VERSION "dbc-export 1 2026.26.6.5"

NS_ :

BS_:

BU_: BMS CP DAS DIF GTW HVP ICR PCS SCCM VCBATT VCFRONT VCFRONT1 VCLEFT VCRIGHT VCSEC

BO_ 1025 BMS_brickMeasurements: 8 BMS
 SG_ BMS_brickVoltageMultiplexer M : 0|8@1+ (1,0) [0|255] "" Vector__XXX
 SG_ BMS_brickVoltageCounter : 14|2@1+ (1,0) [0|3] "" Vector__XXX
 SG_ BMS_brickVoltageStatus1 m0 : 8|2@1+ (1,0) [0|3] "" Vector__XXX
 SG_ BMS_brickVoltageStatus2 m0 : 10|2@1+ (1,0) [0|3] "" Vector__XXX
 SG_ BMS_brickVoltageStatus3 m0 : 12|2@1+ (1,0) [0|3] "" Vector__XXX
 SG_ BMS_brickVoltage1 m0 : 16|16@1+ (0.0001,0) [0|5] "V" Vector__XXX
 SG_ BMS_brickVoltage2 m0 : 32|16@1+ (0.0001,0) [0|5] "V" Vector__XXX
 SG_ BMS_brickVoltage3 m0 : 48|16@1+ (0.0001,0) [0|5] "V" Vector__XXX
 SG_ BMS_brickVoltageStatus4 m1 : 8|2@1+ (1,0) [0|3] "" Vector__XXX
 SG_ BMS_brickVoltageStatus5 m1 : 10|2@1+ (1,0) [0|3] "" Vector__XXX
 SG_ BMS_brickVoltageStatus6 m1 : 12|2@1+ (1,0) [0|3] "" Vector__XXX
 SG_ BMS_brickVoltage4 m1 : 16|16@1+ (0.0001,0) [0|5] "V" Vector__XXX
 SG_ BMS_brickVoltage5 m1 : 32|16@1+ (0.0001,0) [0|5] "V" Vector__XXX
 SG_ BMS_brickVoltage6 m1 : 48|16@1+ (0.0001,0) [0|5] "V" Vector__XXX
 SG_ BMS_brickVoltageStatus7 m2 : 8|2@1+ (1,0) [0|3] "" Vector__XXX
 SG_ BMS_brickVoltageStatus8 m2 : 10|2@1+ (1,0) [0|3] "" Vector__XXX
 SG_ BMS_brickVoltageStatus9 m2 : 12|2@1+ (1,0) [0|3] "" Vector__XXX
 SG_ BMS_brickVoltage7 m2 : 16|16@1+ (0.0001,0) [0|5] "V" Vector__XXX
 SG_ BMS_brickVoltage8 m2 : 32|16@1+ (0.0001,0) [0|5] "V" Vector__XXX
 SG_ BMS_brickVoltage9 m2 : 48|16@1+ (0.0001,0) [0|5] "V" Vector__XXX
 SG_ BMS_brickVoltageStatus10 m3 : 8|2@1+ (1,0) [0|3] "" Vector__XXX
 SG_ BMS_brickVoltageStatus11 m3 : 10|2@1+ (1,0) [0|3] "" Vector__XXX
 SG_ BMS_brickVoltageStatus12 m3 : 12|2@1+ (1,0) [0|3] "" Vector__XXX
 SG_ BMS_brickVoltage10 m3 : 16|16@1+ (0.0001,0) [0|5] "V" Vector__XXX
 SG_ BMS_brickVoltage11 m3 : 32|16@1+ (0.0001,0) [0|5] "V" Vector__XXX
 SG_ BMS_brickVoltage12 m3 : 48|16@1+ (0.0001,0) [0|5] "V" Vector__XXX
 SG_ BMS_brickVoltageStatus13 m4 : 8|2@1+ (1,0) [0|3] "" Vector__XXX
 SG_ BMS_brickVoltageStatus14 m4 : 10|2@1+ (1,0) [0|3] "" Vector__XXX
 SG_ BMS_brickVoltageStatus15 m4 : 12|2@1+ (1,0) [0|3] "" Vector__XXX
 SG_ BMS_brickVoltage13 m4 : 16|16@1+ (0.0001,0) [0|5] "V" Vector__XXX
 SG_ BMS_brickVoltage14 m4 : 32|16@1+ (0.0001,0) [0|5] "V" Vector__XXX
 SG_ BMS_brickVoltage15 m4 : 48|16@1+ (0.0001,0) [0|5] "V" Vector__XXX
 SG_ BMS_brickVoltageStatus16 m5 : 8|2@1+ (1,0) [0|3] "" Vector__XXX
 SG_ BMS_brickVoltageStatus17 m5 : 10|2@1+ (1,0) [0|3] "" Vector__XXX
 SG_ BMS_brickVoltageStatus18 m5 : 12|2@1+ (1,0) [0|3] "" Vector__XXX
 SG_ BMS_brickVoltage16 m5 : 16|16@1+ (0.0001,0) [0|5] "V" Vector__XXX
 SG_ BMS_brickVoltage17 m5 : 32|16@1+ (0.0001,0) [0|5] "V" Vector__XXX
 SG_ BMS_brickVoltage18 m5 : 48|16@1+ (0.0001,0) [0|5] "V" Vector__XXX
 SG_ BMS_brickVoltageStatus19 m6 : 8|2@1+ (1,0) [0|3] "" Vector__XXX
 SG_ BMS_brickVoltageStatus20 m6 : 10|2@1+ (1,0) [0|3] "" Vector__XXX
 SG_ BMS_brickVoltageStatus21 m6 : 12|2@1+ (1,0) [0|3] "" Vector__XXX
 SG_ BMS_brickVoltage19 m6 : 16|16@1+ (0.0001,0) [0|5] "V" Vector__XXX
 SG_ BMS_brickVoltage20 m6 : 32|16@1+ (0.0001,0) [0|5] "V" Vector__XXX
 SG_ BMS_brickVoltage21 m6 : 48|16@1+ (0.0001,0) [0|5] "V" Vector__XXX
 SG_ BMS_brickVoltageStatus22 m7 : 8|2@1+ (1,0) [0|3] "" Vector__XXX
 SG_ BMS_brickVoltageStatus23 m7 : 10|2@1+ (1,0) [0|3] "" Vector__XXX
 SG_ BMS_brickVoltageStatus24 m7 : 12|2@1+ (1,0) [0|3] "" Vector__XXX
 SG_ BMS_brickVoltage22 m7 : 16|16@1+ (0.0001,0) [0|5] "V" Vector__XXX
 SG_ BMS_brickVoltage23 m7 : 32|16@1+ (0.0001,0) [0|5] "V" Vector__XXX
 SG_ BMS_brickVoltage24 m7 : 48|16@1+ (0.0001,0) [0|5] "V" Vector__XXX
 SG_ BMS_brickVoltageStatus25 m8 : 8|2@1+ (1,0) [0|3] "" Vector__XXX
 SG_ BMS_brickVoltageStatus26 m8 : 10|2@1+ (1,0) [0|3] "" Vector__XXX
 SG_ BMS_brickVoltageStatus27 m8 : 12|2@1+ (1,0) [0|3] "" Vector__XXX
 SG_ BMS_brickVoltage25 m8 : 16|16@1+ (0.0001,0) [0|5] "V" Vector__XXX
 SG_ BMS_brickVoltage26 m8 : 32|16@1+ (0.0001,0) [0|5] "V" Vector__XXX
 SG_ BMS_brickVoltage27 m8 : 48|16@1+ (0.0001,0) [0|5] "V" Vector__XXX
 SG_ BMS_brickVoltageStatus28 m9 : 8|2@1+ (1,0) [0|3] "" Vector__XXX
 SG_ BMS_brickVoltageStatus29 m9 : 10|2@1+ (1,0) [0|3] "" Vector__XXX
 SG_ BMS_brickVoltageStatus30 m9 : 12|2@1+ (1,0) [0|3] "" Vector__XXX
 SG_ BMS_brickVoltage28 m9 : 16|16@1+ (0.0001,0) [0|5] "V" Vector__XXX
 SG_ BMS_brickVoltage29 m9 : 32|16@1+ (0.0001,0) [0|5] "V" Vector__XXX
 SG_ BMS_brickVoltage30 m9 : 48|16@1+ (0.0001,0) [0|5] "V" Vector__XXX
 SG_ BMS_brickVoltageStatus31 m10 : 8|2@1+ (1,0) [0|3] "" Vector__XXX
 SG_ BMS_brickVoltageStatus32 m10 : 10|2@1+ (1,0) [0|3] "" Vector__XXX
 SG_ BMS_brickVoltageStatus33 m10 : 12|2@1+ (1,0) [0|3] "" Vector__XXX
 SG_ BMS_brickVoltage31 m10 : 16|16@1+ (0.0001,0) [0|5] "V" Vector__XXX
 SG_ BMS_brickVoltage32 m10 : 32|16@1+ (0.0001,0) [0|5] "V" Vector__XXX
 SG_ BMS_brickVoltage33 m10 : 48|16@1+ (0.0001,0) [0|5] "V" Vector__XXX
 SG_ BMS_brickVoltageStatus34 m11 : 8|2@1+ (1,0) [0|3] "" Vector__XXX
 SG_ BMS_brickVoltageStatus35 m11 : 10|2@1+ (1,0) [0|3] "" Vector__XXX
 SG_ BMS_brickVoltageStatus36 m11 : 12|2@1+ (1,0) [0|3] "" Vector__XXX
 SG_ BMS_brickVoltage34 m11 : 16|16@1+ (0.0001,0) [0|5] "V" Vector__XXX
 SG_ BMS_brickVoltage35 m11 : 32|16@1+ (0.0001,0) [0|5] "V" Vector__XXX
 SG_ BMS_brickVoltage36 m11 : 48|16@1+ (0.0001,0) [0|5] "V" Vector__XXX
 SG_ BMS_brickVoltageStatus37 m12 : 8|2@1+ (1,0) [0|3] "" Vector__XXX
 SG_ BMS_brickVoltageStatus38 m12 : 10|2@1+ (1,0) [0|3] "" Vector__XXX
 SG_ BMS_brickVoltageStatus39 m12 : 12|2@1+ (1,0) [0|3] "" Vector__XXX
 SG_ BMS_brickVoltage37 m12 : 16|16@1+ (0.0001,0) [0|5] "V" Vector__XXX
 SG_ BMS_brickVoltage38 m12 : 32|16@1+ (0.0001,0) [0|5] "V" Vector__XXX
 SG_ BMS_brickVoltage39 m12 : 48|16@1+ (0.0001,0) [0|5] "V" Vector__XXX
 SG_ BMS_brickVoltageStatus40 m13 : 8|2@1+ (1,0) [0|3] "" Vector__XXX
 SG_ BMS_brickVoltageStatus41 m13 : 10|2@1+ (1,0) [0|3] "" Vector__XXX
 SG_ BMS_brickVoltageStatus42 m13 : 12|2@1+ (1,0) [0|3] "" Vector__XXX
 SG_ BMS_brickVoltage40 m13 : 16|16@1+ (0.0001,0) [0|5] "V" Vector__XXX
 SG_ BMS_brickVoltage41 m13 : 32|16@1+ (0.0001,0) [0|5] "V" Vector__XXX
 SG_ BMS_brickVoltage42 m13 : 48|16@1+ (0.0001,0) [0|5] "V" Vector__XXX
 SG_ BMS_brickVoltageStatus43 m14 : 8|2@1+ (1,0) [0|3] "" Vector__XXX
 SG_ BMS_brickVoltageStatus44 m14 : 10|2@1+ (1,0) [0|3] "" Vector__XXX
 SG_ BMS_brickVoltageStatus45 m14 : 12|2@1+ (1,0) [0|3] "" Vector__XXX
 SG_ BMS_brickVoltage43 m14 : 16|16@1+ (0.0001,0) [0|5] "V" Vector__XXX
 SG_ BMS_brickVoltage44 m14 : 32|16@1+ (0.0001,0) [0|5] "V" Vector__XXX
 SG_ BMS_brickVoltage45 m14 : 48|16@1+ (0.0001,0) [0|5] "V" Vector__XXX
 SG_ BMS_brickVoltageStatus46 m15 : 8|2@1+ (1,0) [0|3] "" Vector__XXX
 SG_ BMS_brickVoltageStatus47 m15 : 10|2@1+ (1,0) [0|3] "" Vector__XXX
 SG_ BMS_brickVoltageStatus48 m15 : 12|2@1+ (1,0) [0|3] "" Vector__XXX
 SG_ BMS_brickVoltage46 m15 : 16|16@1+ (0.0001,0) [0|5] "V" Vector__XXX
 SG_ BMS_brickVoltage47 m15 : 32|16@1+ (0.0001,0) [0|5] "V" Vector__XXX
 SG_ BMS_brickVoltage48 m15 : 48|16@1+ (0.0001,0) [0|5] "V" Vector__XXX
 SG_ BMS_brickVoltageStatus49 m16 : 8|2@1+ (1,0) [0|3] "" Vector__XXX
 SG_ BMS_brickVoltageStatus50 m16 : 10|2@1+ (1,0) [0|3] "" Vector__XXX
 SG_ BMS_brickVoltageStatus51 m16 : 12|2@1+ (1,0) [0|3] "" Vector__XXX
 SG_ BMS_brickVoltage49 m16 : 16|16@1+ (0.0001,0) [0|5] "V" Vector__XXX
 SG_ BMS_brickVoltage50 m16 : 32|16@1+ (0.0001,0) [0|5] "V" Vector__XXX
 SG_ BMS_brickVoltage51 m16 : 48|16@1+ (0.0001,0) [0|5] "V" Vector__XXX
 SG_ BMS_brickVoltageStatus52 m17 : 8|2@1+ (1,0) [0|3] "" Vector__XXX
 SG_ BMS_brickVoltageStatus53 m17 : 10|2@1+ (1,0) [0|3] "" Vector__XXX
 SG_ BMS_brickVoltageStatus54 m17 : 12|2@1+ (1,0) [0|3] "" Vector__XXX
 SG_ BMS_brickVoltage52 m17 : 16|16@1+ (0.0001,0) [0|5] "V" Vector__XXX
 SG_ BMS_brickVoltage53 m17 : 32|16@1+ (0.0001,0) [0|5] "V" Vector__XXX
 SG_ BMS_brickVoltage54 m17 : 48|16@1+ (0.0001,0) [0|5] "V" Vector__XXX
 SG_ BMS_brickVoltageStatus55 m18 : 8|2@1+ (1,0) [0|3] "" Vector__XXX
 SG_ BMS_brickVoltageStatus56 m18 : 10|2@1+ (1,0) [0|3] "" Vector__XXX
 SG_ BMS_brickVoltageStatus57 m18 : 12|2@1+ (1,0) [0|3] "" Vector__XXX
 SG_ BMS_brickVoltage55 m18 : 16|16@1+ (0.0001,0) [0|5] "V" Vector__XXX
 SG_ BMS_brickVoltage56 m18 : 32|16@1+ (0.0001,0) [0|5] "V" Vector__XXX
 SG_ BMS_brickVoltage57 m18 : 48|16@1+ (0.0001,0) [0|5] "V" Vector__XXX
 SG_ BMS_brickVoltageStatus58 m19 : 8|2@1+ (1,0) [0|3] "" Vector__XXX
 SG_ BMS_brickVoltageStatus59 m19 : 10|2@1+ (1,0) [0|3] "" Vector__XXX
 SG_ BMS_brickVoltageStatus60 m19 : 12|2@1+ (1,0) [0|3] "" Vector__XXX
 SG_ BMS_brickVoltage58 m19 : 16|16@1+ (0.0001,0) [0|5] "V" Vector__XXX
 SG_ BMS_brickVoltage59 m19 : 32|16@1+ (0.0001,0) [0|5] "V" Vector__XXX
 SG_ BMS_brickVoltage60 m19 : 48|16@1+ (0.0001,0) [0|5] "V" Vector__XXX
 SG_ BMS_brickVoltageStatus61 m20 : 8|2@1+ (1,0) [0|3] "" Vector__XXX
 SG_ BMS_brickVoltageStatus62 m20 : 10|2@1+ (1,0) [0|3] "" Vector__XXX
 SG_ BMS_brickVoltageStatus63 m20 : 12|2@1+ (1,0) [0|3] "" Vector__XXX
 SG_ BMS_brickVoltage61 m20 : 16|16@1+ (0.0001,0) [0|5] "V" Vector__XXX
 SG_ BMS_brickVoltage62 m20 : 32|16@1+ (0.0001,0) [0|5] "V" Vector__XXX
 SG_ BMS_brickVoltage63 m20 : 48|16@1+ (0.0001,0) [0|5] "V" Vector__XXX
 SG_ BMS_brickVoltageStatus64 m21 : 8|2@1+ (1,0) [0|3] "" Vector__XXX
 SG_ BMS_brickVoltageStatus65 m21 : 10|2@1+ (1,0) [0|3] "" Vector__XXX
 SG_ BMS_brickVoltageStatus66 m21 : 12|2@1+ (1,0) [0|3] "" Vector__XXX
 SG_ BMS_brickVoltage64 m21 : 16|16@1+ (0.0001,0) [0|5] "V" Vector__XXX
 SG_ BMS_brickVoltage65 m21 : 32|16@1+ (0.0001,0) [0|5] "V" Vector__XXX
 SG_ BMS_brickVoltage66 m21 : 48|16@1+ (0.0001,0) [0|5] "V" Vector__XXX
 SG_ BMS_brickVoltageStatus67 m22 : 8|2@1+ (1,0) [0|3] "" Vector__XXX
 SG_ BMS_brickVoltageStatus68 m22 : 10|2@1+ (1,0) [0|3] "" Vector__XXX
 SG_ BMS_brickVoltageStatus69 m22 : 12|2@1+ (1,0) [0|3] "" Vector__XXX
 SG_ BMS_brickVoltage67 m22 : 16|16@1+ (0.0001,0) [0|5] "V" Vector__XXX
 SG_ BMS_brickVoltage68 m22 : 32|16@1+ (0.0001,0) [0|5] "V" Vector__XXX
 SG_ BMS_brickVoltage69 m22 : 48|16@1+ (0.0001,0) [0|5] "V" Vector__XXX
 SG_ BMS_brickVoltageStatus70 m23 : 8|2@1+ (1,0) [0|3] "" Vector__XXX
 SG_ BMS_brickVoltageStatus71 m23 : 10|2@1+ (1,0) [0|3] "" Vector__XXX
 SG_ BMS_brickVoltageStatus72 m23 : 12|2@1+ (1,0) [0|3] "" Vector__XXX
 SG_ BMS_brickVoltage70 m23 : 16|16@1+ (0.0001,0) [0|5] "V" Vector__XXX
 SG_ BMS_brickVoltage71 m23 : 32|16@1+ (0.0001,0) [0|5] "V" Vector__XXX
 SG_ BMS_brickVoltage72 m23 : 48|16@1+ (0.0001,0) [0|5] "V" Vector__XXX
 SG_ BMS_brickVoltageStatus73 m24 : 8|2@1+ (1,0) [0|3] "" Vector__XXX
 SG_ BMS_brickVoltageStatus74 m24 : 10|2@1+ (1,0) [0|3] "" Vector__XXX
 SG_ BMS_brickVoltageStatus75 m24 : 12|2@1+ (1,0) [0|3] "" Vector__XXX
 SG_ BMS_brickVoltage73 m24 : 16|16@1+ (0.0001,0) [0|5] "V" Vector__XXX
 SG_ BMS_brickVoltage74 m24 : 32|16@1+ (0.0001,0) [0|5] "V" Vector__XXX
 SG_ BMS_brickVoltage75 m24 : 48|16@1+ (0.0001,0) [0|5] "V" Vector__XXX
 SG_ BMS_brickVoltageStatus76 m25 : 8|2@1+ (1,0) [0|3] "" Vector__XXX
 SG_ BMS_brickVoltageStatus77 m25 : 10|2@1+ (1,0) [0|3] "" Vector__XXX
 SG_ BMS_brickVoltageStatus78 m25 : 12|2@1+ (1,0) [0|3] "" Vector__XXX
 SG_ BMS_brickVoltage76 m25 : 16|16@1+ (0.0001,0) [0|5] "V" Vector__XXX
 SG_ BMS_brickVoltage77 m25 : 32|16@1+ (0.0001,0) [0|5] "V" Vector__XXX
 SG_ BMS_brickVoltage78 m25 : 48|16@1+ (0.0001,0) [0|5] "V" Vector__XXX
 SG_ BMS_brickVoltageStatus79 m26 : 8|2@1+ (1,0) [0|3] "" Vector__XXX
 SG_ BMS_brickVoltageStatus80 m26 : 10|2@1+ (1,0) [0|3] "" Vector__XXX
 SG_ BMS_brickVoltageStatus81 m26 : 12|2@1+ (1,0) [0|3] "" Vector__XXX
 SG_ BMS_brickVoltage79 m26 : 16|16@1+ (0.0001,0) [0|5] "V" Vector__XXX
 SG_ BMS_brickVoltage80 m26 : 32|16@1+ (0.0001,0) [0|5] "V" Vector__XXX
 SG_ BMS_brickVoltage81 m26 : 48|16@1+ (0.0001,0) [0|5] "V" Vector__XXX
 SG_ BMS_brickVoltageStatus82 m27 : 8|2@1+ (1,0) [0|3] "" Vector__XXX
 SG_ BMS_brickVoltageStatus83 m27 : 10|2@1+ (1,0) [0|3] "" Vector__XXX
 SG_ BMS_brickVoltageStatus84 m27 : 12|2@1+ (1,0) [0|3] "" Vector__XXX
 SG_ BMS_brickVoltage82 m27 : 16|16@1+ (0.0001,0) [0|5] "V" Vector__XXX
 SG_ BMS_brickVoltage83 m27 : 32|16@1+ (0.0001,0) [0|5] "V" Vector__XXX
 SG_ BMS_brickVoltage84 m27 : 48|16@1+ (0.0001,0) [0|5] "V" Vector__XXX
 SG_ BMS_brickVoltageStatus85 m28 : 8|2@1+ (1,0) [0|3] "" Vector__XXX
 SG_ BMS_brickVoltageStatus86 m28 : 10|2@1+ (1,0) [0|3] "" Vector__XXX
 SG_ BMS_brickVoltageStatus87 m28 : 12|2@1+ (1,0) [0|3] "" Vector__XXX
 SG_ BMS_brickVoltage85 m28 : 16|16@1+ (0.0001,0) [0|5] "V" Vector__XXX
 SG_ BMS_brickVoltage86 m28 : 32|16@1+ (0.0001,0) [0|5] "V" Vector__XXX
 SG_ BMS_brickVoltage87 m28 : 48|16@1+ (0.0001,0) [0|5] "V" Vector__XXX
 SG_ BMS_brickVoltageStatus88 m29 : 8|2@1+ (1,0) [0|3] "" Vector__XXX
 SG_ BMS_brickVoltageStatus89 m29 : 10|2@1+ (1,0) [0|3] "" Vector__XXX
 SG_ BMS_brickVoltageStatus90 m29 : 12|2@1+ (1,0) [0|3] "" Vector__XXX
 SG_ BMS_brickVoltage88 m29 : 16|16@1+ (0.0001,0) [0|5] "V" Vector__XXX
 SG_ BMS_brickVoltage89 m29 : 32|16@1+ (0.0001,0) [0|5] "V" Vector__XXX
 SG_ BMS_brickVoltage90 m29 : 48|16@1+ (0.0001,0) [0|5] "V" Vector__XXX
 SG_ BMS_brickVoltageStatus91 m30 : 8|2@1+ (1,0) [0|3] "" Vector__XXX
 SG_ BMS_brickVoltageStatus92 m30 : 10|2@1+ (1,0) [0|3] "" Vector__XXX
 SG_ BMS_brickVoltageStatus93 m30 : 12|2@1+ (1,0) [0|3] "" Vector__XXX
 SG_ BMS_brickVoltage91 m30 : 16|16@1+ (0.0001,0) [0|5] "V" Vector__XXX
 SG_ BMS_brickVoltage92 m30 : 32|16@1+ (0.0001,0) [0|5] "V" Vector__XXX
 SG_ BMS_brickVoltage93 m30 : 48|16@1+ (0.0001,0) [0|5] "V" Vector__XXX
 SG_ BMS_brickVoltageStatus94 m31 : 8|2@1+ (1,0) [0|3] "" Vector__XXX
 SG_ BMS_brickVoltageStatus95 m31 : 10|2@1+ (1,0) [0|3] "" Vector__XXX
 SG_ BMS_brickVoltageStatus96 m31 : 12|2@1+ (1,0) [0|3] "" Vector__XXX
 SG_ BMS_brickVoltage94 m31 : 16|16@1+ (0.0001,0) [0|5] "V" Vector__XXX
 SG_ BMS_brickVoltage95 m31 : 32|16@1+ (0.0001,0) [0|5] "V" Vector__XXX
 SG_ BMS_brickVoltage96 m31 : 48|16@1+ (0.0001,0) [0|5] "V" Vector__XXX
 SG_ BMS_brickVoltageStatus97 m32 : 8|2@1+ (1,0) [0|3] "" Vector__XXX
 SG_ BMS_brickVoltageStatus98 m32 : 10|2@1+ (1,0) [0|3] "" Vector__XXX
 SG_ BMS_brickVoltageStatus99 m32 : 12|2@1+ (1,0) [0|3] "" Vector__XXX
 SG_ BMS_brickVoltage97 m32 : 16|16@1+ (0.0001,0) [0|5] "V" Vector__XXX
 SG_ BMS_brickVoltage98 m32 : 32|16@1+ (0.0001,0) [0|5] "V" Vector__XXX
 SG_ BMS_brickVoltage99 m32 : 48|16@1+ (0.0001,0) [0|5] "V" Vector__XXX
 SG_ BMS_brickVoltageStatus100 m33 : 8|2@1+ (1,0) [0|3] "" Vector__XXX
 SG_ BMS_brickVoltageStatus101 m33 : 10|2@1+ (1,0) [0|3] "" Vector__XXX
 SG_ BMS_brickVoltageStatus102 m33 : 12|2@1+ (1,0) [0|3] "" Vector__XXX
 SG_ BMS_brickVoltage100 m33 : 16|16@1+ (0.0001,0) [0|5] "V" Vector__XXX
 SG_ BMS_brickVoltage101 m33 : 32|16@1+ (0.0001,0) [0|5] "V" Vector__XXX
 SG_ BMS_brickVoltage102 m33 : 48|16@1+ (0.0001,0) [0|5] "V" Vector__XXX
 SG_ BMS_brickVoltageStatus103 m34 : 8|2@1+ (1,0) [0|3] "" Vector__XXX
 SG_ BMS_brickVoltageStatus104 m34 : 10|2@1+ (1,0) [0|3] "" Vector__XXX
 SG_ BMS_brickVoltageStatus105 m34 : 12|2@1+ (1,0) [0|3] "" Vector__XXX
 SG_ BMS_brickVoltage103 m34 : 16|16@1+ (0.0001,0) [0|5] "V" Vector__XXX
 SG_ BMS_brickVoltage104 m34 : 32|16@1+ (0.0001,0) [0|5] "V" Vector__XXX
 SG_ BMS_brickVoltage105 m34 : 48|16@1+ (0.0001,0) [0|5] "V" Vector__XXX
 SG_ BMS_brickVoltageStatus106 m35 : 8|2@1+ (1,0) [0|3] "" Vector__XXX
 SG_ BMS_brickVoltageStatus107 m35 : 10|2@1+ (1,0) [0|3] "" Vector__XXX
 SG_ BMS_brickVoltageStatus108 m35 : 12|2@1+ (1,0) [0|3] "" Vector__XXX
 SG_ BMS_brickVoltage106 m35 : 16|16@1+ (0.0001,0) [0|5] "V" Vector__XXX
 SG_ BMS_brickVoltage107 m35 : 32|16@1+ (0.0001,0) [0|5] "V" Vector__XXX
 SG_ BMS_brickVoltage108 m35 : 48|16@1+ (0.0001,0) [0|5] "V" Vector__XXX

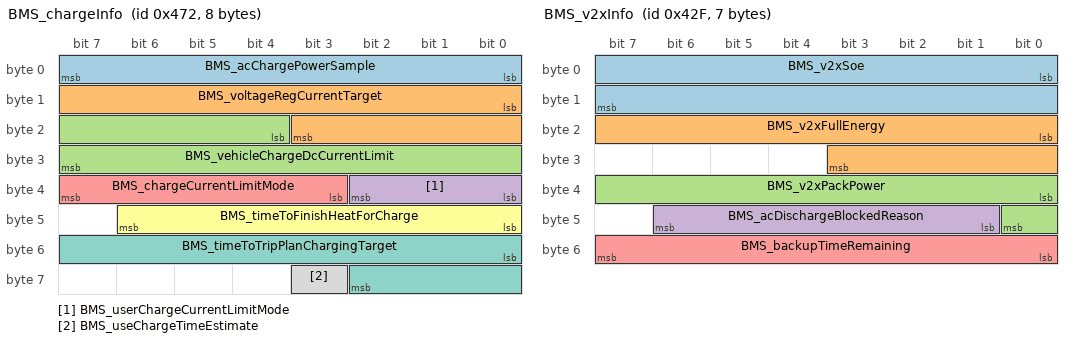
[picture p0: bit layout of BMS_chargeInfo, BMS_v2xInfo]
BO_ 1138 BMS_chargeInfo: 8 BMS
 SG_ BMS_acChargePowerSample : 0|8@1+ (0.1,0) [0|25] "kW" Vector__XXX
 SG_ BMS_voltageRegCurrentTarget : 8|12@1+ (0.5,0) [0|2047.5] "A" Vector__XXX
 SG_ BMS_vehicleChargeDcCurrentLimit : 20|12@1+ (0.5,0) [0|2047.5] "A" Vector__XXX
 SG_ BMS_userChargeCurrentLimitMode : 32|3@1+ (1,0) [0|7] "" Vector__XXX
 SG_ BMS_chargeCurrentLimitMode : 35|5@1+ (1,0) [0|31] "" Vector__XXX
 SG_ BMS_timeToFinishHeatForCharge : 40|7@1+ (5,0) [0|600] "min" Vector__XXX
 SG_ BMS_timeToTripPlanChargingTarget : 48|11@1+ (1,0) [0|2046] "min" Vector__XXX
 SG_ BMS_useChargeTimeEstimate : 59|1@1+ (1,0) [0|1] "" Vector__XXX

BO_ 1071 BMS_v2xInfo: 7 BMS
 SG_ BMS_v2xSoe : 0|16@1+ (0.002,0) [0|100] "%" Vector__XXX
 SG_ BMS_v2xFullEnergy : 16|12@1+ (0.05,0) [0|200] "kWh" Vector__XXX
 SG_ BMS_v2xPackPower : 32|9@1+ (0.1,-25) [-25|25] "kW" Vector__XXX
 SG_ BMS_acDischargeBlockedReason : 41|6@1+ (1,0) [0|63] "" Vector__XXX
 SG_ BMS_backupTimeRemaining : 48|8@1+ (1,0) [0|254] "Hours" Vector__XXX

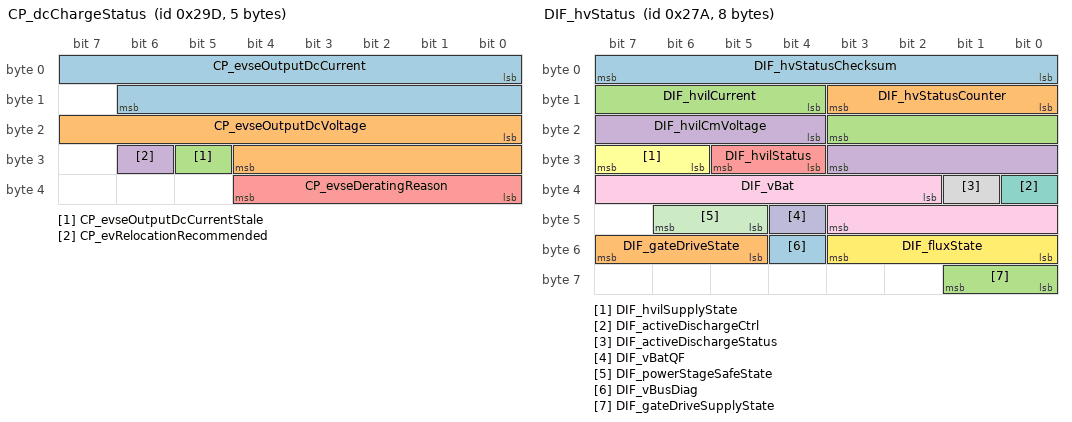
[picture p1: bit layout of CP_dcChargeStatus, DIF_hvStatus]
BO_ 669 CP_dcChargeStatus: 5 CP
 SG_ CP_evseOutputDcCurrent : 0|15@1- (0.125,0) [-2048|2047.875] "A" Vector__XXX
 SG_ CP_evseOutputDcVoltage : 16|13@1+ (0.07324219,0) [0|599.92675822] "V" Vector__XXX
 SG_ CP_evseOutputDcCurrentStale : 29|1@1+ (1,0) [0|1] "" Vector__XXX
 SG_ CP_evRelocationRecommended : 30|1@1+ (1,0) [0|1] "" Vector__XXX
 SG_ CP_evseDeratingReason : 32|5@1+ (1,0) [0|31] "" Vector__XXX

BO_ 541 CP_evseStatus: 8 CP
 SG_ CP_evseAccept : 0|1@1+ (1,0) [0|1] "" Vector__XXX
 SG_ CP_evseRequest : 1|1@1+ (1,0) [0|1] "" Vector__XXX
 SG_ CP_proximity : 2|2@1+ (1,0) [1|3] "" Vector__XXX
 SG_ CP_pilot : 4|3@1+ (1,0) [0|6] "" Vector__XXX
 SG_ CP_digitalCommsEstablished : 7|1@1+ (1,0) [0|1] "" Vector__XXX
 SG_ CP_pilotCurrent : 8|8@1+ (0.5,0) [0|127.5] "A" Vector__XXX
 SG_ CP_cableType : 16|3@1+ (1,0) [0|7] "" Vector__XXX
 SG_ CP_iecPilotState : 19|4@1+ (1,0) [0|15] "" Vector__XXX
 SG_ CP_plcSupported : 23|1@1+ (1,0) [0|1] "" Vector__XXX
 SG_ CP_cableCurrentLimit : 24|7@1+ (1,0) [0|127] "A" Vector__XXX
 SG_ CP_teslaSwcanState : 34|4@1+ (1,0) [0|15] "" Vector__XXX
 SG_ CP_evseChargeType_UI : 38|2@1+ (1,0) [0|3] "" Vector__XXX
 SG_ CP_gbState : 40|4@1+ (1,0) [0|15] "" Vector__XXX
 SG_ CP_gbdcStopChargeReason : 44|4@1+ (1,0) [0|15] "" Vector__XXX
 SG_ CP_gbdcFailureReason : 48|2@1+ (1,0) [0|3] "" Vector__XXX
 SG_ CP_gbdcChargeAttempts : 50|2@1+ (1,0) [0|3] "" Vector__XXX
 SG_ CP_acChargeState : 52|3@1+ (1,0) [0|7] "" Vector__XXX
 SG_ CP_acChargeType : 56|2@1+ (1,0) [0|3] "" Vector__XXX
 SG_ CP_teslaDcState : 58|4@1+ (1,0) [0|15] "" Vector__XXX

BO_ 1001 DAS_bodyControls: 8 DAS
 SG_ DAS_headlightRequest : 0|2@1+ (1,0) [0|3] "" Vector__XXX
 SG_ DAS_hazardLightRequest : 2|2@1+ (1,0) [0|2] "" Vector__XXX
 SG_ DAS_wiperSpeed : 4|4@1+ (1,0) [0|15] "" Vector__XXX
 SG_ DAS_turnIndicatorRequest : 8|3@1+ (1,0) [0|7] "" Vector__XXX
 SG_ DAS_highLowBeamDecision : 11|2@1+ (1,0) [0|2] "" Vector__XXX
 SG_ DAS_heaterRequest : 13|2@1+ (1,0) [1|3] "" Vector__XXX
 SG_ DAS_highLowBeamOffReason : 15|3@1+ (1,0) [0|7] "" Vector__XXX
 SG_ DAS_forwardCamHeaterDutyCycle : 18|4@1+ (0.06666667,0) [0|1] "-" Vector__XXX
 SG_ DAS_dynamicBrakeLightRequest : 22|1@1+ (1,0) [0|1] "" Vector__XXX
 SG_ DAS_radarHeaterRequest : 23|1@1+ (1,0) [0|1] "" Vector__XXX
 SG_ DAS_ahlbOverride : 24|1@1+ (1,0) [0|1] "" Vector__XXX
 SG_ DAS_mirrorFoldRequest : 25|2@1+ (1,0) [0|2] "" Vector__XXX
 SG_ DAS_wiperWashRequest : 27|1@1+ (1,0) [0|1] "" Vector__XXX
 SG_ DAS_ulcConfirmationRequestActive : 28|1@1+ (1,0) [0|1] "" Vector__XXX
 SG_ DAS_overrideWiperSetting : 29|1@1+ (1,0) [0|1] "" Vector__XXX
 SG_ DAS_autoWiperState : 30|3@1+ (1,0) [0|7] "" Vector__XXX
 SG_ DAS_turnIndicatorRequestReason : 33|5@1+ (1,0) [0|31] "" Vector__XXX
 SG_ DAS_forwardRadarPowerRequest : 38|1@1+ (1,0) [0|1] "" Vector__XXX
 SG_ DAS_driverDomeLightRequest : 39|1@1+ (1,0) [0|1] "" Vector__XXX
 SG_ DAS_drivePowerStateRequest : 43|1@1+ (1,0) [0|1] "" Vector__XXX
 SG_ DAS_enableIcrDataCollection : 44|1@1+ (1,0) [0|1] "" Vector__XXX
 SG_ DAS_rPillarCamHeaterDutyCycle : 45|4@1+ (0.06666667,0) [0|1] "-" Vector__XXX
 SG_ DAS_adaptiveHighBeamIsFaulted : 49|1@1+ (1,0) [0|1] "" Vector__XXX
 SG_ DAS_restrictDoorReleaseLeft : 50|1@1+ (1,0) [0|1] "" Vector__XXX
 SG_ DAS_restrictDoorReleaseRight : 51|1@1+ (1,0) [0|1] "" Vector__XXX
 SG_ DAS_bodyControlsCounter : 52|4@1+ (1,0) [0|15] "" Vector__XXX
 SG_ DAS_bodyControlsChecksum : 56|8@1+ (1,0) [0|255] "" Vector__XXX

BO_ 634 DIF_hvStatus: 8 DIF
 SG_ DIF_hvStatusChecksum : 0|8@1+ (1,0) [0|255] "" Vector__XXX
 SG_ DIF_hvStatusCounter : 8|4@1+ (1,0) [0|15] "" Vector__XXX
 SG_ DIF_hvilCurrent : 12|8@1+ (0.1,0) [0|25.5] "mA" Vector__XXX
 SG_ DIF_hvilCmVoltage : 20|8@1+ (0.08,0) [0|20.4] "V" Vector__XXX
 SG_ DIF_hvilStatus : 28|2@1+ (1,0) [0|2] "" Vector__XXX
 SG_ DIF_hvilSupplyState : 30|2@1+ (1,0) [0|3] "" Vector__XXX
 SG_ DIF_activeDischargeCtrl : 32|1@1+ (1,0) [0|1] "" Vector__XXX
 SG_ DIF_activeDischargeStatus : 33|1@1+ (1,0) [0|1] "" Vector__XXX
 SG_ DIF_vBat : 34|10@1+ (1,0) [0|1023] "V" Vector__XXX
 SG_ DIF_vBatQF : 44|1@1+ (1,0) [0|1] "" Vector__XXX
 SG_ DIF_powerStageSafeState : 45|2@1+ (1,0) [0|3] "" Vector__XXX
 SG_ DIF_fluxState : 48|4@1+ (1,0) [0|15] "" Vector__XXX
 SG_ DIF_vBusDiag : 52|1@1+ (1,0) [0|1] "" Vector__XXX
 SG_ DIF_gateDriveState : 53|3@1+ (1,0) [0|7] "" Vector__XXX
 SG_ DIF_gateDriveSupplyState : 56|2@1+ (1,0) [0|3] "" Vector__XXX

BO_ 784 HVP_info: 8 HVP
 SG_ HVP_infoIndex M : 0|8@1+ (1,0) [0|255] "" Vector__XXX
 SG_ HVP_buildType m10 : 8|3@1+ (1,0) [0|7] "" Vector__XXX
 SG_ HVP_buildConfigId m10 : 16|16@1+ (1,0) [0|65535] "" Vector__XXX
 SG_ HVP_hardwareId m10 : 32|16@1+ (1,0) [0|65535] "" Vector__XXX
 SG_ HVP_componentId m10 : 48|16@1+ (1,0) [0|65535] "" Vector__XXX
 SG_ HVP_pcbaId m11 : 16|8@1+ (1,0) [0|255] "" Vector__XXX
 SG_ HVP_assemblyId m11 : 24|8@1+ (1,0) [0|255] "" Vector__XXX
 SG_ HVP_usageId m11 : 32|16@1+ (1,0) [0|65535] "" Vector__XXX
 SG_ HVP_subUsageId m11 : 48|16@1+ (1,0) [0|65535] "" Vector__XXX
 SG_ HVP_platformType m13 : 8|8@1+ (1,0) [0|255] "" Vector__XXX
 SG_ HVP_appCrc m13 : 32|32@1+ (1,0) [0|4294967295] "" Vector__XXX
 SG_ HVP_appGitHash m17 : 8|56@1+ (1,0) [0|7.20575940379e+16] "" Vector__XXX
 SG_ HVP_bootGitHash m18 : 8|56@1+ (1,0) [0|7.20575940379e+16] "" Vector__XXX
 SG_ HVP_bootUdsProtoVersion m20 : 8|8@1+ (1,0) [0|255] "" Vector__XXX
 SG_ HVP_bootCrc m20 : 32|32@1+ (1,0) [0|4294967295] "" Vector__XXX

BO_ 941 ICR_info: 8 ICR
 SG_ ICR_infoIndex M : 0|8@1+ (1,0) [0|255] "" Vector__XXX
 SG_ ICR_infoBuildType m10 : 8|3@1+ (1,0) [0|7] "" Vector__XXX
 SG_ ICR_infoPcbaId m11 : 32|8@1+ (1,0) [0|255] "" Vector__XXX
 SG_ ICR_infoAssemblyId m11 : 40|8@1+ (1,0) [0|255] "" Vector__XXX
 SG_ ICR_infoUsageId m11 : 48|16@1+ (1,0) [0|65535] "" Vector__XXX
 SG_ ICR_infoAppCrc m13 : 8|32@1+ (1,0) [0|4294967295] "" Vector__XXX
 SG_ ICR_infoBoardPartNumber17 m25 : 8|56@1+ (1,0) [0|7.20575940379e+16] "" Vector__XXX
 SG_ ICR_infoBoardPartNumber814 m26 : 8|56@1+ (1,0) [0|7.20575940379e+16] "" Vector__XXX
 SG_ ICR_infoBoardPartNumber1520 m27 : 8|48@1+ (1,0) [0|281474976710655] "" Vector__XXX

BO_ 964 PCS_info: 8 PCS
 SG_ PCS_infoIndex M : 0|8@1+ (1,0) [0|255] "" Vector__XXX
 SG_ PCS_buildType m10 : 8|8@1+ (1,0) [0|255] "" Vector__XXX
 SG_ PCS_buildConfigId m10 : 16|16@1+ (1,0) [0|65535] "" Vector__XXX
 SG_ PCS_hardwareId m10 : 32|16@1+ (1,0) [0|65535] "" Vector__XXX
 SG_ PCS_componentId m10 : 48|16@1+ (1,0) [0|65535] "" Vector__XXX
 SG_ PCS_pcbaId m11 : 16|8@1+ (1,0) [0|255] "" Vector__XXX
 SG_ PCS_assemblyId m11 : 24|8@1+ (1,0) [0|255] "" Vector__XXX
 SG_ PCS_usageId m11 : 32|16@1+ (1,0) [0|65535] "" Vector__XXX
 SG_ PCS_subUsageId m11 : 48|16@1+ (1,0) [0|65535] "" Vector__XXX
 SG_ PCS_platformType m13 : 8|8@1+ (1,0) [0|255] "" Vector__XXX
 SG_ PCS_appCrc m13 : 32|32@1+ (1,0) [0|4294967295] "" Vector__XXX
 SG_ PCS_cpu2AppCrc m16 : 32|32@1+ (1,0) [0|4294967295] "" Vector__XXX
 SG_ PCS_appGitHash m17 : 8|56@1+ (1,0) [0|7.20575940379e+16] "" Vector__XXX
 SG_ PCS_bootGitHash m18 : 8|56@1+ (1,0) [0|7.20575940379e+16] "" Vector__XXX
 SG_ PCS_bootUdsProtoVersion m20 : 8|8@1+ (1,0) [0|255] "" Vector__XXX
 SG_ PCS_bootCrc m20 : 32|32@1+ (1,0) [0|4294967295] "" Vector__XXX

BO_ 816 SCCM_info: 8 SCCM
 SG_ SCCM_infoIndex M : 0|8@1+ (1,0) [0|255] "" Vector__XXX
 SG_ SCCM_infoBuildType m10 : 8|8@1+ (1,0) [0|255] "" Vector__XXX
 SG_ SCCM_infoBuildConfigId m10 : 16|16@1+ (1,0) [0|65535] "" Vector__XXX
 SG_ SCCM_infoHardwareId m10 : 32|16@1+ (1,0) [0|65535] "" Vector__XXX
 SG_ SCCM_infoComponentId m10 : 48|16@1+ (1,0) [0|65535] "" Vector__XXX
 SG_ SCCM_infoPcbaId m11 : 16|8@1+ (1,0) [0|255] "" Vector__XXX
 SG_ SCCM_infoAssemblyId m11 : 24|8@1+ (1,0) [0|255] "" Vector__XXX
 SG_ SCCM_infoUsageId m11 : 32|16@1+ (1,0) [0|65535] "" Vector__XXX
 SG_ SCCM_infoSubUsageId m11 : 48|16@1+ (1,0) [0|65535] "" Vector__XXX
 SG_ SCCM_infoPlatformType m13 : 8|8@1+ (1,0) [0|255] "" Vector__XXX
 SG_ SCCM_infoAppCrc m13 : 39|32@0+ (1,0) [0|4294967295] "" Vector__XXX
 SG_ SCCM_infoBootSvnRev m14 : 8|24@1+ (1,0) [0|16777215] "" Vector__XXX
 SG_ SCCM_infoBootSvnUrlHash m14 : 32|32@1+ (1,0) [0|4294967295] "" Vector__XXX
 SG_ SCCM_infoSubcomponent1Version m16 : 16|32@1+ (1,0) [0|4294967295] "" Vector__XXX
 SG_ SCCM_infoAppSvnHash m17 : 8|56@1+ (1,0) [0|7.20575940379e+16] "" Vector__XXX
 SG_ SCCM_infoBootSvnHash m18 : 8|56@1+ (1,0) [0|7.20575940379e+16] "" Vector__XXX
 SG_ SCCM_infoUdsProtoVersion m20 : 8|8@1+ (1,0) [0|255] "" Vector__XXX
 SG_ SCCM_infoBootCrc m20 : 32|32@1+ (1,0) [0|4294967295] "" Vector__XXX

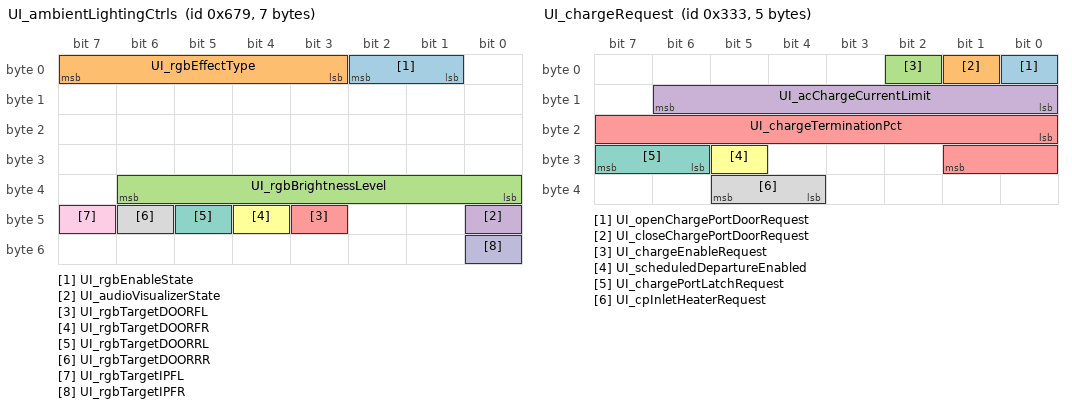
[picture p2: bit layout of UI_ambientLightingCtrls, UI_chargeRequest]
BO_ 1657 UI_ambientLightingCtrls: 7 GTW
 SG_ UI_rgbEnableState : 1|2@1+ (1,0) [0|3] "" Vector__XXX
 SG_ UI_rgbEffectType : 3|5@1+ (1,0) [0|31] "" Vector__XXX
 SG_ UI_rgbBrightnessLevel : 32|7@1+ (1,0) [0|100] "%" Vector__XXX
 SG_ UI_audioVisualizerState : 40|1@1+ (1,0) [0|1] "" Vector__XXX
 SG_ UI_rgbTargetDOORFL : 43|1@1+ (1,0) [0|1] "" Vector__XXX
 SG_ UI_rgbTargetDOORFR : 44|1@1+ (1,0) [0|1] "" Vector__XXX
 SG_ UI_rgbTargetDOORRL : 45|1@1+ (1,0) [0|1] "" Vector__XXX
 SG_ UI_rgbTargetDOORRR : 46|1@1+ (1,0) [0|1] "" Vector__XXX
 SG_ UI_rgbTargetIPFL : 47|1@1+ (1,0) [0|1] "" Vector__XXX
 SG_ UI_rgbTargetIPFR : 48|1@1+ (1,0) [0|1] "" Vector__XXX

BO_ 819 UI_chargeRequest: 5 GTW
 SG_ UI_openChargePortDoorRequest : 0|1@1+ (1,0) [0|1] "" Vector__XXX
 SG_ UI_closeChargePortDoorRequest : 1|1@1+ (1,0) [0|1] "" Vector__XXX
 SG_ UI_chargeEnableRequest : 2|1@1+ (1,0) [0|1] "" Vector__XXX
 SG_ UI_acChargeCurrentLimit : 8|7@1+ (1,0) [0|126] "A" Vector__XXX
 SG_ UI_chargeTerminationPct : 16|10@1+ (0.1,0) [5|100] "%" Vector__XXX
 SG_ UI_scheduledDepartureEnabled : 29|1@1+ (1,0) [0|1] "" Vector__XXX
 SG_ UI_chargePortLatchRequest : 30|2@1+ (1,0) [0|3] "" Vector__XXX
 SG_ UI_cpInletHeaterRequest : 36|2@1+ (1,0) [0|3] "" Vector__XXX

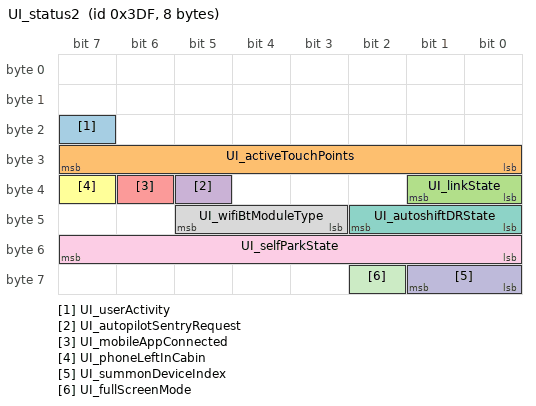
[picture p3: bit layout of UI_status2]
BO_ 991 UI_status2: 8 GTW
 SG_ UI_userActivity : 23|1@1+ (1,0) [0|1] "" Vector__XXX
 SG_ UI_activeTouchPoints : 24|8@1+ (1,0) [0|255] "1" Vector__XXX
 SG_ UI_linkState : 32|2@1+ (1,0) [0|3] "" Vector__XXX
 SG_ UI_autopilotSentryRequest : 37|1@1+ (1,0) [0|1] "" Vector__XXX
 SG_ UI_mobileAppConnected : 38|1@1+ (1,0) [0|1] "" Vector__XXX
 SG_ UI_phoneLeftInCabin : 39|1@1+ (1,0) [0|1] "" Vector__XXX
 SG_ UI_autoshiftDRState : 40|3@1+ (1,0) [0|7] "" Vector__XXX
 SG_ UI_wifiBtModuleType : 43|3@1+ (1,0) [0|7] "" Vector__XXX
 SG_ UI_selfParkState : 48|8@1+ (1,0) [0|254] "" Vector__XXX
 SG_ UI_summonDeviceIndex : 56|2@1+ (1,0) [0|3] "" Vector__XXX
 SG_ UI_fullScreenMode : 58|1@1+ (1,0) [0|1] "" Vector__XXX

BO_ 663 UI_suspensionControl: 8 GTW
 SG_ UI_adaptiveRideRequest : 3|2@1+ (1,0) [0|3] "" Vector__XXX
 SG_ UI_geofenceLevelingRequest : 7|3@1+ (1,0) [0|7] "" Vector__XXX

BO_ 947 UI_vehicleControl2: 8 GTW
 SG_ UI_gloveboxRequest : 0|1@1+ (1,0) [0|1] "" Vector__XXX
 SG_ UI_trunkRequest : 1|1@1+ (1,0) [0|1] "" Vector__XXX
 SG_ UI_PINToDriveEnabled : 6|1@1+ (1,0) [0|1] "" Vector__XXX
 SG_ UI_PINToDrivePassed : 7|1@1+ (1,0) [0|1] "" Vector__XXX
 SG_ UI_disableMirrorAutoDim : 8|1@1+ (1,0) [0|1] "" Vector__XXX
 SG_ UI_lightSwitch : 9|3@1+ (1,0) [0|7] "" Vector__XXX
 SG_ UI_readyToAddKey : 12|1@1+ (1,0) [0|1] "" Vector__XXX
 SG_ UI_alarmTriggerRequest : 13|1@1+ (1,0) [0|1] "" Vector__XXX
 SG_ UI_displayOnForUser : 18|1@1+ (1,0) [0|1] "" Vector__XXX
 SG_ UI_BLEPushNotificationRequest : 20|1@1+ (1,0) [0|1] "" Vector__XXX
 SG_ UI_keepAutopilotAwake : 22|1@1+ (1,0) [0|1] "" Vector__XXX
 SG_ UI_batteryPreconditioningRequest : 23|1@1+ (1,0) [0|1] "" Vector__XXX
 SG_ UI_autopilotPowerStateRequest : 25|2@1+ (1,0) [0|3] "" Vector__XXX
 SG_ UI_autoRollWindowsOnLockEnable : 29|1@1+ (1,0) [0|1] "" Vector__XXX
 SG_ UI_steeringWheelHeatReq : 33|1@1+ (1,0) [0|1] "" Vector__XXX
 SG_ UI_disableHorn : 34|1@1+ (1,0) [0|1] "" Vector__XXX
 SG_ UI_frontLeftSeatFanReq : 37|2@1+ (1,0) [0|3] "" Vector__XXX
 SG_ UI_frontRightSeatAutoClimateReq : 39|1@1+ (1,0) [0|1] "" Vector__XXX
 SG_ UI_frontRightSeatFanReq : 40|2@1+ (1,0) [0|3] "" Vector__XXX
 SG_ UI_3RLeftSeatHeatReq : 44|2@1+ (1,0) [0|3] "" Vector__XXX
 SG_ UI_3RRightSeatHeatReq : 46|2@1+ (1,0) [0|3] "" Vector__XXX
 SG_ UI_frontLeftSeatAutoClimateReq : 56|1@1+ (1,0) [0|1] "" Vector__XXX
 SG_ UI_wiperHeaterReq : 57|1@1+ (1,0) [0|1] "" Vector__XXX
 SG_ UI_silentAlarm : 61|1@1+ (1,0) [0|1] "" Vector__XXX

BO_ 1090 VCBATT_pcsInterface: 8 VCBATT
 SG_ VCBATT_pcsInterfaceMuxIndex M : 48|1@1+ (1,0) [0|1] "" Vector__XXX
 SG_ VCBATT_pcsInterfaceCounter : 50|4@1+ (1,0) [0|15] "" Vector__XXX
 SG_ VCBATT_pcsInterfaceChecksum : 56|8@1+ (1,0) [0|255] "" Vector__XXX
 SG_ VCBATT_pcsLVVoltageTarget m0 : 0|13@1+ (0.01,0) [0|65.535] "V" Vector__XXX
 SG_ VCBATT_pcsLVMinVoltageLimit m0 : 13|13@1+ (0.01,0) [0|65.535] "V" Vector__XXX
 SG_ VCBATT_pcsLVMaxVoltageLimit m0 : 27|13@1+ (0.01,0) [0|65.535] "V" Vector__XXX
 SG_ VCBATT_goodForPCSPowerCycle m0 : 46|1@1+ (1,0) [0|1] "" Vector__XXX
 SG_ VCBATT_LVBatteryCannotSupportVeh m0 : 47|1@1+ (1,0) [0|1] "" Vector__XXX
 SG_ VCBATT_pcsResistanceFiltered m1 : 0|16@1+ (0.01,0) [0|655.34] "mOhm" Vector__XXX
 SG_ VCBATT_pcsLVMaxDchrgCurrentLimit m1 : 16|12@1+ (0.1,0) [0|400] "A" Vector__XXX
 SG_ VCBATT_defaultPcsLVVoltageTarget m1 : 28|13@1+ (0.01,0) [0|65.535] "V" Vector__XXX
 SG_ VCBATT_lvHwProtSelfTestActive m1 : 41|1@1+ (1,0) [0|1] "" Vector__XXX
 SG_ VCBATT_lvBatteryDischargeRequest m1 : 42|1@1+ (1,0) [0|1] "" Vector__XXX

BO_ 1027 VCFRONT1_eFuseDebugStatus: 7 VCFRONT1
 SG_ VCFRONT1_eFuseDebugStatusIndex M : 0|3@1+ (1,0) [0|7] "" Vector__XXX
 SG_ VCFRONT1_EPAS2EFuseState m0 : 3|3@1+ (1,0) [0|7] "" Vector__XXX
 SG_ VCFRONT1_EPAS2EFuseCurrent m0 : 8|12@1+ (0.05,0) [0|204.75] "A" Vector__XXX
 SG_ VCFRONT1_EPAS2EFuseOutput m0 : 20|1@1+ (1,0) [0|1] "" Vector__XXX
 SG_ VCFRONT1_EPAS2EFuseOutputDesired m0 : 21|1@1+ (1,0) [0|1] "" Vector__XXX
 SG_ VCFRONT1_EPAS2EFuseBypass m0 : 22|1@1+ (1,0) [0|1] "" Vector__XXX
 SG_ VCFRONT1_EPAS2EFuseBypassDesired m0 : 23|1@1+ (1,0) [0|1] "" Vector__XXX
 SG_ VCFRONT1_EPAS2EFuseVoltage m0 : 24|8@1+ (0.07,0) [0|17.85] "V" Vector__XXX
 SG_ VCFRONT1_EPAS2EFuseTemperature m0 : 32|8@1+ (1,-40) [-40|150] "degC" Vector__XXX
 SG_ VCFRONT1_EPAS2EFuseManagerState m0 : 40|4@1+ (1,0) [0|15] "" Vector__XXX
 SG_ VCFRONT1_EPAS2EFuseHardShortThre m0 : 44|4@1+ (1,0) [0|15] "" Vector__XXX
 SG_ VCFRONT1_EPAS2EFuseOCThreshold m0 : 48|5@1+ (1,0) [0|31] "" Vector__XXX
 SG_ VCFRONT1_EPAS2EFuseType m0 : 53|2@1+ (1,0) [0|3] "" Vector__XXX
 SG_ VCFRONT1_rightControllerEFuseSta m1 : 3|3@1+ (1,0) [0|7] "" Vector__XXX
 SG_ VCFRONT1_rightControllerEFuseCur m1 : 8|12@1+ (0.05,0) [0|204.75] "A" Vector__XXX
 SG_ VCFRONT1_rightControllerEFuseOut m1 : 20|1@1+ (1,0) [0|1] "" Vector__XXX
 SG_ VCFRONT1_rightControllerEFu_0002 m1 : 21|1@1+ (1,0) [0|1] "" Vector__XXX
 SG_ VCFRONT1_rightControllerEFuseByp m1 : 22|1@1+ (1,0) [0|1] "" Vector__XXX
 SG_ VCFRONT1_rightControllerEFu_0001 m1 : 23|1@1+ (1,0) [0|1] "" Vector__XXX
 SG_ VCFRONT1_rightControllerEFuseVol m1 : 24|8@1+ (0.07,0) [0|17.85] "V" Vector__XXX
 SG_ VCFRONT1_rightControllerEFuseTem m1 : 32|8@1+ (1,-40) [-40|150] "degC" Vector__XXX
 SG_ VCFRONT1_rightControllerEFuseMan m1 : 40|4@1+ (1,0) [0|15] "" Vector__XXX
 SG_ VCFRONT1_rightControllerEFuseHar m1 : 44|4@1+ (1,0) [0|15] "" Vector__XXX
 SG_ VCFRONT1_rightControllerEFuseOCT m1 : 48|5@1+ (1,0) [0|31] "" Vector__XXX
 SG_ VCFRONT1_rightControllerEFuseTyp m1 : 53|2@1+ (1,0) [0|3] "" Vector__XXX
 SG_ VCFRONT1_autopilot2EFuseState m3 : 3|3@1+ (1,0) [0|7] "" Vector__XXX
 SG_ VCFRONT1_autopilot2EFuseCurrent m3 : 8|12@1+ (0.05,0) [0|204.75] "A" Vector__XXX
 SG_ VCFRONT1_autopilot2EFuseOutput m3 : 20|1@1+ (1,0) [0|1] "" Vector__XXX
 SG_ VCFRONT1_autopilot2EFuseOutputDe m3 : 21|1@1+ (1,0) [0|1] "" Vector__XXX
 SG_ VCFRONT1_autopilot2EFuseBypass m3 : 22|1@1+ (1,0) [0|1] "" Vector__XXX
 SG_ VCFRONT1_autopilot2EFuseBypassDe m3 : 23|1@1+ (1,0) [0|1] "" Vector__XXX
 SG_ VCFRONT1_autopilot2EFuseVoltage m3 : 24|8@1+ (0.07,0) [0|17.85] "V" Vector__XXX
 SG_ VCFRONT1_autopilot2EFuseTemperat m3 : 32|8@1+ (1,-40) [-40|150] "degC" Vector__XXX
 SG_ VCFRONT1_autopilot2EFuseManagerS m3 : 40|4@1+ (1,0) [0|15] "" Vector__XXX
 SG_ VCFRONT1_autopilot2EFuseHardShor m3 : 44|4@1+ (1,0) [0|15] "" Vector__XXX
 SG_ VCFRONT1_autopilot2EFuseOCThresh m3 : 48|5@1+ (1,0) [0|31] "" Vector__XXX
 SG_ VCFRONT1_autopilot2EFuseType m3 : 53|2@1+ (1,0) [0|3] "" Vector__XXX

BO_ 609 VCFRONT_12VBatteryStatus: 8 VCFRONT
 SG_ VCFRONT_12VBatteryStatusIndex M : 0|3@1+ (1,0) [0|7] "" Vector__XXX
 SG_ VCFRONT_good12VforUpdate : 46|1@1+ (1,0) [0|1] "" Vector__XXX
 SG_ VCFRONT_LVLoadRequest : 47|1@1+ (1,0) [0|1] "" Vector__XXX
 SG_ VCFRONT_12VBatteryStatusCounter : 52|4@1+ (1,0) [0|15] "" Vector__XXX
 SG_ VCFRONT_12VBatteryStatusChecksum : 56|8@1+ (1,0) [0|255] "" Vector__XXX
 SG_ VCFRONT_batterySupportRequest m1 : 3|1@1+ (1,0) [0|1] "" Vector__XXX
 SG_ VCFRONT_batterySMState m1 : 4|4@1+ (1,0) [0|15] "" Vector__XXX
 SG_ VCFRONT_eFuseRecoveryStateDBG m1 : 8|3@1+ (1,0) [0|7] "" Vector__XXX
 SG_ VCFRONT_batteryLINScheduleDBG m1 : 11|3@1+ (1,0) [0|6] "" Vector__XXX
 SG_ VCFRONT_resistanceEstimationTest m1 : 14|2@1+ (1,0) [0|3] "" Vector__XXX
 SG_ VCFRONT_IBSCurrent m1 : 16|16@1- (0.005,0) [-163.84|163.835] "A" Vector__XXX
 SG_ VCFRONT_IBSVoltage m1 : 32|14@1+ (0.005443676,0) [0|65.535] "V" Vector__XXX
 SG_ VCFRONT_reverseBatteryFault m1 : 48|1@1+ (1,0) [0|1] "" Vector__XXX
 SG_ VCFRONT_LVBatterySupported m1 : 49|1@1+ (1,0) [0|1] "" Vector__XXX
 SG_ VCFRONT_LVBatteryCannotSupportVe m1 : 50|1@1+ (1,0) [0|1] "" Vector__XXX
 SG_ VCFRONT_goodTemp12VforUpdate m1 : 51|1@1+ (1,0) [0|1] "" Vector__XXX
 SG_ VCFRONT_12VBatteryTargetVoltage m2 : 3|13@1+ (0.01,0) [0|65.535] "V" Vector__XXX
 SG_ VCFRONT_IBSTemperature m2 : 16|11@1+ (0.1,-24) [-24|124] "degC" Vector__XXX
 SG_ VCFRONT_currentSensorMismatchLea m2 : 27|7@1+ (2,0) [0|254] "PCT" Vector__XXX
 SG_ VCFRONT_LVBatteryEnergyRemaining m2 : 37|7@1+ (1,0) [0|127] "%" Vector__XXX
 SG_ VCFRONT_LVBatteryStatusForDrive m2 : 44|2@1+ (1,0) [0|3] "" Vector__XXX
 SG_ VCFRONT_LVBatteryType m2 : 48|3@1+ (1,0) [0|7] "" Vector__XXX
 SG_ VCFRONT_resistanceEstimationNeed m2 : 51|1@1+ (1,0) [0|1] "" Vector__XXX
 SG_ VCFRONT_IBSVoltageFiltered m3 : 3|14@1+ (0.005443676,0) [0|65.535] "V" Vector__XXX
 SG_ VCFRONT_LVBMS_LVBusVoltageSource m3 : 17|2@1+ (1,0) [0|3] "" Vector__XXX
 SG_ VCFRONT_LVBMS_LVPackCurrentSourc m3 : 19|2@1+ (1,0) [0|3] "" Vector__XXX
 SG_ VCFRONT_LVBatterySupportRqrdTrig m3 : 24|14@1+ (1,0) [0|16383] "" Vector__XXX
 SG_ VCFRONT_goodForPCSPowerCycleLeak m3 : 40|5@1+ (0.0005,0) [0|0.0155] "Ah" Vector__XXX
 SG_ VCFRONT_LVBusControlsFutile m3 : 45|1@1+ (1,0) [0|1] "" Vector__XXX
 SG_ VCFRONT_resistanceEstimatio_0001 m3 : 48|1@1+ (1,0) [0|1] "" Vector__XXX
 SG_ VCFRONT_resistanceEstimatio_0002 m3 : 49|1@1+ (1,0) [0|1] "" Vector__XXX
 SG_ VCFRONT_goodLVChargeForUpdate m3 : 50|1@1+ (1,0) [0|1] "" Vector__XXX
 SG_ VCFRONT_opportunisticDCRTestNeed m3 : 51|1@1+ (1,0) [0|1] "" Vector__XXX
 SG_ VCFRONT_voltageProfile m4 : 3|2@1+ (1,0) [0|3] "" Vector__XXX
 SG_ VCFRONT_IBSAmpHours m4 : 5|14@1- (0.005,0) [-40.96|40.955] "Ah" Vector__XXX
 SG_ VCFRONT_IBSVoltageRawDBG m4 : 19|14@1+ (0.005443676,0) [0|65.535] "V" Vector__XXX
 SG_ VCFRONT_LVBatteryLINCommsDetecte m4 : 33|1@1+ (1,0) [0|1] "" Vector__XXX
 SG_ VCFRONT_voltageSensorMismatchLea m4 : 34|7@1+ (2,0) [0|254] "PCT" Vector__XXX
 SG_ VCFRONT_LVBusControlMode m4 : 41|4@1+ (1,0) [0|15] "" Vector__XXX
 SG_ VCFRONT_resistanceEstimationExte m4 : 45|1@1+ (1,0) [0|1] "" Vector__XXX
 SG_ VCFRONT_LVBatteryFctryLimOverrid m4 : 50|1@1+ (1,0) [0|1] "" Vector__XXX
 SG_ VCFRONT_LVBatterySPICommsDetecte m4 : 51|1@1+ (1,0) [0|1] "" Vector__XXX
 SG_ VCFRONT_targetCurrent m5 : 3|11@1+ (0.125,-127) [0|120] "A" Vector__XXX
 SG_ VCFRONT_PCSMia m5 : 14|1@1+ (1,0) [0|1] "" Vector__XXX
 SG_ VCFRONT_chargeNeeded m5 : 15|1@1+ (1,0) [0|1] "" Vector__XXX
 SG_ VCFRONT_voltageControlLoopIntegr m5 : 16|14@1+ (0.006,0) [0|65.535] "V" Vector__XXX
 SG_ VCFRONT_currentControlLoopIntegr m5 : 30|14@1+ (0.006,0) [0|65.535] "V" Vector__XXX

BO_TX_BU_ 1025 : BMS;
BO_TX_BU_ 1138 : BMS;
BO_TX_BU_ 1071 : BMS;
BO_TX_BU_ 669 : CP;
BO_TX_BU_ 541 : CP;
BO_TX_BU_ 1001 : DAS;
BO_TX_BU_ 634 : DIF;
BO_TX_BU_ 784 : HVP;
BO_TX_BU_ 941 : ICR;
BO_TX_BU_ 964 : PCS;
BO_TX_BU_ 816 : SCCM;
BO_TX_BU_ 1657 : GTW;
BO_TX_BU_ 819 : GTW;
BO_TX_BU_ 991 : GTW;
BO_TX_BU_ 663 : GTW;
BO_TX_BU_ 947 : GTW;
BO_TX_BU_ 1090 : VCBATT;
BO_TX_BU_ 1027 : VCFRONT1;
BO_TX_BU_ 609 : VCFRONT;

CM_ "Tesla Model Y CAN bus database; bus VEH (vehicle CAN); firmware 2026.26.6.5. Decoded CAN signal definitions (layout, scaling, units, value tables).";
CM_ BU_ BMS "High-voltage battery management system";
CM_ BU_ CP "Charge port controller";
CM_ BU_ DAS "Driver assistance computer";
CM_ BU_ DIF "Front drive inverter";
CM_ BU_ GTW "Gateway";
CM_ BU_ HVP "High-voltage processor (pack contactor and isolation controller)";
CM_ BU_ ICR "ICR ECU";
CM_ BU_ PCS "Power conversion system (on-board charger and DC-DC converter)";
CM_ BU_ SCCM "Steering column control module";
CM_ BU_ VCBATT "VCBATT ECU";
CM_ BU_ VCFRONT "Front body controller";
CM_ BU_ VCFRONT1 "VCFRONT1 ECU";
CM_ BU_ VCLEFT "Left body controller";
CM_ BU_ VCRIGHT "Right body controller";
CM_ BU_ VCSEC "Vehicle security controller";
CM_ BO_ 1025 "High-voltage battery management system message: brick measurements";
CM_ SG_ 1025 BMS_brickVoltageMultiplexer "High-voltage battery management system: brick voltage multiplexer";
CM_ SG_ 1025 BMS_brickVoltageCounter "High-voltage battery management system: brick voltage counter";
CM_ SG_ 1025 BMS_brickVoltageStatus1 "High-voltage battery management system: brick voltage status1";
CM_ SG_ 1025 BMS_brickVoltageStatus2 "High-voltage battery management system: brick voltage status2";
CM_ SG_ 1025 BMS_brickVoltageStatus3 "High-voltage battery management system: brick voltage status3";
CM_ SG_ 1025 BMS_brickVoltage1 "High-voltage battery management system: brick voltage1";
CM_ SG_ 1025 BMS_brickVoltage2 "High-voltage battery management system: brick voltage2";
CM_ SG_ 1025 BMS_brickVoltage3 "High-voltage battery management system: brick voltage3";
CM_ SG_ 1025 BMS_brickVoltageStatus4 "High-voltage battery management system: brick voltage status4";
CM_ SG_ 1025 BMS_brickVoltageStatus5 "High-voltage battery management system: brick voltage status5";
CM_ SG_ 1025 BMS_brickVoltageStatus6 "High-voltage battery management system: brick voltage status6";
CM_ SG_ 1025 BMS_brickVoltage4 "High-voltage battery management system: brick voltage4";
CM_ SG_ 1025 BMS_brickVoltage5 "High-voltage battery management system: brick voltage5";
CM_ SG_ 1025 BMS_brickVoltage6 "High-voltage battery management system: brick voltage6";
CM_ SG_ 1025 BMS_brickVoltageStatus7 "High-voltage battery management system: brick voltage status7";
CM_ SG_ 1025 BMS_brickVoltageStatus8 "High-voltage battery management system: brick voltage status8";
CM_ SG_ 1025 BMS_brickVoltageStatus9 "High-voltage battery management system: brick voltage status9";
CM_ SG_ 1025 BMS_brickVoltage7 "High-voltage battery management system: brick voltage7";
CM_ SG_ 1025 BMS_brickVoltage8 "High-voltage battery management system: brick voltage8";
CM_ SG_ 1025 BMS_brickVoltage9 "High-voltage battery management system: brick voltage9";
CM_ SG_ 1025 BMS_brickVoltageStatus10 "High-voltage battery management system: brick voltage status10";
CM_ SG_ 1025 BMS_brickVoltageStatus11 "High-voltage battery management system: brick voltage status11";
CM_ SG_ 1025 BMS_brickVoltageStatus12 "High-voltage battery management system: brick voltage status12";
CM_ SG_ 1025 BMS_brickVoltage10 "High-voltage battery management system: brick voltage10";
CM_ SG_ 1025 BMS_brickVoltage11 "High-voltage battery management system: brick voltage11";
CM_ SG_ 1025 BMS_brickVoltage12 "High-voltage battery management system: brick voltage12";
CM_ SG_ 1025 BMS_brickVoltageStatus13 "High-voltage battery management system: brick voltage status13";
CM_ SG_ 1025 BMS_brickVoltageStatus14 "High-voltage battery management system: brick voltage status14";
CM_ SG_ 1025 BMS_brickVoltageStatus15 "High-voltage battery management system: brick voltage status15";
CM_ SG_ 1025 BMS_brickVoltage13 "High-voltage battery management system: brick voltage13";
CM_ SG_ 1025 BMS_brickVoltage14 "High-voltage battery management system: brick voltage14";
CM_ SG_ 1025 BMS_brickVoltage15 "High-voltage battery management system: brick voltage15";
CM_ SG_ 1025 BMS_brickVoltageStatus16 "High-voltage battery management system: brick voltage status16";
CM_ SG_ 1025 BMS_brickVoltageStatus17 "High-voltage battery management system: brick voltage status17";
CM_ SG_ 1025 BMS_brickVoltageStatus18 "High-voltage battery management system: brick voltage status18";
CM_ SG_ 1025 BMS_brickVoltage16 "High-voltage battery management system: brick voltage16";
CM_ SG_ 1025 BMS_brickVoltage17 "High-voltage battery management system: brick voltage17";
CM_ SG_ 1025 BMS_brickVoltage18 "High-voltage battery management system: brick voltage18";
CM_ SG_ 1025 BMS_brickVoltageStatus19 "High-voltage battery management system: brick voltage status19";
CM_ SG_ 1025 BMS_brickVoltageStatus20 "High-voltage battery management system: brick voltage status20";
CM_ SG_ 1025 BMS_brickVoltageStatus21 "High-voltage battery management system: brick voltage status21";
CM_ SG_ 1025 BMS_brickVoltage19 "High-voltage battery management system: brick voltage19";
CM_ SG_ 1025 BMS_brickVoltage20 "High-voltage battery management system: brick voltage20";
CM_ SG_ 1025 BMS_brickVoltage21 "High-voltage battery management system: brick voltage21";
CM_ SG_ 1025 BMS_brickVoltageStatus22 "High-voltage battery management system: brick voltage status22";
CM_ SG_ 1025 BMS_brickVoltageStatus23 "High-voltage battery management system: brick voltage status23";
CM_ SG_ 1025 BMS_brickVoltageStatus24 "High-voltage battery management system: brick voltage status24";
CM_ SG_ 1025 BMS_brickVoltage22 "High-voltage battery management system: brick voltage22";
CM_ SG_ 1025 BMS_brickVoltage23 "High-voltage battery management system: brick voltage23";
CM_ SG_ 1025 BMS_brickVoltage24 "High-voltage battery management system: brick voltage24";
CM_ SG_ 1025 BMS_brickVoltageStatus25 "High-voltage battery management system: brick voltage status25";
CM_ SG_ 1025 BMS_brickVoltageStatus26 "High-voltage battery management system: brick voltage status26";
CM_ SG_ 1025 BMS_brickVoltageStatus27 "High-voltage battery management system: brick voltage status27";
CM_ SG_ 1025 BMS_brickVoltage25 "High-voltage battery management system: brick voltage25";
CM_ SG_ 1025 BMS_brickVoltage26 "High-voltage battery management system: brick voltage26";
CM_ SG_ 1025 BMS_brickVoltage27 "High-voltage battery management system: brick voltage27";
CM_ SG_ 1025 BMS_brickVoltageStatus28 "High-voltage battery management system: brick voltage status28";
CM_ SG_ 1025 BMS_brickVoltageStatus29 "High-voltage battery management system: brick voltage status29";
CM_ SG_ 1025 BMS_brickVoltageStatus30 "High-voltage battery management system: brick voltage status30";
CM_ SG_ 1025 BMS_brickVoltage28 "High-voltage battery management system: brick voltage28";
CM_ SG_ 1025 BMS_brickVoltage29 "High-voltage battery management system: brick voltage29";
CM_ SG_ 1025 BMS_brickVoltage30 "High-voltage battery management system: brick voltage30";
CM_ SG_ 1025 BMS_brickVoltageStatus31 "High-voltage battery management system: brick voltage status31";
CM_ SG_ 1025 BMS_brickVoltageStatus32 "High-voltage battery management system: brick voltage status32";
CM_ SG_ 1025 BMS_brickVoltageStatus33 "High-voltage battery management system: brick voltage status33";
CM_ SG_ 1025 BMS_brickVoltage31 "High-voltage battery management system: brick voltage31";
CM_ SG_ 1025 BMS_brickVoltage32 "High-voltage battery management system: brick voltage32";
CM_ SG_ 1025 BMS_brickVoltage33 "High-voltage battery management system: brick voltage33";
CM_ SG_ 1025 BMS_brickVoltageStatus34 "High-voltage battery management system: brick voltage status34";
CM_ SG_ 1025 BMS_brickVoltageStatus35 "High-voltage battery management system: brick voltage status35";
CM_ SG_ 1025 BMS_brickVoltageStatus36 "High-voltage battery management system: brick voltage status36";
CM_ SG_ 1025 BMS_brickVoltage34 "High-voltage battery management system: brick voltage34";
CM_ SG_ 1025 BMS_brickVoltage35 "High-voltage battery management system: brick voltage35";
CM_ SG_ 1025 BMS_brickVoltage36 "High-voltage battery management system: brick voltage36";
CM_ SG_ 1025 BMS_brickVoltageStatus37 "High-voltage battery management system: brick voltage status37";
CM_ SG_ 1025 BMS_brickVoltageStatus38 "High-voltage battery management system: brick voltage status38";
CM_ SG_ 1025 BMS_brickVoltageStatus39 "High-voltage battery management system: brick voltage status39";
CM_ SG_ 1025 BMS_brickVoltage37 "High-voltage battery management system: brick voltage37";
CM_ SG_ 1025 BMS_brickVoltage38 "High-voltage battery management system: brick voltage38";
CM_ SG_ 1025 BMS_brickVoltage39 "High-voltage battery management system: brick voltage39";
CM_ SG_ 1025 BMS_brickVoltageStatus40 "High-voltage battery management system: brick voltage status40";
CM_ SG_ 1025 BMS_brickVoltageStatus41 "High-voltage battery management system: brick voltage status41";
CM_ SG_ 1025 BMS_brickVoltageStatus42 "High-voltage battery management system: brick voltage status42";
CM_ SG_ 1025 BMS_brickVoltage40 "High-voltage battery management system: brick voltage40";
CM_ SG_ 1025 BMS_brickVoltage41 "High-voltage battery management system: brick voltage41";
CM_ SG_ 1025 BMS_brickVoltage42 "High-voltage battery management system: brick voltage42";
CM_ SG_ 1025 BMS_brickVoltageStatus43 "High-voltage battery management system: brick voltage status43";
CM_ SG_ 1025 BMS_brickVoltageStatus44 "High-voltage battery management system: brick voltage status44";
CM_ SG_ 1025 BMS_brickVoltageStatus45 "High-voltage battery management system: brick voltage status45";
CM_ SG_ 1025 BMS_brickVoltage43 "High-voltage battery management system: brick voltage43";
CM_ SG_ 1025 BMS_brickVoltage44 "High-voltage battery management system: brick voltage44";
CM_ SG_ 1025 BMS_brickVoltage45 "High-voltage battery management system: brick voltage45";
CM_ SG_ 1025 BMS_brickVoltageStatus46 "High-voltage battery management system: brick voltage status46";
CM_ SG_ 1025 BMS_brickVoltageStatus47 "High-voltage battery management system: brick voltage status47";
CM_ SG_ 1025 BMS_brickVoltageStatus48 "High-voltage battery management system: brick voltage status48";
CM_ SG_ 1025 BMS_brickVoltage46 "High-voltage battery management system: brick voltage46";
CM_ SG_ 1025 BMS_brickVoltage47 "High-voltage battery management system: brick voltage47";
CM_ SG_ 1025 BMS_brickVoltage48 "High-voltage battery management system: brick voltage48";
CM_ SG_ 1025 BMS_brickVoltageStatus49 "High-voltage battery management system: brick voltage status49";
CM_ SG_ 1025 BMS_brickVoltageStatus50 "High-voltage battery management system: brick voltage status50";
CM_ SG_ 1025 BMS_brickVoltageStatus51 "High-voltage battery management system: brick voltage status51";
CM_ SG_ 1025 BMS_brickVoltage49 "High-voltage battery management system: brick voltage49";
CM_ SG_ 1025 BMS_brickVoltage50 "High-voltage battery management system: brick voltage50";
CM_ SG_ 1025 BMS_brickVoltage51 "High-voltage battery management system: brick voltage51";
CM_ SG_ 1025 BMS_brickVoltageStatus52 "High-voltage battery management system: brick voltage status52";
CM_ SG_ 1025 BMS_brickVoltageStatus53 "High-voltage battery management system: brick voltage status53";
CM_ SG_ 1025 BMS_brickVoltageStatus54 "High-voltage battery management system: brick voltage status54";
CM_ SG_ 1025 BMS_brickVoltage52 "High-voltage battery management system: brick voltage52";
CM_ SG_ 1025 BMS_brickVoltage53 "High-voltage battery management system: brick voltage53";
CM_ SG_ 1025 BMS_brickVoltage54 "High-voltage battery management system: brick voltage54";
CM_ SG_ 1025 BMS_brickVoltageStatus55 "High-voltage battery management system: brick voltage status55";
CM_ SG_ 1025 BMS_brickVoltageStatus56 "High-voltage battery management system: brick voltage status56";
CM_ SG_ 1025 BMS_brickVoltageStatus57 "High-voltage battery management system: brick voltage status57";
CM_ SG_ 1025 BMS_brickVoltage55 "High-voltage battery management system: brick voltage55";
CM_ SG_ 1025 BMS_brickVoltage56 "High-voltage battery management system: brick voltage56";
CM_ SG_ 1025 BMS_brickVoltage57 "High-voltage battery management system: brick voltage57";
CM_ SG_ 1025 BMS_brickVoltageStatus58 "High-voltage battery management system: brick voltage status58";
CM_ SG_ 1025 BMS_brickVoltageStatus59 "High-voltage battery management system: brick voltage status59";
CM_ SG_ 1025 BMS_brickVoltageStatus60 "High-voltage battery management system: brick voltage status60";
CM_ SG_ 1025 BMS_brickVoltage58 "High-voltage battery management system: brick voltage58";
CM_ SG_ 1025 BMS_brickVoltage59 "High-voltage battery management system: brick voltage59";
CM_ SG_ 1025 BMS_brickVoltage60 "High-voltage battery management system: brick voltage60";
CM_ SG_ 1025 BMS_brickVoltageStatus61 "High-voltage battery management system: brick voltage status61";
CM_ SG_ 1025 BMS_brickVoltageStatus62 "High-voltage battery management system: brick voltage status62";
CM_ SG_ 1025 BMS_brickVoltageStatus63 "High-voltage battery management system: brick voltage status63";
CM_ SG_ 1025 BMS_brickVoltage61 "High-voltage battery management system: brick voltage61";
CM_ SG_ 1025 BMS_brickVoltage62 "High-voltage battery management system: brick voltage62";
CM_ SG_ 1025 BMS_brickVoltage63 "High-voltage battery management system: brick voltage63";
CM_ SG_ 1025 BMS_brickVoltageStatus64 "High-voltage battery management system: brick voltage status64";
CM_ SG_ 1025 BMS_brickVoltageStatus65 "High-voltage battery management system: brick voltage status65";
CM_ SG_ 1025 BMS_brickVoltageStatus66 "High-voltage battery management system: brick voltage status66";
CM_ SG_ 1025 BMS_brickVoltage64 "High-voltage battery management system: brick voltage64";
CM_ SG_ 1025 BMS_brickVoltage65 "High-voltage battery management system: brick voltage65";
CM_ SG_ 1025 BMS_brickVoltage66 "High-voltage battery management system: brick voltage66";
CM_ SG_ 1025 BMS_brickVoltageStatus67 "High-voltage battery management system: brick voltage status67";
CM_ SG_ 1025 BMS_brickVoltageStatus68 "High-voltage battery management system: brick voltage status68";
CM_ SG_ 1025 BMS_brickVoltageStatus69 "High-voltage battery management system: brick voltage status69";
CM_ SG_ 1025 BMS_brickVoltage67 "High-voltage battery management system: brick voltage67";
CM_ SG_ 1025 BMS_brickVoltage68 "High-voltage battery management system: brick voltage68";
CM_ SG_ 1025 BMS_brickVoltage69 "High-voltage battery management system: brick voltage69";
CM_ SG_ 1025 BMS_brickVoltageStatus70 "High-voltage battery management system: brick voltage status70";
CM_ SG_ 1025 BMS_brickVoltageStatus71 "High-voltage battery management system: brick voltage status71";
CM_ SG_ 1025 BMS_brickVoltageStatus72 "High-voltage battery management system: brick voltage status72";
CM_ SG_ 1025 BMS_brickVoltage70 "High-voltage battery management system: brick voltage70";
CM_ SG_ 1025 BMS_brickVoltage71 "High-voltage battery management system: brick voltage71";
CM_ SG_ 1025 BMS_brickVoltage72 "High-voltage battery management system: brick voltage72";
CM_ SG_ 1025 BMS_brickVoltageStatus73 "High-voltage battery management system: brick voltage status73";
CM_ SG_ 1025 BMS_brickVoltageStatus74 "High-voltage battery management system: brick voltage status74";
CM_ SG_ 1025 BMS_brickVoltageStatus75 "High-voltage battery management system: brick voltage status75";
CM_ SG_ 1025 BMS_brickVoltage73 "High-voltage battery management system: brick voltage73";
CM_ SG_ 1025 BMS_brickVoltage74 "High-voltage battery management system: brick voltage74";
CM_ SG_ 1025 BMS_brickVoltage75 "High-voltage battery management system: brick voltage75";
CM_ SG_ 1025 BMS_brickVoltageStatus76 "High-voltage battery management system: brick voltage status76";
CM_ SG_ 1025 BMS_brickVoltageStatus77 "High-voltage battery management system: brick voltage status77";
CM_ SG_ 1025 BMS_brickVoltageStatus78 "High-voltage battery management system: brick voltage status78";
CM_ SG_ 1025 BMS_brickVoltage76 "High-voltage battery management system: brick voltage76";
CM_ SG_ 1025 BMS_brickVoltage77 "High-voltage battery management system: brick voltage77";
CM_ SG_ 1025 BMS_brickVoltage78 "High-voltage battery management system: brick voltage78";
CM_ SG_ 1025 BMS_brickVoltageStatus79 "High-voltage battery management system: brick voltage status79";
CM_ SG_ 1025 BMS_brickVoltageStatus80 "High-voltage battery management system: brick voltage status80";
CM_ SG_ 1025 BMS_brickVoltageStatus81 "High-voltage battery management system: brick voltage status81";
CM_ SG_ 1025 BMS_brickVoltage79 "High-voltage battery management system: brick voltage79";
CM_ SG_ 1025 BMS_brickVoltage80 "High-voltage battery management system: brick voltage80";
CM_ SG_ 1025 BMS_brickVoltage81 "High-voltage battery management system: brick voltage81";
CM_ SG_ 1025 BMS_brickVoltageStatus82 "High-voltage battery management system: brick voltage status82";
CM_ SG_ 1025 BMS_brickVoltageStatus83 "High-voltage battery management system: brick voltage status83";
CM_ SG_ 1025 BMS_brickVoltageStatus84 "High-voltage battery management system: brick voltage status84";
CM_ SG_ 1025 BMS_brickVoltage82 "High-voltage battery management system: brick voltage82";
CM_ SG_ 1025 BMS_brickVoltage83 "High-voltage battery management system: brick voltage83";
CM_ SG_ 1025 BMS_brickVoltage84 "High-voltage battery management system: brick voltage84";
CM_ SG_ 1025 BMS_brickVoltageStatus85 "High-voltage battery management system: brick voltage status85";
CM_ SG_ 1025 BMS_brickVoltageStatus86 "High-voltage battery management system: brick voltage status86";
CM_ SG_ 1025 BMS_brickVoltageStatus87 "High-voltage battery management system: brick voltage status87";
CM_ SG_ 1025 BMS_brickVoltage85 "High-voltage battery management system: brick voltage85";
CM_ SG_ 1025 BMS_brickVoltage86 "High-voltage battery management system: brick voltage86";
CM_ SG_ 1025 BMS_brickVoltage87 "High-voltage battery management system: brick voltage87";
CM_ SG_ 1025 BMS_brickVoltageStatus88 "High-voltage battery management system: brick voltage status88";
CM_ SG_ 1025 BMS_brickVoltageStatus89 "High-voltage battery management system: brick voltage status89";
CM_ SG_ 1025 BMS_brickVoltageStatus90 "High-voltage battery management system: brick voltage status90";
CM_ SG_ 1025 BMS_brickVoltage88 "High-voltage battery management system: brick voltage88";
CM_ SG_ 1025 BMS_brickVoltage89 "High-voltage battery management system: brick voltage89";
CM_ SG_ 1025 BMS_brickVoltage90 "High-voltage battery management system: brick voltage90";
CM_ SG_ 1025 BMS_brickVoltageStatus91 "High-voltage battery management system: brick voltage status91";
CM_ SG_ 1025 BMS_brickVoltageStatus92 "High-voltage battery management system: brick voltage status92";
CM_ SG_ 1025 BMS_brickVoltageStatus93 "High-voltage battery management system: brick voltage status93";
CM_ SG_ 1025 BMS_brickVoltage91 "High-voltage battery management system: brick voltage91";
CM_ SG_ 1025 BMS_brickVoltage92 "High-voltage battery management system: brick voltage92";
CM_ SG_ 1025 BMS_brickVoltage93 "High-voltage battery management system: brick voltage93";
CM_ SG_ 1025 BMS_brickVoltageStatus94 "High-voltage battery management system: brick voltage status94";
CM_ SG_ 1025 BMS_brickVoltageStatus95 "High-voltage battery management system: brick voltage status95";
CM_ SG_ 1025 BMS_brickVoltageStatus96 "High-voltage battery management system: brick voltage status96";
CM_ SG_ 1025 BMS_brickVoltage94 "High-voltage battery management system: brick voltage94";
CM_ SG_ 1025 BMS_brickVoltage95 "High-voltage battery management system: brick voltage95";
CM_ SG_ 1025 BMS_brickVoltage96 "High-voltage battery management system: brick voltage96";
CM_ SG_ 1025 BMS_brickVoltageStatus97 "High-voltage battery management system: brick voltage status97";
CM_ SG_ 1025 BMS_brickVoltageStatus98 "High-voltage battery management system: brick voltage status98";
CM_ SG_ 1025 BMS_brickVoltageStatus99 "High-voltage battery management system: brick voltage status99";
CM_ SG_ 1025 BMS_brickVoltage97 "High-voltage battery management system: brick voltage97";
CM_ SG_ 1025 BMS_brickVoltage98 "High-voltage battery management system: brick voltage98";
CM_ SG_ 1025 BMS_brickVoltage99 "High-voltage battery management system: brick voltage99";
CM_ SG_ 1025 BMS_brickVoltageStatus100 "High-voltage battery management system: brick voltage status100";
CM_ SG_ 1025 BMS_brickVoltageStatus101 "High-voltage battery management system: brick voltage status101";
CM_ SG_ 1025 BMS_brickVoltageStatus102 "High-voltage battery management system: brick voltage status102";
CM_ SG_ 1025 BMS_brickVoltage100 "High-voltage battery management system: brick voltage100";
CM_ SG_ 1025 BMS_brickVoltage101 "High-voltage battery management system: brick voltage101";
CM_ SG_ 1025 BMS_brickVoltage102 "High-voltage battery management system: brick voltage102";
CM_ SG_ 1025 BMS_brickVoltageStatus103 "High-voltage battery management system: brick voltage status103";
CM_ SG_ 1025 BMS_brickVoltageStatus104 "High-voltage battery management system: brick voltage status104";
CM_ SG_ 1025 BMS_brickVoltageStatus105 "High-voltage battery management system: brick voltage status105";
CM_ SG_ 1025 BMS_brickVoltage103 "High-voltage battery management system: brick voltage103";
CM_ SG_ 1025 BMS_brickVoltage104 "High-voltage battery management system: brick voltage104";
CM_ SG_ 1025 BMS_brickVoltage105 "High-voltage battery management system: brick voltage105";
CM_ SG_ 1025 BMS_brickVoltageStatus106 "High-voltage battery management system: brick voltage status106";
CM_ SG_ 1025 BMS_brickVoltageStatus107 "High-voltage battery management system: brick voltage status107";
CM_ SG_ 1025 BMS_brickVoltageStatus108 "High-voltage battery management system: brick voltage status108";
CM_ SG_ 1025 BMS_brickVoltage106 "High-voltage battery management system: brick voltage106";
CM_ SG_ 1025 BMS_brickVoltage107 "High-voltage battery management system: brick voltage107";
CM_ SG_ 1025 BMS_brickVoltage108 "High-voltage battery management system: brick voltage108";
CM_ BO_ 1138 "High-voltage battery management system message: charge info";
CM_ SG_ 1138 BMS_acChargePowerSample "High-voltage battery management system: ac charge power sample; raw 255 = signal not available (SNA)";
CM_ SG_ 1138 BMS_voltageRegCurrentTarget "DC current target based on voltage regulator";
CM_ SG_ 1138 BMS_vehicleChargeDcCurrentLimit "Charge current target after all aggregating all vehicle-side limits, exclude EVSE limits";
CM_ SG_ 1138 BMS_userChargeCurrentLimitMode "BMS' user-facing reason for charge being either limited or not limited";
CM_ SG_ 1138 BMS_chargeCurrentLimitMode "BMS charging current limiting factor";
CM_ SG_ 1138 BMS_timeToFinishHeatForCharge "High-voltage battery management system: time to finish heat for charge; raw 127 = signal not available (SNA)";
CM_ SG_ 1138 BMS_timeToTripPlanChargingTarget "High-voltage battery management system: time to trip plan charging target; raw 2047 = signal not available (SNA)";
CM_ SG_ 1138 BMS_useChargeTimeEstimate "High-voltage battery management system: use charge time estimate";
CM_ BO_ 1071 "High-voltage battery management system message: v2x info";
CM_ SG_ 1071 BMS_v2xSoe "High-voltage battery management system: v2x soe; raw 65535 = signal not available (SNA)";
CM_ SG_ 1071 BMS_v2xFullEnergy "High-voltage battery management system: v2x full energy; raw 4095 = signal not available (SNA)";
CM_ SG_ 1071 BMS_v2xPackPower "High-voltage battery management system: v2x pack power; raw 511 = signal not available (SNA)";
CM_ SG_ 1071 BMS_acDischargeBlockedReason "The enumerated reason why the ECU is blocking AC discharge";
CM_ SG_ 1071 BMS_backupTimeRemaining "High-voltage battery management system: backup time remaining; raw 255 = signal not available (SNA)";
CM_ BO_ 669 "Charge port controller message: dc charge status";
CM_ SG_ 669 CP_evseOutputDcCurrent "The DC EVSE's measured output current";
CM_ SG_ 669 CP_evseOutputDcVoltage "The DC EVSE's measured output voltage";
CM_ SG_ 669 CP_evseOutputDcCurrentStale "Indicates whether the data in CP_evseOutputDcCurrent has not been updated with new info from the DC EVSE recently";
CM_ SG_ 669 CP_evRelocationRecommended "Indicates whether the supercharger EVSE recommends relocating the vehicle";
CM_ SG_ 669 CP_evseDeratingReason "Reports the derating reason from Supercharger EVSE";
CM_ BO_ 541 "Charge port controller message: evse status";
CM_ SG_ 541 CP_evseAccept "State of pilot EVSE accept state";
CM_ SG_ 541 CP_evseRequest "Request to close AC EVSE relays, used when digital communications have been established";
CM_ SG_ 541 CP_proximity "Sensed state of proximity for all inlets; raw 0 = signal not available (SNA)";
CM_ SG_ 541 CP_pilot "State of EVSE pilot signal sensed by the charge port; raw 7 = signal not available (SNA)";
CM_ SG_ 541 CP_digitalCommsEstablished "Indicates whether digital communications have been established with an EVSE";
CM_ SG_ 541 CP_pilotCurrent "Line current limit detected from pilot signal";
CM_ SG_ 541 CP_cableType "Type of charge cable detected; raw 5 = signal not available (SNA)";
CM_ SG_ 541 CP_iecPilotState "State of the control pilot as defined in IEC-61851-1; raw 9 = signal not available (SNA)";
CM_ SG_ 541 CP_plcSupported "Indicates whether PLC hardware is populated for CCS charging support";
CM_ SG_ 541 CP_cableCurrentLimit "Charge port controller: cable current limit";
CM_ SG_ 541 CP_teslaSwcanState "Charge port controller: tesla swcan state";
CM_ SG_ 541 CP_evseChargeType_UI "Reports the type of Electric Vehicle Supply Equipment (EVSE) connected.";
CM_ SG_ 541 CP_gbState "State of GB DC charging";
CM_ SG_ 541 CP_gbdcStopChargeReason "Reason for stopping GB DC charging";
CM_ SG_ 541 CP_gbdcFailureReason "Reason for failure of GB DC charging";
CM_ SG_ 541 CP_gbdcChargeAttempts "Number of GB DC charging retries used";
CM_ SG_ 541 CP_acChargeState "Charge port controller: ac charge state";
CM_ SG_ 541 CP_acChargeType "Charge port controller: ac charge type";
CM_ SG_ 541 CP_teslaDcState "Reports the state of the Tesla direct current (DC) state machine.";
CM_ BO_ 1001 "Driver assistance computer message: body controls";
CM_ SG_ 1001 DAS_headlightRequest "The DAS request to the body controls ecu to turn on headlights.";
CM_ SG_ 1001 DAS_hazardLightRequest "The command from DAS to body controls to turn on the hazard lights; raw 3 = signal not available (SNA)";
CM_ SG_ 1001 DAS_wiperSpeed "The auto wiper algorithm speed request to the body controller.";
CM_ SG_ 1001 DAS_turnIndicatorRequest "Reports Driver Assistance System (DAS) request to body controls to turn on/off the left or right turn indicator.";
CM_ SG_ 1001 DAS_highLowBeamDecision "The output of the automatic high beam algorithm, to turn the highbeams on or off; raw 3 = signal not available (SNA)";
CM_ SG_ 1001 DAS_heaterRequest "The DAS request to the body controller to turn on the front glass heater in front of the triple camera; raw 0 = signal not available (SNA)";
CM_ SG_ 1001 DAS_highLowBeamOffReason "The reason why automatic high beams are surpressed; raw 5 = signal not available (SNA)";
CM_ SG_ 1001 DAS_forwardCamHeaterDutyCycle "Supplies the requested duty cycle of the front windshield camera heater";
CM_ SG_ 1001 DAS_dynamicBrakeLightRequest "Indicates if the dynamic brake light alogirthm is requesting pulsing brake lights.";
CM_ SG_ 1001 DAS_radarHeaterRequest "Reports the request from Driver Assistance System (DAS) to body controls to turn on heater to clear out fascia in front of the radar.";
CM_ SG_ 1001 DAS_ahlbOverride "Indicates if body controller should override UI switch and stalk state to allow auto high beam functionality";
CM_ SG_ 1001 DAS_mirrorFoldRequest "DAS request to fold or present mirrors; raw 3 = signal not available (SNA)";
CM_ SG_ 1001 DAS_wiperWashRequest "Autowiper requests that the windshield be washed";
CM_ SG_ 1001 DAS_ulcConfirmationRequestActive "Driver assistance computer: ulc confirmation request active";
CM_ SG_ 1001 DAS_overrideWiperSetting "Autopilot wants to override the user's wiper setting to enable auto-wiper";
CM_ SG_ 1001 DAS_autoWiperState "DAS auto wiper internal state; raw 5 = signal not available (SNA)";
CM_ SG_ 1001 DAS_turnIndicatorRequestReason "Reports the reason that Driver Assistance System (DAS) is requesting a change to the turn indicator state from body controls.";
CM_ SG_ 1001 DAS_forwardRadarPowerRequest "Driver assistance computer: forward radar power request";
CM_ SG_ 1001 DAS_driverDomeLightRequest "DAS requests that driver side dome light be illuminated";
CM_ SG_ 1001 DAS_drivePowerStateRequest "Reports DAS request for vehicle power state Drive.";
CM_ SG_ 1001 DAS_enableIcrDataCollection "Driver assistance computer: enable icr data collection";
CM_ SG_ 1001 DAS_rPillarCamHeaterDutyCycle "Supplies the requested duty cycle of the right pillar camera heater";
CM_ SG_ 1001 DAS_adaptiveHighBeamIsFaulted "Indicates malfunctioning or unavailable input to the Adaptive High Beam system.";
CM_ SG_ 1001 DAS_restrictDoorReleaseLeft "Reports requests to inhibit left doors from being released.";
CM_ SG_ 1001 DAS_restrictDoorReleaseRight "Reports requests to inhibit right doors from being released.";
CM_ SG_ 1001 DAS_bodyControlsCounter "Driver assistance computer: body controls counter";
CM_ SG_ 1001 DAS_bodyControlsChecksum "Driver assistance computer: body controls checksum";
CM_ BO_ 634 "Front drive inverter message: hv status";
CM_ SG_ 634 DIF_hvStatusChecksum "Front drive inverter: hv status checksum";
CM_ SG_ 634 DIF_hvStatusCounter "Front drive inverter: hv status counter";
CM_ SG_ 634 DIF_hvilCurrent "HVIL Current";
CM_ SG_ 634 DIF_hvilCmVoltage "HVIL Common Mode Voltage";
CM_ SG_ 634 DIF_hvilStatus "Aggregated hardware and measured HVIL unit status; raw 3 = signal not available (SNA)";
CM_ SG_ 634 DIF_hvilSupplyState "Front drive inverter: hvil supply state";
CM_ SG_ 634 DIF_activeDischargeCtrl "Front drive inverter: active discharge ctrl";
CM_ SG_ 634 DIF_activeDischargeStatus "Active discharge status from HVIL_FAULT signal.";
CM_ SG_ 634 DIF_vBat "Reports the battery voltage measured by the Drive Inverter's local Analog to Digital Converter (ADC).";
CM_ SG_ 634 DIF_vBatQF "Front drive inverter: v bat QF";
CM_ SG_ 634 DIF_powerStageSafeState "Front drive inverter: power stage safe state";
CM_ SG_ 634 DIF_fluxState "Front drive inverter: flux state";
CM_ SG_ 634 DIF_vBusDiag "Front drive inverter: v bus diag";
CM_ SG_ 634 DIF_gateDriveState "Front drive inverter: gate drive state";
CM_ SG_ 634 DIF_gateDriveSupplyState "Front drive inverter: gate drive supply state";
CM_ BO_ 784 "High-voltage processor (pack contactor and isolation controller) message: info";
CM_ SG_ 784 HVP_infoIndex "High-voltage processor (pack contactor and isolation controller): info index";
CM_ SG_ 784 HVP_buildType "High-voltage processor (pack contactor and isolation controller): build type";
CM_ SG_ 784 HVP_buildConfigId "High-voltage processor (pack contactor and isolation controller): build config id";
CM_ SG_ 784 HVP_hardwareId "High-voltage processor (pack contactor and isolation controller): hardware id";
CM_ SG_ 784 HVP_componentId "High-voltage processor (pack contactor and isolation controller): component id";
CM_ SG_ 784 HVP_pcbaId "High-voltage processor (pack contactor and isolation controller): pcba id";
CM_ SG_ 784 HVP_assemblyId "HVP's assigned assembly ID";
CM_ SG_ 784 HVP_usageId "HVP's assigned usage ID";
CM_ SG_ 784 HVP_subUsageId "HVP's assigned subusage ID";
CM_ SG_ 784 HVP_platformType "High-voltage processor (pack contactor and isolation controller): platform type";
CM_ SG_ 784 HVP_appCrc "High-voltage processor (pack contactor and isolation controller): app crc";
CM_ SG_ 784 HVP_appGitHash "High-voltage processor (pack contactor and isolation controller): app git hash";
CM_ SG_ 784 HVP_bootGitHash "High-voltage processor (pack contactor and isolation controller): boot git hash";
CM_ SG_ 784 HVP_bootUdsProtoVersion "High-voltage processor (pack contactor and isolation controller): boot uds proto version";
CM_ SG_ 784 HVP_bootCrc "High-voltage processor (pack contactor and isolation controller): boot crc";
CM_ BO_ 941 "ICR ECU message: info";
CM_ SG_ 941 ICR_infoIndex "ICR ECU: info index";
CM_ SG_ 941 ICR_infoBuildType "ICR ECU: info build type";
CM_ SG_ 941 ICR_infoPcbaId "ICR ECU: info pcba id";
CM_ SG_ 941 ICR_infoAssemblyId "ICR ECU: info assembly id";
CM_ SG_ 941 ICR_infoUsageId "ICR ECU: info usage id";
CM_ SG_ 941 ICR_infoAppCrc "ICR ECU: info app crc";
CM_ SG_ 941 ICR_infoBoardPartNumber17 "ICR ECU: info board part number17";
CM_ SG_ 941 ICR_infoBoardPartNumber814 "ICR ECU: info board part number814";
CM_ SG_ 941 ICR_infoBoardPartNumber1520 "ICR ECU: info board part number1520";
CM_ BO_ 964 "Power conversion system (on-board charger and DC-DC converter) message: info";
CM_ SG_ 964 PCS_infoIndex "Power conversion system (on-board charger and DC-DC converter): info index";
CM_ SG_ 964 PCS_buildType "Power conversion system (on-board charger and DC-DC converter): build type";
CM_ SG_ 964 PCS_buildConfigId "Power conversion system (on-board charger and DC-DC converter): build config id";
CM_ SG_ 964 PCS_hardwareId "Power conversion system (on-board charger and DC-DC converter): hardware id";
CM_ SG_ 964 PCS_componentId "Power conversion system (on-board charger and DC-DC converter): component id";
CM_ SG_ 964 PCS_pcbaId "PCBA ID portion of component hardware ID as reported by application";
CM_ SG_ 964 PCS_assemblyId "Power conversion system (on-board charger and DC-DC converter): assembly id";
CM_ SG_ 964 PCS_usageId "Usage ID portion of component hardware ID as reported by application";
CM_ SG_ 964 PCS_subUsageId "Sub-usage ID portion of component hardware ID as reported by application";
CM_ SG_ 964 PCS_platformType "Power conversion system (on-board charger and DC-DC converter): platform type";
CM_ SG_ 964 PCS_appCrc "Power conversion system (on-board charger and DC-DC converter): app crc";
CM_ SG_ 964 PCS_cpu2AppCrc "Power conversion system (on-board charger and DC-DC converter): cpu2 app crc";
CM_ SG_ 964 PCS_appGitHash "Power conversion system (on-board charger and DC-DC converter): app git hash";
CM_ SG_ 964 PCS_bootGitHash "Power conversion system (on-board charger and DC-DC converter): boot git hash";
CM_ SG_ 964 PCS_bootUdsProtoVersion "Power conversion system (on-board charger and DC-DC converter): boot uds proto version";
CM_ SG_ 964 PCS_bootCrc "Power conversion system (on-board charger and DC-DC converter): boot crc";
CM_ BO_ 816 "Steering column control module message: info";
CM_ SG_ 816 SCCM_infoIndex "Steering column control module: info index";
CM_ SG_ 816 SCCM_infoBuildType "Steering column control module: info build type";
CM_ SG_ 816 SCCM_infoBuildConfigId "Steering column control module: info build config id";
CM_ SG_ 816 SCCM_infoHardwareId "Steering column control module: info hardware id";
CM_ SG_ 816 SCCM_infoComponentId "Steering column control module: info component id";
CM_ SG_ 816 SCCM_infoPcbaId "Steering column control module: info pcba id";
CM_ SG_ 816 SCCM_infoAssemblyId "Steering column control module: info assembly id";
CM_ SG_ 816 SCCM_infoUsageId "Steering column control module: info usage id";
CM_ SG_ 816 SCCM_infoSubUsageId "Steering column control module: info sub usage id";
CM_ SG_ 816 SCCM_infoPlatformType "Steering column control module: info platform type";
CM_ SG_ 816 SCCM_infoAppCrc "Steering column control module: info app crc";
CM_ SG_ 816 SCCM_infoBootSvnRev "Steering column control module: info boot svn rev";
CM_ SG_ 816 SCCM_infoBootSvnUrlHash "Steering column control module: info boot svn url hash";
CM_ SG_ 816 SCCM_infoSubcomponent1Version "Steering column control module: info subcomponent1 version";
CM_ SG_ 816 SCCM_infoAppSvnHash "Steering column control module: info app svn hash";
CM_ SG_ 816 SCCM_infoBootSvnHash "Steering column control module: info boot svn hash";
CM_ SG_ 816 SCCM_infoUdsProtoVersion "Steering column control module: info uds proto version";
CM_ SG_ 816 SCCM_infoBootCrc "Steering column control module: info boot crc";
CM_ BO_ 1657 "Touchscreen user interface computer message: ambient lighting ctrls; forwarded onto this bus by the gateway";
CM_ SG_ 1657 UI_rgbEnableState "Request to enable RGB lights";
CM_ SG_ 1657 UI_rgbEffectType "Reports the RGB light effect type.";
CM_ SG_ 1657 UI_rgbBrightnessLevel "Reports the requested RGB brightness level; raw 127 = signal not available (SNA)";
CM_ SG_ 1657 UI_audioVisualizerState "Request to enable RGB lights.";
CM_ SG_ 1657 UI_rgbTargetDOORFL "Target RGB control for front left door";
CM_ SG_ 1657 UI_rgbTargetDOORFR "Target RGB control for the front right door";
CM_ SG_ 1657 UI_rgbTargetDOORRL "Target RGB control for rear left door";
CM_ SG_ 1657 UI_rgbTargetDOORRR "Target RGB control for the rear right door";
CM_ SG_ 1657 UI_rgbTargetIPFL "Reports control for RGB lighting for the front left instrument panel.";
CM_ SG_ 1657 UI_rgbTargetIPFR "Reports control for RGB lighting for the front right instrument panel.";
CM_ BO_ 819 "Touchscreen user interface computer message: charge request; forwarded onto this bus by the gateway";
CM_ SG_ 819 UI_openChargePortDoorRequest "Request to open charge port.";
CM_ SG_ 819 UI_closeChargePortDoorRequest "Request to close charge port.";
CM_ SG_ 819 UI_chargeEnableRequest "Charging request initiated";
CM_ SG_ 819 UI_acChargeCurrentLimit "UI charging line current request; raw 127 = signal not available (SNA)";
CM_ SG_ 819 UI_chargeTerminationPct "Charge Termination Limit Percent";
CM_ SG_ 819 UI_scheduledDepartureEnabled "Reports scheduled departure feature enablement.";
CM_ SG_ 819 UI_chargePortLatchRequest "Request to engage or disengage the latch.";
CM_ SG_ 819 UI_cpInletHeaterRequest "Enable charge port inlet heater";
CM_ BO_ 991 "Touchscreen user interface computer message: status2; forwarded onto this bus by the gateway";
CM_ SG_ 991 UI_userActivity "Indicates user interaction with the center display";
CM_ SG_ 991 UI_activeTouchPoints "Quantity of active touch points on the Center Display";
CM_ SG_ 991 UI_linkState "Connectivity link state";
CM_ SG_ 991 UI_autopilotSentryRequest "whether AP sentry mode should be enabled";
CM_ SG_ 991 UI_mobileAppConnected "Reports if Web Real-Time Communication (WebRTC) connection is connected while summon screen is open on the mobile app.";
CM_ SG_ 991 UI_phoneLeftInCabin "Used for monitoring phone left behind feature";
CM_ SG_ 991 UI_autoshiftDRState "Reports the User Interface (UI) autoshift Drive/Reverse state.";
CM_ SG_ 991 UI_wifiBtModuleType "Reports the type of Wi-Fi and Bluetooth (BT) module.";
CM_ SG_ 991 UI_selfParkState "Reports the auto park state changes; raw 255 = signal not available (SNA)";
CM_ SG_ 991 UI_summonDeviceIndex "Reports which device is being used to control summon.";
CM_ SG_ 991 UI_fullScreenMode "Aggregates all situations with which the UI is using the entire screen so stalkless gear controls are not present";
CM_ BO_ 663 "Touchscreen user interface computer message: suspension control; forwarded onto this bus by the gateway";
CM_ SG_ 663 UI_adaptiveRideRequest "UI customer adaptive ride request for air suspension.";
CM_ SG_ 663 UI_geofenceLevelingRequest "Geofence level request from customer; raw 5 = signal not available (SNA)";
CM_ BO_ 947 "Touchscreen user interface computer message: vehicle control2; forwarded onto this bus by the gateway";
CM_ SG_ 947 UI_gloveboxRequest "UI request to open the glovebox";
CM_ SG_ 947 UI_trunkRequest "Rear trunk request";
CM_ SG_ 947 UI_PINToDriveEnabled "UI customer level request to pin to drive enabled.";
CM_ SG_ 947 UI_PINToDrivePassed "UI customer level request to enable drive with pin passed.";
CM_ SG_ 947 UI_disableMirrorAutoDim "Request to disable side and rear-view mirror auto dim";
CM_ SG_ 947 UI_lightSwitch "Headlight mode; raw 4 = signal not available (SNA)";
CM_ SG_ 947 UI_readyToAddKey "Ready to add key";
CM_ SG_ 947 UI_alarmTriggerRequest "Alarm activation request from UI";
CM_ SG_ 947 UI_displayOnForUser "User is present";
CM_ SG_ 947 UI_BLEPushNotificationRequest "Reports that the User Interface (UI) wants to talk to a phone and Vehicle Controller Security (VCSEC) should let all connected phones know.";
CM_ SG_ 947 UI_keepAutopilotAwake "Reports the request for Vehicle Controller (VC) to keep autopilot awake.";
CM_ SG_ 947 UI_batteryPreconditioningRequest "Requests battery preconditioning.";
CM_ SG_ 947 UI_autopilotPowerStateRequest "Requests different power states from autopilot ECU depending on feature usage.";
CM_ SG_ 947 UI_autoRollWindowsOnLockEnable "UI customer level request to enable auto-roll windows on lock";
CM_ SG_ 947 UI_steeringWheelHeatReq "Request to enable steering wheel heater";
CM_ SG_ 947 UI_disableHorn "Request to disable horn";
CM_ SG_ 947 UI_frontLeftSeatFanReq "Request for front left seat ventilation";
CM_ SG_ 947 UI_frontRightSeatAutoClimateReq "UI setting to enable auto seat heating and cooling for front right seat";
CM_ SG_ 947 UI_frontRightSeatFanReq "Request for front left seat ventilation";
CM_ SG_ 947 UI_3RLeftSeatHeatReq "UI request for third row left seat heater";
CM_ SG_ 947 UI_3RRightSeatHeatReq "UI request for third row right seat heater";
CM_ SG_ 947 UI_frontLeftSeatAutoClimateReq "UI setting to enable auto seat heating and cooling for front left seat";
CM_ SG_ 947 UI_wiperHeaterReq "UI request to enable the wiper heater";
CM_ SG_ 947 UI_silentAlarm "Signal indicating alarms should be silenced";
CM_ BO_ 1090 "VCBATT ECU message: pcs interface";
CM_ SG_ 1090 VCBATT_pcsInterfaceMuxIndex "VCBATT ECU: pcs interface mux index";
CM_ SG_ 1090 VCBATT_pcsInterfaceCounter "VCBATT ECU: pcs interface counter";
CM_ SG_ 1090 VCBATT_pcsInterfaceChecksum "VCBATT ECU: pcs interface checksum";
CM_ SG_ 1090 VCBATT_pcsLVVoltageTarget "VCBATT ECU: pcs LV voltage target";
CM_ SG_ 1090 VCBATT_pcsLVMinVoltageLimit "VCBATT ECU: pcs LV min voltage limit";
CM_ SG_ 1090 VCBATT_pcsLVMaxVoltageLimit "VCBATT ECU: pcs LV max voltage limit";
CM_ SG_ 1090 VCBATT_goodForPCSPowerCycle "VCBATT ECU: good for PCS power cycle";
CM_ SG_ 1090 VCBATT_LVBatteryCannotSupportVeh "VCBATT ECU: LV battery cannot support vehicle";
CM_ SG_ 1090 VCBATT_pcsResistanceFiltered "VCBATT ECU: pcs resistance filtered; raw 65535 = signal not available (SNA)";
CM_ SG_ 1090 VCBATT_pcsLVMaxDchrgCurrentLimit "VCBATT ECU: pcs LV max dchrg current limit";
CM_ SG_ 1090 VCBATT_defaultPcsLVVoltageTarget "VCBATT ECU: default pcs LV voltage target";
CM_ SG_ 1090 VCBATT_lvHwProtSelfTestActive "Reports whether Low Voltage (LV) Hardware (HW) protection self-tests are running or about to run due to a retry.";
CM_ SG_ 1090 VCBATT_lvBatteryDischargeRequest "VCBATT ECU: lv battery discharge request";
CM_ BO_ 1027 "VCFRONT1 ECU message: e fuse debug status";
CM_ SG_ 1027 VCFRONT1_eFuseDebugStatusIndex "VCFRONT1 ECU: e fuse debug status index";
CM_ SG_ 1027 VCFRONT1_EPAS2EFuseState "VCFRONT1 ECU: EPAS2 e fuse state";
CM_ SG_ 1027 VCFRONT1_EPAS2EFuseCurrent "VCFRONT1 ECU: EPAS2 e fuse current";
CM_ SG_ 1027 VCFRONT1_EPAS2EFuseOutput "VCFRONT1 ECU: EPAS2 e fuse output";
CM_ SG_ 1027 VCFRONT1_EPAS2EFuseOutputDesired "VCFRONT1 ECU: EPAS2 e fuse output desired";
CM_ SG_ 1027 VCFRONT1_EPAS2EFuseBypass "VCFRONT1 ECU: EPAS2 e fuse bypass";
CM_ SG_ 1027 VCFRONT1_EPAS2EFuseBypassDesired "VCFRONT1 ECU: EPAS2 e fuse bypass desired";
CM_ SG_ 1027 VCFRONT1_EPAS2EFuseVoltage "VCFRONT1 ECU: EPAS2 e fuse voltage";
CM_ SG_ 1027 VCFRONT1_EPAS2EFuseTemperature "VCFRONT1 ECU: EPAS2 e fuse temperature";
CM_ SG_ 1027 VCFRONT1_EPAS2EFuseManagerState "VCFRONT1 ECU: EPAS2 e fuse manager state";
CM_ SG_ 1027 VCFRONT1_EPAS2EFuseHardShortThre "VCFRONT1 ECU: EPAS2 e fuse hard short threshold";
CM_ SG_ 1027 VCFRONT1_EPAS2EFuseOCThreshold "VCFRONT1 ECU: EPAS2 e fuse OC threshold";
CM_ SG_ 1027 VCFRONT1_EPAS2EFuseType "Reports the type of the EPAS2 eFuse.";
CM_ SG_ 1027 VCFRONT1_rightControllerEFuseSta "VCFRONT1 ECU: right controller e fuse state";
CM_ SG_ 1027 VCFRONT1_rightControllerEFuseCur "VCFRONT1 ECU: right controller e fuse current";
CM_ SG_ 1027 VCFRONT1_rightControllerEFuseOut "VCFRONT1 ECU: right controller e fuse output";
CM_ SG_ 1027 VCFRONT1_rightControllerEFu_0002 "VCFRONT1 ECU: right controller e fuse output desired";
CM_ SG_ 1027 VCFRONT1_rightControllerEFuseByp "VCFRONT1 ECU: right controller e fuse bypass";
CM_ SG_ 1027 VCFRONT1_rightControllerEFu_0001 "VCFRONT1 ECU: right controller e fuse bypass desired";
CM_ SG_ 1027 VCFRONT1_rightControllerEFuseVol "VCFRONT1 ECU: right controller e fuse voltage";
CM_ SG_ 1027 VCFRONT1_rightControllerEFuseTem "VCFRONT1 ECU: right controller e fuse temperature";
CM_ SG_ 1027 VCFRONT1_rightControllerEFuseMan "VCFRONT1 ECU: right controller e fuse manager state";
CM_ SG_ 1027 VCFRONT1_rightControllerEFuseHar "VCFRONT1 ECU: right controller e fuse hard short threshold";
CM_ SG_ 1027 VCFRONT1_rightControllerEFuseOCT "VCFRONT1 ECU: right controller e fuse OC threshold";
CM_ SG_ 1027 VCFRONT1_rightControllerEFuseTyp "Reports the type of the right controller eFuse.";
CM_ SG_ 1027 VCFRONT1_autopilot2EFuseState "VCFRONT1 ECU: autopilot2 e fuse state";
CM_ SG_ 1027 VCFRONT1_autopilot2EFuseCurrent "VCFRONT1 ECU: autopilot2 e fuse current";
CM_ SG_ 1027 VCFRONT1_autopilot2EFuseOutput "VCFRONT1 ECU: autopilot2 e fuse output";
CM_ SG_ 1027 VCFRONT1_autopilot2EFuseOutputDe "VCFRONT1 ECU: autopilot2 e fuse output desired";
CM_ SG_ 1027 VCFRONT1_autopilot2EFuseBypass "VCFRONT1 ECU: autopilot2 e fuse bypass";
CM_ SG_ 1027 VCFRONT1_autopilot2EFuseBypassDe "VCFRONT1 ECU: autopilot2 e fuse bypass desired";
CM_ SG_ 1027 VCFRONT1_autopilot2EFuseVoltage "VCFRONT1 ECU: autopilot2 e fuse voltage";
CM_ SG_ 1027 VCFRONT1_autopilot2EFuseTemperat "VCFRONT1 ECU: autopilot2 e fuse temperature";
CM_ SG_ 1027 VCFRONT1_autopilot2EFuseManagerS "VCFRONT1 ECU: autopilot2 e fuse manager state";
CM_ SG_ 1027 VCFRONT1_autopilot2EFuseHardShor "VCFRONT1 ECU: autopilot2 e fuse hard short threshold";
CM_ SG_ 1027 VCFRONT1_autopilot2EFuseOCThresh "VCFRONT1 ECU: autopilot2 e fuse OC threshold";
CM_ SG_ 1027 VCFRONT1_autopilot2EFuseType "Reports the type of the autopilot2 eFuse.";
CM_ BO_ 609 "Front body controller message: 12 v battery status";
CM_ SG_ 609 VCFRONT_12VBatteryStatusIndex "Front body controller: 12 v battery status index";
CM_ SG_ 609 VCFRONT_good12VforUpdate "Indicates the Low Voltage (LV) battery health as it pertains to permitting an Over-The-Air (OTA) update.";
CM_ SG_ 609 VCFRONT_LVLoadRequest "Controls the loading of the Low Voltage (LV) battery for diagnostic purposes.";
CM_ SG_ 609 VCFRONT_12VBatteryStatusCounter "Front body controller: 12 v battery status counter";
CM_ SG_ 609 VCFRONT_12VBatteryStatusChecksum "Front body controller: 12 v battery status checksum";
CM_ SG_ 609 VCFRONT_batterySupportRequest "Reports the request to the Power Conversion System (PCS) to supply power to the Low Voltage (LV) battery.";
CM_ SG_ 609 VCFRONT_batterySMState "Reports the Low Voltage (LV) battery maintenance state machine state.";
CM_ SG_ 609 VCFRONT_eFuseRecoveryStateDBG "Reports the state of the Low Voltage (LV) battery eFuse recovery state machine.";
CM_ SG_ 609 VCFRONT_batteryLINScheduleDBG "Front body controller: battery LIN schedule DBG; raw 7 = signal not available (SNA)";
CM_ SG_ 609 VCFRONT_resistanceEstimationTest "Front body controller: resistance estimation test counter";
CM_ SG_ 609 VCFRONT_IBSCurrent "Electrical current into the 12V battery";
CM_ SG_ 609 VCFRONT_IBSVoltage "Voltage of the 12V battery; raw 4095 = signal not available (SNA)";
CM_ SG_ 609 VCFRONT_reverseBatteryFault "Indicates a fault on the reverse battery eFuse.";
CM_ SG_ 609 VCFRONT_LVBatterySupported "Indicates whether the Low Voltage (LV) battery is being supported.";
CM_ SG_ 609 VCFRONT_LVBatteryCannotSupportVe "Front body controller: LV battery cannot support vehicle";
CM_ SG_ 609 VCFRONT_goodTemp12VforUpdate "Front body controller: good temp12 vfor update";
CM_ SG_ 609 VCFRONT_12VBatteryTargetVoltage "Reports the target Low Voltage (LV) battery voltage.";
CM_ SG_ 609 VCFRONT_IBSTemperature "Front body controller: IBS temperature; raw 2047 = signal not available (SNA)";
CM_ SG_ 609 VCFRONT_currentSensorMismatchLea "Front body controller: current sensor mismatch leaky bkt pct DBG";
CM_ SG_ 609 VCFRONT_LVBatteryEnergyRemaining "Reports the percentage of energy remaining in the Low Voltage (LV) battery.";
CM_ SG_ 609 VCFRONT_LVBatteryStatusForDrive "Indicates the Low Voltage (LV) battery health status as it pertains to drive readiness. May trigger a Graceful Power Off (GPO) and block drive.";
CM_ SG_ 609 VCFRONT_LVBatteryType "Reports the type of Low Voltage (LV) battery that the firmware is configured for.";
CM_ SG_ 609 VCFRONT_resistanceEstimationNeed "Indication that the conditions which require a resistance estimation test to be performed have been met";
CM_ SG_ 609 VCFRONT_IBSVoltageFiltered "Measures the filtered voltage of the Low Voltage (LV) bus; raw 16383 = signal not available (SNA)";
CM_ SG_ 609 VCFRONT_LVBMS_LVBusVoltageSource "Reports the source of the Low Voltage (LV) bus voltage used for the Low Voltage Battery Management System (LVBMS).";
CM_ SG_ 609 VCFRONT_LVBMS_LVPackCurrentSourc "Reports the source of the Low Voltage (LV) pack current used for LV battery charge regulation.";
CM_ SG_ 609 VCFRONT_LVBatterySupportRqrdTrig "Reports what caused the Low Voltage (LV) battery support required trigger when the vehicle wakes to charge.";
CM_ SG_ 609 VCFRONT_goodForPCSPowerCycleLeak "Front body controller: good for PCS power cycle leaky bkt DBG";
CM_ SG_ 609 VCFRONT_LVBusControlsFutile "Indicates that a required condition is not met for the Low Voltage (LV) bus controllers to operate properly.";
CM_ SG_ 609 VCFRONT_resistanceEstimatio_0001 "Front body controller: resistance estimation test valid";
CM_ SG_ 609 VCFRONT_resistanceEstimatio_0002 "Front body controller: resistance estimation tests expended";
CM_ SG_ 609 VCFRONT_goodLVChargeForUpdate "Indicates that the Low Voltage (LV) battery charge is sufficient to permit an Over-The-Air (OTA) update.";
CM_ SG_ 609 VCFRONT_opportunisticDCRTestNeed "Front body controller: opportunistic DCR test needed";
CM_ SG_ 609 VCFRONT_voltageProfile "Indicates which voltage profile is used to support the 12V battery";
CM_ SG_ 609 VCFRONT_IBSAmpHours "Measures the energy state of the Low Voltage (LV) battery in amp hours.";
CM_ SG_ 609 VCFRONT_IBSVoltageRawDBG "Front body controller: IBS voltage raw DBG; raw 16383 = signal not available (SNA)";
CM_ SG_ 609 VCFRONT_LVBatteryLINCommsDetecte "Front body controller: LV battery LIN comms detected DBG";
CM_ SG_ 609 VCFRONT_voltageSensorMismatchLea "Front body controller: voltage sensor mismatch leaky bkt pct DBG";
CM_ SG_ 609 VCFRONT_LVBusControlMode "Front body controller: LV bus control mode";
CM_ SG_ 609 VCFRONT_resistanceEstimationExte "Front body controller: resistance estimation extended test enabled";
CM_ SG_ 609 VCFRONT_LVBatteryFctryLimOverrid "Front body controller: LV battery fctry lim override ok";
CM_ SG_ 609 VCFRONT_LVBatterySPICommsDetecte "Front body controller: LV battery SPI comms detected DBG";
CM_ SG_ 609 VCFRONT_targetCurrent "Reports the target current set by the Low Voltage Battery Management System (LVBMS).";
CM_ SG_ 609 VCFRONT_PCSMia "Indicates that the Power Conversion System (PCS) is not communicating on CAN.";
CM_ SG_ 609 VCFRONT_chargeNeeded "Indicates that the Low Voltage (LV) battery needs to be charged.";
CM_ SG_ 609 VCFRONT_voltageControlLoopIntegr "Front body controller: voltage control loop integration val";
CM_ SG_ 609 VCFRONT_currentControlLoopIntegr "Front body controller: current control loop integration val";
BA_DEF_ "BusType" STRING;
BA_DEF_ "DBName" STRING;
BA_DEF_ "Baudrate" INT 0 1000000;
BA_DEF_ "BaudrateCANFD" INT 0 16000000;
BA_DEF_ "Manufacturer" STRING;
BA_DEF_ "FirmwareVersion" STRING;
BA_DEF_ "VehicleModel" STRING;
BA_DEF_ BU_ "ECU" STRING;
BA_DEF_ BO_ "GenMsgCycleTime" INT 0 3600000;
BA_DEF_ BO_ "GenMsgSendType" ENUM "Cyclic","NotUsed","NotUsed","NotUsed","NotUsed","NotUsed","NotUsed","IfActive","NoMsgSendType","NotUsed";
BA_DEF_ BO_ "VFrameFormat" ENUM "StandardCAN","ExtendedCAN","reserved","J1939PG","reserved","reserved","reserved","reserved","reserved","reserved","reserved","reserved","reserved","reserved","StandardCAN_FD","ExtendedCAN_FD";
BA_DEF_ BO_ "CANFD_BRS" ENUM "0","1";
BA_DEF_ SG_ "GenSigSNA" STRING;
BA_DEF_ SG_ "SystemSignalLongSymbol" STRING;
BA_DEF_ SG_ "Confidence" ENUM "validated","plausible","layout-only","contradicted";
BA_DEF_DEF_ "BusType" "CAN";
BA_DEF_DEF_ "DBName" "";
BA_DEF_DEF_ "Baudrate" 500000;
BA_DEF_DEF_ "BaudrateCANFD" 2000000;
BA_DEF_DEF_ "Manufacturer" "";
BA_DEF_DEF_ "FirmwareVersion" "";
BA_DEF_DEF_ "VehicleModel" "";
BA_DEF_DEF_ "ECU" "";
BA_DEF_DEF_ "GenMsgCycleTime" 0;
BA_DEF_DEF_ "GenMsgSendType" "NoMsgSendType";
BA_DEF_DEF_ "VFrameFormat" "StandardCAN";
BA_DEF_DEF_ "CANFD_BRS" "1";
BA_DEF_DEF_ "GenSigSNA" "";
BA_DEF_DEF_ "SystemSignalLongSymbol" "";
BA_DEF_DEF_ "Confidence" "layout-only";
BA_ "DBName" "ModelY_VEH";
BA_ "Manufacturer" "Tesla";
BA_ "FirmwareVersion" "2026.26.6.5";
BA_ "VehicleModel" "Model Y";
BA_ "ECU" BU_ BMS "BMS";
BA_ "ECU" BU_ CP "CP";
BA_ "ECU" BU_ DAS "DAS";
BA_ "ECU" BU_ DIF "DIF";
BA_ "ECU" BU_ GTW "GTW";
BA_ "ECU" BU_ HVP "HVP";
BA_ "ECU" BU_ ICR "ICR";
BA_ "ECU" BU_ PCS "PCS";
BA_ "ECU" BU_ SCCM "SCCM";
BA_ "ECU" BU_ VCBATT "VCBATT";
BA_ "ECU" BU_ VCFRONT "VCFRONT";
BA_ "ECU" BU_ VCFRONT1 "VCFRONT1";
BA_ "ECU" BU_ VCLEFT "VCLEFT";
BA_ "ECU" BU_ VCRIGHT "VCRIGHT";
BA_ "ECU" BU_ VCSEC "VCSEC";
BA_ "GenMsgCycleTime" BO_ 1025 1000;
BA_ "GenMsgSendType" BO_ 1025 0;
BA_ "GenMsgCycleTime" BO_ 1138 1000;
BA_ "GenMsgSendType" BO_ 1138 0;
BA_ "GenMsgCycleTime" BO_ 1071 1000;
BA_ "GenMsgSendType" BO_ 1071 0;
BA_ "GenMsgCycleTime" BO_ 669 100;
BA_ "GenMsgSendType" BO_ 669 0;
BA_ "GenMsgCycleTime" BO_ 541 100;
BA_ "GenMsgSendType" BO_ 541 0;
BA_ "GenMsgCycleTime" BO_ 1001 500;
BA_ "GenMsgSendType" BO_ 1001 0;
BA_ "GenMsgCycleTime" BO_ 634 100;
BA_ "GenMsgSendType" BO_ 634 0;
BA_ "GenMsgCycleTime" BO_ 784 10000;
BA_ "GenMsgSendType" BO_ 784 0;
BA_ "GenMsgCycleTime" BO_ 941 10000;
BA_ "GenMsgSendType" BO_ 941 0;
BA_ "GenMsgCycleTime" BO_ 964 1000;
BA_ "GenMsgSendType" BO_ 964 0;
BA_ "GenMsgCycleTime" BO_ 816 1000;
BA_ "GenMsgSendType" BO_ 816 0;
BA_ "GenMsgCycleTime" BO_ 1657 500;
BA_ "GenMsgSendType" BO_ 1657 0;
BA_ "GenMsgCycleTime" BO_ 819 500;
BA_ "GenMsgSendType" BO_ 819 0;
BA_ "GenMsgCycleTime" BO_ 991 500;
BA_ "GenMsgSendType" BO_ 991 0;
BA_ "GenMsgCycleTime" BO_ 663 500;
BA_ "GenMsgSendType" BO_ 663 0;
BA_ "GenMsgCycleTime" BO_ 947 500;
BA_ "GenMsgSendType" BO_ 947 0;
BA_ "GenMsgCycleTime" BO_ 1090 50;
BA_ "GenMsgSendType" BO_ 1090 0;
BA_ "GenMsgCycleTime" BO_ 1027 200;
BA_ "GenMsgSendType" BO_ 1027 0;
BA_ "GenMsgCycleTime" BO_ 609 16;
BA_ "GenMsgSendType" BO_ 609 0;
BA_ "Confidence" SG_ 1025 BMS_brickVoltageMultiplexer 1;
BA_ "Confidence" SG_ 1025 BMS_brickVoltageCounter 0;
BA_ "Confidence" SG_ 1025 BMS_brickVoltageStatus1 0;
BA_ "Confidence" SG_ 1025 BMS_brickVoltageStatus2 0;
BA_ "Confidence" SG_ 1025 BMS_brickVoltageStatus3 0;
BA_ "Confidence" SG_ 1025 BMS_brickVoltage1 0;
BA_ "Confidence" SG_ 1025 BMS_brickVoltage2 0;
BA_ "Confidence" SG_ 1025 BMS_brickVoltage3 0;
BA_ "Confidence" SG_ 1025 BMS_brickVoltageStatus4 0;
BA_ "Confidence" SG_ 1025 BMS_brickVoltageStatus5 0;
BA_ "Confidence" SG_ 1025 BMS_brickVoltageStatus6 0;
BA_ "Confidence" SG_ 1025 BMS_brickVoltage4 0;
BA_ "Confidence" SG_ 1025 BMS_brickVoltage5 0;
BA_ "Confidence" SG_ 1025 BMS_brickVoltage6 0;
BA_ "Confidence" SG_ 1025 BMS_brickVoltageStatus7 0;
BA_ "Confidence" SG_ 1025 BMS_brickVoltageStatus8 0;
BA_ "Confidence" SG_ 1025 BMS_brickVoltageStatus9 0;
BA_ "Confidence" SG_ 1025 BMS_brickVoltage7 0;
BA_ "Confidence" SG_ 1025 BMS_brickVoltage8 0;
BA_ "Confidence" SG_ 1025 BMS_brickVoltage9 0;
BA_ "Confidence" SG_ 1025 BMS_brickVoltageStatus10 0;
BA_ "Confidence" SG_ 1025 BMS_brickVoltageStatus11 0;
BA_ "Confidence" SG_ 1025 BMS_brickVoltageStatus12 0;
BA_ "Confidence" SG_ 1025 BMS_brickVoltage10 0;
BA_ "Confidence" SG_ 1025 BMS_brickVoltage11 0;
BA_ "Confidence" SG_ 1025 BMS_brickVoltage12 0;
BA_ "Confidence" SG_ 1025 BMS_brickVoltageStatus13 0;
BA_ "Confidence" SG_ 1025 BMS_brickVoltageStatus14 0;
BA_ "Confidence" SG_ 1025 BMS_brickVoltageStatus15 0;
BA_ "Confidence" SG_ 1025 BMS_brickVoltage13 0;
BA_ "Confidence" SG_ 1025 BMS_brickVoltage14 0;
BA_ "Confidence" SG_ 1025 BMS_brickVoltage15 0;
BA_ "Confidence" SG_ 1025 BMS_brickVoltageStatus16 0;
BA_ "Confidence" SG_ 1025 BMS_brickVoltageStatus17 0;
BA_ "Confidence" SG_ 1025 BMS_brickVoltageStatus18 0;
BA_ "Confidence" SG_ 1025 BMS_brickVoltage16 0;
BA_ "Confidence" SG_ 1025 BMS_brickVoltage17 0;
BA_ "Confidence" SG_ 1025 BMS_brickVoltage18 0;
BA_ "Confidence" SG_ 1025 BMS_brickVoltageStatus19 0;
BA_ "Confidence" SG_ 1025 BMS_brickVoltageStatus20 0;
BA_ "Confidence" SG_ 1025 BMS_brickVoltageStatus21 0;
BA_ "Confidence" SG_ 1025 BMS_brickVoltage19 0;
BA_ "Confidence" SG_ 1025 BMS_brickVoltage20 0;
BA_ "Confidence" SG_ 1025 BMS_brickVoltage21 0;
BA_ "Confidence" SG_ 1025 BMS_brickVoltageStatus22 0;
BA_ "Confidence" SG_ 1025 BMS_brickVoltageStatus23 0;
BA_ "Confidence" SG_ 1025 BMS_brickVoltageStatus24 0;
BA_ "Confidence" SG_ 1025 BMS_brickVoltage22 0;
BA_ "Confidence" SG_ 1025 BMS_brickVoltage23 0;
BA_ "Confidence" SG_ 1025 BMS_brickVoltage24 0;
BA_ "Confidence" SG_ 1025 BMS_brickVoltageStatus25 0;
BA_ "Confidence" SG_ 1025 BMS_brickVoltageStatus26 0;
BA_ "Confidence" SG_ 1025 BMS_brickVoltageStatus27 0;
BA_ "Confidence" SG_ 1025 BMS_brickVoltage25 0;
BA_ "Confidence" SG_ 1025 BMS_brickVoltage26 0;
BA_ "Confidence" SG_ 1025 BMS_brickVoltage27 0;
BA_ "Confidence" SG_ 1025 BMS_brickVoltageStatus28 0;
BA_ "Confidence" SG_ 1025 BMS_brickVoltageStatus29 0;
BA_ "Confidence" SG_ 1025 BMS_brickVoltageStatus30 0;
BA_ "Confidence" SG_ 1025 BMS_brickVoltage28 0;
BA_ "Confidence" SG_ 1025 BMS_brickVoltage29 0;
BA_ "Confidence" SG_ 1025 BMS_brickVoltage30 0;
BA_ "Confidence" SG_ 1025 BMS_brickVoltageStatus31 0;
BA_ "Confidence" SG_ 1025 BMS_brickVoltageStatus32 0;
BA_ "Confidence" SG_ 1025 BMS_brickVoltageStatus33 0;
BA_ "Confidence" SG_ 1025 BMS_brickVoltage31 0;
BA_ "Confidence" SG_ 1025 BMS_brickVoltage32 0;
BA_ "Confidence" SG_ 1025 BMS_brickVoltage33 0;
BA_ "Confidence" SG_ 1025 BMS_brickVoltageStatus34 0;
BA_ "Confidence" SG_ 1025 BMS_brickVoltageStatus35 0;
BA_ "Confidence" SG_ 1025 BMS_brickVoltageStatus36 0;
BA_ "Confidence" SG_ 1025 BMS_brickVoltage34 0;
BA_ "Confidence" SG_ 1025 BMS_brickVoltage35 0;
BA_ "Confidence" SG_ 1025 BMS_brickVoltage36 0;
BA_ "Confidence" SG_ 1025 BMS_brickVoltageStatus37 0;
BA_ "Confidence" SG_ 1025 BMS_brickVoltageStatus38 0;
BA_ "Confidence" SG_ 1025 BMS_brickVoltageStatus39 0;
BA_ "Confidence" SG_ 1025 BMS_brickVoltage37 0;
BA_ "Confidence" SG_ 1025 BMS_brickVoltage38 0;
BA_ "Confidence" SG_ 1025 BMS_brickVoltage39 0;
BA_ "Confidence" SG_ 1025 BMS_brickVoltageStatus40 0;
BA_ "Confidence" SG_ 1025 BMS_brickVoltageStatus41 0;
BA_ "Confidence" SG_ 1025 BMS_brickVoltageStatus42 0;
BA_ "Confidence" SG_ 1025 BMS_brickVoltage40 0;
BA_ "Confidence" SG_ 1025 BMS_brickVoltage41 0;
BA_ "Confidence" SG_ 1025 BMS_brickVoltage42 0;
BA_ "Confidence" SG_ 1025 BMS_brickVoltageStatus43 0;
BA_ "Confidence" SG_ 1025 BMS_brickVoltageStatus44 0;
BA_ "Confidence" SG_ 1025 BMS_brickVoltageStatus45 0;
BA_ "Confidence" SG_ 1025 BMS_brickVoltage43 0;
BA_ "Confidence" SG_ 1025 BMS_brickVoltage44 0;
BA_ "Confidence" SG_ 1025 BMS_brickVoltage45 0;
BA_ "Confidence" SG_ 1025 BMS_brickVoltageStatus46 0;
BA_ "Confidence" SG_ 1025 BMS_brickVoltageStatus47 0;
BA_ "Confidence" SG_ 1025 BMS_brickVoltageStatus48 0;
BA_ "Confidence" SG_ 1025 BMS_brickVoltage46 0;
BA_ "Confidence" SG_ 1025 BMS_brickVoltage47 0;
BA_ "Confidence" SG_ 1025 BMS_brickVoltage48 0;
BA_ "Confidence" SG_ 1025 BMS_brickVoltageStatus49 0;
BA_ "Confidence" SG_ 1025 BMS_brickVoltageStatus50 0;
BA_ "Confidence" SG_ 1025 BMS_brickVoltageStatus51 0;
BA_ "Confidence" SG_ 1025 BMS_brickVoltage49 0;
BA_ "Confidence" SG_ 1025 BMS_brickVoltage50 0;
BA_ "Confidence" SG_ 1025 BMS_brickVoltage51 0;
BA_ "Confidence" SG_ 1025 BMS_brickVoltageStatus52 0;
BA_ "Confidence" SG_ 1025 BMS_brickVoltageStatus53 0;
BA_ "Confidence" SG_ 1025 BMS_brickVoltageStatus54 0;
BA_ "Confidence" SG_ 1025 BMS_brickVoltage52 0;
BA_ "Confidence" SG_ 1025 BMS_brickVoltage53 0;
BA_ "Confidence" SG_ 1025 BMS_brickVoltage54 0;
BA_ "Confidence" SG_ 1025 BMS_brickVoltageStatus55 0;
BA_ "Confidence" SG_ 1025 BMS_brickVoltageStatus56 0;
BA_ "Confidence" SG_ 1025 BMS_brickVoltageStatus57 0;
BA_ "Confidence" SG_ 1025 BMS_brickVoltage55 0;
BA_ "Confidence" SG_ 1025 BMS_brickVoltage56 0;
BA_ "Confidence" SG_ 1025 BMS_brickVoltage57 0;
BA_ "Confidence" SG_ 1025 BMS_brickVoltageStatus58 0;
BA_ "Confidence" SG_ 1025 BMS_brickVoltageStatus59 0;
BA_ "Confidence" SG_ 1025 BMS_brickVoltageStatus60 0;
BA_ "Confidence" SG_ 1025 BMS_brickVoltage58 0;
BA_ "Confidence" SG_ 1025 BMS_brickVoltage59 0;
BA_ "Confidence" SG_ 1025 BMS_brickVoltage60 0;
BA_ "Confidence" SG_ 1025 BMS_brickVoltageStatus61 0;
BA_ "Confidence" SG_ 1025 BMS_brickVoltageStatus62 0;
BA_ "Confidence" SG_ 1025 BMS_brickVoltageStatus63 0;
BA_ "Confidence" SG_ 1025 BMS_brickVoltage61 0;
BA_ "Confidence" SG_ 1025 BMS_brickVoltage62 0;
BA_ "Confidence" SG_ 1025 BMS_brickVoltage63 0;
BA_ "Confidence" SG_ 1025 BMS_brickVoltageStatus64 0;
BA_ "Confidence" SG_ 1025 BMS_brickVoltageStatus65 0;
BA_ "Confidence" SG_ 1025 BMS_brickVoltageStatus66 0;
BA_ "Confidence" SG_ 1025 BMS_brickVoltage64 0;
BA_ "Confidence" SG_ 1025 BMS_brickVoltage65 0;
BA_ "Confidence" SG_ 1025 BMS_brickVoltage66 0;
BA_ "Confidence" SG_ 1025 BMS_brickVoltageStatus67 0;
BA_ "Confidence" SG_ 1025 BMS_brickVoltageStatus68 0;
BA_ "Confidence" SG_ 1025 BMS_brickVoltageStatus69 0;
BA_ "Confidence" SG_ 1025 BMS_brickVoltage67 0;
BA_ "Confidence" SG_ 1025 BMS_brickVoltage68 0;
BA_ "Confidence" SG_ 1025 BMS_brickVoltage69 0;
BA_ "Confidence" SG_ 1025 BMS_brickVoltageStatus70 0;
BA_ "Confidence" SG_ 1025 BMS_brickVoltageStatus71 0;
BA_ "Confidence" SG_ 1025 BMS_brickVoltageStatus72 0;
BA_ "Confidence" SG_ 1025 BMS_brickVoltage70 0;
BA_ "Confidence" SG_ 1025 BMS_brickVoltage71 0;
BA_ "Confidence" SG_ 1025 BMS_brickVoltage72 0;
BA_ "Confidence" SG_ 1025 BMS_brickVoltageStatus73 0;
BA_ "Confidence" SG_ 1025 BMS_brickVoltageStatus74 0;
BA_ "Confidence" SG_ 1025 BMS_brickVoltageStatus75 0;
BA_ "Confidence" SG_ 1025 BMS_brickVoltage73 0;
BA_ "Confidence" SG_ 1025 BMS_brickVoltage74 0;
BA_ "Confidence" SG_ 1025 BMS_brickVoltage75 0;
BA_ "Confidence" SG_ 1025 BMS_brickVoltageStatus76 0;
BA_ "Confidence" SG_ 1025 BMS_brickVoltageStatus77 0;
BA_ "Confidence" SG_ 1025 BMS_brickVoltageStatus78 0;
BA_ "Confidence" SG_ 1025 BMS_brickVoltage76 0;
BA_ "Confidence" SG_ 1025 BMS_brickVoltage77 0;
BA_ "Confidence" SG_ 1025 BMS_brickVoltage78 0;
BA_ "Confidence" SG_ 1025 BMS_brickVoltageStatus79 0;
BA_ "Confidence" SG_ 1025 BMS_brickVoltageStatus80 0;
BA_ "Confidence" SG_ 1025 BMS_brickVoltageStatus81 0;
BA_ "Confidence" SG_ 1025 BMS_brickVoltage79 0;
BA_ "Confidence" SG_ 1025 BMS_brickVoltage80 0;
BA_ "Confidence" SG_ 1025 BMS_brickVoltage81 0;
BA_ "Confidence" SG_ 1025 BMS_brickVoltageStatus82 0;
BA_ "Confidence" SG_ 1025 BMS_brickVoltageStatus83 0;
BA_ "Confidence" SG_ 1025 BMS_brickVoltageStatus84 0;
BA_ "Confidence" SG_ 1025 BMS_brickVoltage82 0;
BA_ "Confidence" SG_ 1025 BMS_brickVoltage83 0;
BA_ "Confidence" SG_ 1025 BMS_brickVoltage84 0;
BA_ "Confidence" SG_ 1025 BMS_brickVoltageStatus85 0;
BA_ "Confidence" SG_ 1025 BMS_brickVoltageStatus86 0;
BA_ "Confidence" SG_ 1025 BMS_brickVoltageStatus87 0;
BA_ "Confidence" SG_ 1025 BMS_brickVoltage85 0;
BA_ "Confidence" SG_ 1025 BMS_brickVoltage86 0;
BA_ "Confidence" SG_ 1025 BMS_brickVoltage87 0;
BA_ "Confidence" SG_ 1025 BMS_brickVoltageStatus88 0;
BA_ "Confidence" SG_ 1025 BMS_brickVoltageStatus89 0;
BA_ "Confidence" SG_ 1025 BMS_brickVoltageStatus90 0;
BA_ "Confidence" SG_ 1025 BMS_brickVoltage88 0;
BA_ "Confidence" SG_ 1025 BMS_brickVoltage89 0;
BA_ "Confidence" SG_ 1025 BMS_brickVoltage90 0;
BA_ "Confidence" SG_ 1025 BMS_brickVoltageStatus91 0;
BA_ "Confidence" SG_ 1025 BMS_brickVoltageStatus92 0;
BA_ "Confidence" SG_ 1025 BMS_brickVoltageStatus93 0;
BA_ "Confidence" SG_ 1025 BMS_brickVoltage91 0;
BA_ "Confidence" SG_ 1025 BMS_brickVoltage92 0;
BA_ "Confidence" SG_ 1025 BMS_brickVoltage93 0;
BA_ "Confidence" SG_ 1025 BMS_brickVoltageStatus94 0;
BA_ "Confidence" SG_ 1025 BMS_brickVoltageStatus95 0;
BA_ "Confidence" SG_ 1025 BMS_brickVoltageStatus96 0;
BA_ "Confidence" SG_ 1025 BMS_brickVoltage94 0;
BA_ "Confidence" SG_ 1025 BMS_brickVoltage95 0;
BA_ "Confidence" SG_ 1025 BMS_brickVoltage96 0;
BA_ "Confidence" SG_ 1025 BMS_brickVoltageStatus97 0;
BA_ "Confidence" SG_ 1025 BMS_brickVoltageStatus98 0;
BA_ "Confidence" SG_ 1025 BMS_brickVoltageStatus99 0;
BA_ "Confidence" SG_ 1025 BMS_brickVoltage97 0;
BA_ "Confidence" SG_ 1025 BMS_brickVoltage98 0;
BA_ "Confidence" SG_ 1025 BMS_brickVoltage99 0;
BA_ "Confidence" SG_ 1025 BMS_brickVoltageStatus100 0;
BA_ "Confidence" SG_ 1025 BMS_brickVoltageStatus101 0;
BA_ "Confidence" SG_ 1025 BMS_brickVoltageStatus102 0;
BA_ "Confidence" SG_ 1025 BMS_brickVoltage100 0;
BA_ "Confidence" SG_ 1025 BMS_brickVoltage101 0;
BA_ "Confidence" SG_ 1025 BMS_brickVoltage102 0;
BA_ "Confidence" SG_ 1025 BMS_brickVoltageStatus103 0;
BA_ "Confidence" SG_ 1025 BMS_brickVoltageStatus104 0;
BA_ "Confidence" SG_ 1025 BMS_brickVoltageStatus105 0;
BA_ "Confidence" SG_ 1025 BMS_brickVoltage103 0;
BA_ "Confidence" SG_ 1025 BMS_brickVoltage104 0;
BA_ "Confidence" SG_ 1025 BMS_brickVoltage105 0;
BA_ "Confidence" SG_ 1025 BMS_brickVoltageStatus106 0;
BA_ "Confidence" SG_ 1025 BMS_brickVoltageStatus107 0;
BA_ "Confidence" SG_ 1025 BMS_brickVoltageStatus108 0;
BA_ "Confidence" SG_ 1025 BMS_brickVoltage106 0;
BA_ "Confidence" SG_ 1025 BMS_brickVoltage107 0;
BA_ "Confidence" SG_ 1025 BMS_brickVoltage108 0;
BA_ "Confidence" SG_ 1138 BMS_acChargePowerSample 0;
BA_ "GenSigSNA" SG_ 1138 BMS_acChargePowerSample "255";
BA_ "Confidence" SG_ 1138 BMS_voltageRegCurrentTarget 0;
BA_ "Confidence" SG_ 1138 BMS_vehicleChargeDcCurrentLimit 0;
BA_ "Confidence" SG_ 1138 BMS_userChargeCurrentLimitMode 0;
BA_ "Confidence" SG_ 1138 BMS_chargeCurrentLimitMode 0;
BA_ "Confidence" SG_ 1138 BMS_timeToFinishHeatForCharge 0;
BA_ "GenSigSNA" SG_ 1138 BMS_timeToFinishHeatForCharge "127";
BA_ "Confidence" SG_ 1138 BMS_timeToTripPlanChargingTarget 0;
BA_ "GenSigSNA" SG_ 1138 BMS_timeToTripPlanChargingTarget "2047";
BA_ "Confidence" SG_ 1138 BMS_useChargeTimeEstimate 0;
BA_ "Confidence" SG_ 1071 BMS_v2xSoe 0;
BA_ "GenSigSNA" SG_ 1071 BMS_v2xSoe "65535";
BA_ "Confidence" SG_ 1071 BMS_v2xFullEnergy 0;
BA_ "GenSigSNA" SG_ 1071 BMS_v2xFullEnergy "4095";
BA_ "Confidence" SG_ 1071 BMS_v2xPackPower 0;
BA_ "GenSigSNA" SG_ 1071 BMS_v2xPackPower "511";
BA_ "Confidence" SG_ 1071 BMS_acDischargeBlockedReason 0;
BA_ "Confidence" SG_ 1071 BMS_backupTimeRemaining 0;
BA_ "GenSigSNA" SG_ 1071 BMS_backupTimeRemaining "255";
BA_ "Confidence" SG_ 669 CP_evseOutputDcCurrent 0;
BA_ "Confidence" SG_ 669 CP_evseOutputDcVoltage 0;
BA_ "Confidence" SG_ 669 CP_evseOutputDcCurrentStale 0;
BA_ "Confidence" SG_ 669 CP_evRelocationRecommended 0;
BA_ "Confidence" SG_ 669 CP_evseDeratingReason 0;
BA_ "Confidence" SG_ 541 CP_evseAccept 0;
BA_ "Confidence" SG_ 541 CP_evseRequest 0;
BA_ "Confidence" SG_ 541 CP_proximity 0;
BA_ "GenSigSNA" SG_ 541 CP_proximity "0";
BA_ "Confidence" SG_ 541 CP_pilot 0;
BA_ "GenSigSNA" SG_ 541 CP_pilot "7";
BA_ "Confidence" SG_ 541 CP_digitalCommsEstablished 0;
BA_ "Confidence" SG_ 541 CP_pilotCurrent 0;
BA_ "Confidence" SG_ 541 CP_cableType 0;
BA_ "GenSigSNA" SG_ 541 CP_cableType "5";
BA_ "Confidence" SG_ 541 CP_iecPilotState 0;
BA_ "GenSigSNA" SG_ 541 CP_iecPilotState "9";
BA_ "Confidence" SG_ 541 CP_plcSupported 0;
BA_ "Confidence" SG_ 541 CP_cableCurrentLimit 0;
BA_ "Confidence" SG_ 541 CP_teslaSwcanState 0;
BA_ "Confidence" SG_ 541 CP_evseChargeType_UI 0;
BA_ "Confidence" SG_ 541 CP_gbState 0;
BA_ "Confidence" SG_ 541 CP_gbdcStopChargeReason 0;
BA_ "Confidence" SG_ 541 CP_gbdcFailureReason 0;
BA_ "Confidence" SG_ 541 CP_gbdcChargeAttempts 0;
BA_ "Confidence" SG_ 541 CP_acChargeState 0;
BA_ "Confidence" SG_ 541 CP_acChargeType 0;
BA_ "Confidence" SG_ 541 CP_teslaDcState 0;
BA_ "Confidence" SG_ 1001 DAS_headlightRequest 0;
BA_ "Confidence" SG_ 1001 DAS_hazardLightRequest 0;
BA_ "GenSigSNA" SG_ 1001 DAS_hazardLightRequest "3";
BA_ "Confidence" SG_ 1001 DAS_wiperSpeed 0;
BA_ "Confidence" SG_ 1001 DAS_turnIndicatorRequest 0;
BA_ "Confidence" SG_ 1001 DAS_highLowBeamDecision 0;
BA_ "GenSigSNA" SG_ 1001 DAS_highLowBeamDecision "3";
BA_ "Confidence" SG_ 1001 DAS_heaterRequest 0;
BA_ "GenSigSNA" SG_ 1001 DAS_heaterRequest "0";
BA_ "Confidence" SG_ 1001 DAS_highLowBeamOffReason 0;
BA_ "GenSigSNA" SG_ 1001 DAS_highLowBeamOffReason "5";
BA_ "Confidence" SG_ 1001 DAS_forwardCamHeaterDutyCycle 0;
BA_ "Confidence" SG_ 1001 DAS_dynamicBrakeLightRequest 0;
BA_ "Confidence" SG_ 1001 DAS_radarHeaterRequest 0;
BA_ "Confidence" SG_ 1001 DAS_ahlbOverride 0;
BA_ "Confidence" SG_ 1001 DAS_mirrorFoldRequest 0;
BA_ "GenSigSNA" SG_ 1001 DAS_mirrorFoldRequest "3";
BA_ "Confidence" SG_ 1001 DAS_wiperWashRequest 0;
BA_ "Confidence" SG_ 1001 DAS_ulcConfirmationRequestActive 0;
BA_ "Confidence" SG_ 1001 DAS_overrideWiperSetting 0;
BA_ "Confidence" SG_ 1001 DAS_autoWiperState 0;
BA_ "GenSigSNA" SG_ 1001 DAS_autoWiperState "5";
BA_ "Confidence" SG_ 1001 DAS_turnIndicatorRequestReason 0;
BA_ "Confidence" SG_ 1001 DAS_forwardRadarPowerRequest 0;
BA_ "Confidence" SG_ 1001 DAS_driverDomeLightRequest 0;
BA_ "Confidence" SG_ 1001 DAS_drivePowerStateRequest 0;
BA_ "Confidence" SG_ 1001 DAS_enableIcrDataCollection 0;
BA_ "Confidence" SG_ 1001 DAS_rPillarCamHeaterDutyCycle 0;
BA_ "Confidence" SG_ 1001 DAS_adaptiveHighBeamIsFaulted 0;
BA_ "Confidence" SG_ 1001 DAS_restrictDoorReleaseLeft 0;
BA_ "Confidence" SG_ 1001 DAS_restrictDoorReleaseRight 0;
BA_ "Confidence" SG_ 1001 DAS_bodyControlsCounter 0;
BA_ "Confidence" SG_ 1001 DAS_bodyControlsChecksum 0;
BA_ "Confidence" SG_ 634 DIF_hvStatusChecksum 0;
BA_ "Confidence" SG_ 634 DIF_hvStatusCounter 0;
BA_ "Confidence" SG_ 634 DIF_hvilCurrent 0;
BA_ "Confidence" SG_ 634 DIF_hvilCmVoltage 0;
BA_ "Confidence" SG_ 634 DIF_hvilStatus 0;
BA_ "GenSigSNA" SG_ 634 DIF_hvilStatus "3";
BA_ "Confidence" SG_ 634 DIF_hvilSupplyState 0;
BA_ "Confidence" SG_ 634 DIF_activeDischargeCtrl 0;
BA_ "Confidence" SG_ 634 DIF_activeDischargeStatus 0;
BA_ "Confidence" SG_ 634 DIF_vBat 0;
BA_ "Confidence" SG_ 634 DIF_vBatQF 0;
BA_ "Confidence" SG_ 634 DIF_powerStageSafeState 0;
BA_ "Confidence" SG_ 634 DIF_fluxState 0;
BA_ "Confidence" SG_ 634 DIF_vBusDiag 0;
BA_ "Confidence" SG_ 634 DIF_gateDriveState 0;
BA_ "Confidence" SG_ 634 DIF_gateDriveSupplyState 0;
BA_ "Confidence" SG_ 784 HVP_infoIndex 1;
BA_ "Confidence" SG_ 784 HVP_buildType 0;
BA_ "Confidence" SG_ 784 HVP_buildConfigId 0;
BA_ "Confidence" SG_ 784 HVP_hardwareId 0;
BA_ "Confidence" SG_ 784 HVP_componentId 0;
BA_ "Confidence" SG_ 784 HVP_pcbaId 0;
BA_ "Confidence" SG_ 784 HVP_assemblyId 0;
BA_ "Confidence" SG_ 784 HVP_usageId 0;
BA_ "Confidence" SG_ 784 HVP_subUsageId 0;
BA_ "Confidence" SG_ 784 HVP_platformType 0;
BA_ "Confidence" SG_ 784 HVP_appCrc 0;
BA_ "Confidence" SG_ 784 HVP_appGitHash 0;
BA_ "Confidence" SG_ 784 HVP_bootGitHash 0;
BA_ "Confidence" SG_ 784 HVP_bootUdsProtoVersion 0;
BA_ "Confidence" SG_ 784 HVP_bootCrc 0;
BA_ "Confidence" SG_ 941 ICR_infoIndex 1;
BA_ "Confidence" SG_ 941 ICR_infoBuildType 0;
BA_ "Confidence" SG_ 941 ICR_infoPcbaId 0;
BA_ "Confidence" SG_ 941 ICR_infoAssemblyId 0;
BA_ "Confidence" SG_ 941 ICR_infoUsageId 0;
BA_ "Confidence" SG_ 941 ICR_infoAppCrc 0;
BA_ "Confidence" SG_ 941 ICR_infoBoardPartNumber17 0;
BA_ "Confidence" SG_ 941 ICR_infoBoardPartNumber814 0;
BA_ "Confidence" SG_ 941 ICR_infoBoardPartNumber1520 0;
BA_ "Confidence" SG_ 964 PCS_infoIndex 1;
BA_ "Confidence" SG_ 964 PCS_buildType 0;
BA_ "Confidence" SG_ 964 PCS_buildConfigId 0;
BA_ "Confidence" SG_ 964 PCS_hardwareId 0;
BA_ "Confidence" SG_ 964 PCS_componentId 0;
BA_ "Confidence" SG_ 964 PCS_pcbaId 0;
BA_ "Confidence" SG_ 964 PCS_assemblyId 0;
BA_ "Confidence" SG_ 964 PCS_usageId 0;
BA_ "Confidence" SG_ 964 PCS_subUsageId 0;
BA_ "Confidence" SG_ 964 PCS_platformType 0;
BA_ "Confidence" SG_ 964 PCS_appCrc 0;
BA_ "Confidence" SG_ 964 PCS_cpu2AppCrc 0;
BA_ "Confidence" SG_ 964 PCS_appGitHash 0;
BA_ "Confidence" SG_ 964 PCS_bootGitHash 0;
BA_ "Confidence" SG_ 964 PCS_bootUdsProtoVersion 0;
BA_ "Confidence" SG_ 964 PCS_bootCrc 0;
BA_ "Confidence" SG_ 816 SCCM_infoIndex 1;
BA_ "Confidence" SG_ 816 SCCM_infoBuildType 0;
BA_ "Confidence" SG_ 816 SCCM_infoBuildConfigId 0;
BA_ "Confidence" SG_ 816 SCCM_infoHardwareId 0;
BA_ "Confidence" SG_ 816 SCCM_infoComponentId 0;
BA_ "Confidence" SG_ 816 SCCM_infoPcbaId 0;
BA_ "Confidence" SG_ 816 SCCM_infoAssemblyId 0;
BA_ "Confidence" SG_ 816 SCCM_infoUsageId 0;
BA_ "Confidence" SG_ 816 SCCM_infoSubUsageId 0;
BA_ "Confidence" SG_ 816 SCCM_infoPlatformType 0;
BA_ "Confidence" SG_ 816 SCCM_infoBootSvnRev 0;
BA_ "Confidence" SG_ 816 SCCM_infoBootSvnUrlHash 0;
BA_ "Confidence" SG_ 816 SCCM_infoSubcomponent1Version 0;
BA_ "Confidence" SG_ 816 SCCM_infoAppSvnHash 0;
BA_ "Confidence" SG_ 816 SCCM_infoBootSvnHash 0;
BA_ "Confidence" SG_ 816 SCCM_infoUdsProtoVersion 0;
BA_ "Confidence" SG_ 816 SCCM_infoBootCrc 0;
BA_ "Confidence" SG_ 1657 UI_rgbEnableState 0;
BA_ "Confidence" SG_ 1657 UI_rgbEffectType 0;
BA_ "Confidence" SG_ 1657 UI_rgbBrightnessLevel 0;
BA_ "GenSigSNA" SG_ 1657 UI_rgbBrightnessLevel "127";
BA_ "Confidence" SG_ 1657 UI_audioVisualizerState 0;
BA_ "Confidence" SG_ 1657 UI_rgbTargetDOORFL 0;
BA_ "Confidence" SG_ 1657 UI_rgbTargetDOORFR 0;
BA_ "Confidence" SG_ 1657 UI_rgbTargetDOORRL 0;
BA_ "Confidence" SG_ 1657 UI_rgbTargetDOORRR 0;
BA_ "Confidence" SG_ 1657 UI_rgbTargetIPFL 0;
BA_ "Confidence" SG_ 1657 UI_rgbTargetIPFR 0;
BA_ "Confidence" SG_ 819 UI_openChargePortDoorRequest 0;
BA_ "Confidence" SG_ 819 UI_closeChargePortDoorRequest 0;
BA_ "Confidence" SG_ 819 UI_chargeEnableRequest 0;
BA_ "Confidence" SG_ 819 UI_acChargeCurrentLimit 0;
BA_ "GenSigSNA" SG_ 819 UI_acChargeCurrentLimit "127";
BA_ "Confidence" SG_ 819 UI_chargeTerminationPct 0;
BA_ "Confidence" SG_ 819 UI_scheduledDepartureEnabled 0;
BA_ "Confidence" SG_ 819 UI_chargePortLatchRequest 0;
BA_ "Confidence" SG_ 819 UI_cpInletHeaterRequest 0;
BA_ "Confidence" SG_ 991 UI_userActivity 0;
BA_ "Confidence" SG_ 991 UI_activeTouchPoints 0;
BA_ "Confidence" SG_ 991 UI_linkState 0;
BA_ "Confidence" SG_ 991 UI_autopilotSentryRequest 0;
BA_ "Confidence" SG_ 991 UI_mobileAppConnected 0;
BA_ "Confidence" SG_ 991 UI_phoneLeftInCabin 0;
BA_ "Confidence" SG_ 991 UI_autoshiftDRState 0;
BA_ "Confidence" SG_ 991 UI_wifiBtModuleType 0;
BA_ "Confidence" SG_ 991 UI_selfParkState 0;
BA_ "GenSigSNA" SG_ 991 UI_selfParkState "255";
BA_ "Confidence" SG_ 991 UI_summonDeviceIndex 0;
BA_ "Confidence" SG_ 991 UI_fullScreenMode 0;
BA_ "Confidence" SG_ 663 UI_adaptiveRideRequest 0;
BA_ "Confidence" SG_ 663 UI_geofenceLevelingRequest 0;
BA_ "GenSigSNA" SG_ 663 UI_geofenceLevelingRequest "5";
BA_ "Confidence" SG_ 947 UI_gloveboxRequest 0;
BA_ "Confidence" SG_ 947 UI_trunkRequest 0;
BA_ "Confidence" SG_ 947 UI_PINToDriveEnabled 0;
BA_ "Confidence" SG_ 947 UI_PINToDrivePassed 0;
BA_ "Confidence" SG_ 947 UI_disableMirrorAutoDim 0;
BA_ "Confidence" SG_ 947 UI_lightSwitch 0;
BA_ "GenSigSNA" SG_ 947 UI_lightSwitch "4";
BA_ "Confidence" SG_ 947 UI_readyToAddKey 0;
BA_ "Confidence" SG_ 947 UI_alarmTriggerRequest 0;
BA_ "Confidence" SG_ 947 UI_displayOnForUser 0;
BA_ "Confidence" SG_ 947 UI_BLEPushNotificationRequest 0;
BA_ "Confidence" SG_ 947 UI_keepAutopilotAwake 0;
BA_ "Confidence" SG_ 947 UI_batteryPreconditioningRequest 0;
BA_ "Confidence" SG_ 947 UI_autopilotPowerStateRequest 0;
BA_ "Confidence" SG_ 947 UI_autoRollWindowsOnLockEnable 0;
BA_ "Confidence" SG_ 947 UI_steeringWheelHeatReq 0;
BA_ "Confidence" SG_ 947 UI_disableHorn 0;
BA_ "Confidence" SG_ 947 UI_frontLeftSeatFanReq 0;
BA_ "Confidence" SG_ 947 UI_frontRightSeatAutoClimateReq 0;
BA_ "Confidence" SG_ 947 UI_frontRightSeatFanReq 0;
BA_ "Confidence" SG_ 947 UI_3RLeftSeatHeatReq 0;
BA_ "Confidence" SG_ 947 UI_3RRightSeatHeatReq 0;
BA_ "Confidence" SG_ 947 UI_frontLeftSeatAutoClimateReq 0;
BA_ "Confidence" SG_ 947 UI_wiperHeaterReq 0;
BA_ "Confidence" SG_ 947 UI_silentAlarm 0;
BA_ "Confidence" SG_ 1090 VCBATT_pcsInterfaceMuxIndex 1;
BA_ "Confidence" SG_ 1090 VCBATT_pcsInterfaceCounter 0;
BA_ "Confidence" SG_ 1090 VCBATT_pcsInterfaceChecksum 0;
BA_ "Confidence" SG_ 1090 VCBATT_pcsLVVoltageTarget 0;
BA_ "Confidence" SG_ 1090 VCBATT_pcsLVMinVoltageLimit 0;
BA_ "Confidence" SG_ 1090 VCBATT_pcsLVMaxVoltageLimit 0;
BA_ "Confidence" SG_ 1090 VCBATT_goodForPCSPowerCycle 0;
BA_ "Confidence" SG_ 1090 VCBATT_LVBatteryCannotSupportVeh 0;
BA_ "SystemSignalLongSymbol" SG_ 1090 VCBATT_LVBatteryCannotSupportVeh "VCBATT_LVBatteryCannotSupportVehicle";
BA_ "Confidence" SG_ 1090 VCBATT_pcsResistanceFiltered 0;
BA_ "GenSigSNA" SG_ 1090 VCBATT_pcsResistanceFiltered "65535";
BA_ "Confidence" SG_ 1090 VCBATT_pcsLVMaxDchrgCurrentLimit 0;
BA_ "Confidence" SG_ 1090 VCBATT_defaultPcsLVVoltageTarget 0;
BA_ "Confidence" SG_ 1090 VCBATT_lvHwProtSelfTestActive 0;
BA_ "Confidence" SG_ 1090 VCBATT_lvBatteryDischargeRequest 0;
BA_ "Confidence" SG_ 1027 VCFRONT1_eFuseDebugStatusIndex 1;
BA_ "Confidence" SG_ 1027 VCFRONT1_EPAS2EFuseState 0;
BA_ "Confidence" SG_ 1027 VCFRONT1_EPAS2EFuseCurrent 0;
BA_ "Confidence" SG_ 1027 VCFRONT1_EPAS2EFuseOutput 0;
BA_ "Confidence" SG_ 1027 VCFRONT1_EPAS2EFuseOutputDesired 0;
BA_ "Confidence" SG_ 1027 VCFRONT1_EPAS2EFuseBypass 0;
BA_ "Confidence" SG_ 1027 VCFRONT1_EPAS2EFuseBypassDesired 0;
BA_ "Confidence" SG_ 1027 VCFRONT1_EPAS2EFuseVoltage 0;
BA_ "Confidence" SG_ 1027 VCFRONT1_EPAS2EFuseTemperature 0;
BA_ "Confidence" SG_ 1027 VCFRONT1_EPAS2EFuseManagerState 0;
BA_ "Confidence" SG_ 1027 VCFRONT1_EPAS2EFuseHardShortThre 0;
BA_ "SystemSignalLongSymbol" SG_ 1027 VCFRONT1_EPAS2EFuseHardShortThre "VCFRONT1_EPAS2EFuseHardShortThreshold";
BA_ "Confidence" SG_ 1027 VCFRONT1_EPAS2EFuseOCThreshold 0;
BA_ "Confidence" SG_ 1027 VCFRONT1_EPAS2EFuseType 0;
BA_ "Confidence" SG_ 1027 VCFRONT1_rightControllerEFuseSta 0;
BA_ "SystemSignalLongSymbol" SG_ 1027 VCFRONT1_rightControllerEFuseSta "VCFRONT1_rightControllerEFuseState";
BA_ "Confidence" SG_ 1027 VCFRONT1_rightControllerEFuseCur 0;
BA_ "SystemSignalLongSymbol" SG_ 1027 VCFRONT1_rightControllerEFuseCur "VCFRONT1_rightControllerEFuseCurrent";
BA_ "Confidence" SG_ 1027 VCFRONT1_rightControllerEFuseOut 0;
BA_ "SystemSignalLongSymbol" SG_ 1027 VCFRONT1_rightControllerEFuseOut "VCFRONT1_rightControllerEFuseOutput";
BA_ "Confidence" SG_ 1027 VCFRONT1_rightControllerEFu_0002 0;
BA_ "SystemSignalLongSymbol" SG_ 1027 VCFRONT1_rightControllerEFu_0002 "VCFRONT1_rightControllerEFuseOutputDesired";
BA_ "Confidence" SG_ 1027 VCFRONT1_rightControllerEFuseByp 0;
BA_ "SystemSignalLongSymbol" SG_ 1027 VCFRONT1_rightControllerEFuseByp "VCFRONT1_rightControllerEFuseBypass";
BA_ "Confidence" SG_ 1027 VCFRONT1_rightControllerEFu_0001 0;
BA_ "SystemSignalLongSymbol" SG_ 1027 VCFRONT1_rightControllerEFu_0001 "VCFRONT1_rightControllerEFuseBypassDesired";
BA_ "Confidence" SG_ 1027 VCFRONT1_rightControllerEFuseVol 0;
BA_ "SystemSignalLongSymbol" SG_ 1027 VCFRONT1_rightControllerEFuseVol "VCFRONT1_rightControllerEFuseVoltage";
BA_ "Confidence" SG_ 1027 VCFRONT1_rightControllerEFuseTem 0;
BA_ "SystemSignalLongSymbol" SG_ 1027 VCFRONT1_rightControllerEFuseTem "VCFRONT1_rightControllerEFuseTemperature";
BA_ "Confidence" SG_ 1027 VCFRONT1_rightControllerEFuseMan 0;
BA_ "SystemSignalLongSymbol" SG_ 1027 VCFRONT1_rightControllerEFuseMan "VCFRONT1_rightControllerEFuseManagerState";
BA_ "Confidence" SG_ 1027 VCFRONT1_rightControllerEFuseHar 0;
BA_ "SystemSignalLongSymbol" SG_ 1027 VCFRONT1_rightControllerEFuseHar "VCFRONT1_rightControllerEFuseHardShortThreshold";
BA_ "Confidence" SG_ 1027 VCFRONT1_rightControllerEFuseOCT 0;
BA_ "SystemSignalLongSymbol" SG_ 1027 VCFRONT1_rightControllerEFuseOCT "VCFRONT1_rightControllerEFuseOCThreshold";
BA_ "Confidence" SG_ 1027 VCFRONT1_rightControllerEFuseTyp 0;
BA_ "SystemSignalLongSymbol" SG_ 1027 VCFRONT1_rightControllerEFuseTyp "VCFRONT1_rightControllerEFuseType";
BA_ "Confidence" SG_ 1027 VCFRONT1_autopilot2EFuseState 0;
BA_ "Confidence" SG_ 1027 VCFRONT1_autopilot2EFuseCurrent 0;
BA_ "Confidence" SG_ 1027 VCFRONT1_autopilot2EFuseOutput 0;
BA_ "Confidence" SG_ 1027 VCFRONT1_autopilot2EFuseOutputDe 0;
BA_ "SystemSignalLongSymbol" SG_ 1027 VCFRONT1_autopilot2EFuseOutputDe "VCFRONT1_autopilot2EFuseOutputDesired";
BA_ "Confidence" SG_ 1027 VCFRONT1_autopilot2EFuseBypass 0;
BA_ "Confidence" SG_ 1027 VCFRONT1_autopilot2EFuseBypassDe 0;
BA_ "SystemSignalLongSymbol" SG_ 1027 VCFRONT1_autopilot2EFuseBypassDe "VCFRONT1_autopilot2EFuseBypassDesired";
BA_ "Confidence" SG_ 1027 VCFRONT1_autopilot2EFuseVoltage 0;
BA_ "Confidence" SG_ 1027 VCFRONT1_autopilot2EFuseTemperat 0;
BA_ "SystemSignalLongSymbol" SG_ 1027 VCFRONT1_autopilot2EFuseTemperat "VCFRONT1_autopilot2EFuseTemperature";
BA_ "Confidence" SG_ 1027 VCFRONT1_autopilot2EFuseManagerS 0;
BA_ "SystemSignalLongSymbol" SG_ 1027 VCFRONT1_autopilot2EFuseManagerS "VCFRONT1_autopilot2EFuseManagerState";
BA_ "Confidence" SG_ 1027 VCFRONT1_autopilot2EFuseHardShor 0;
BA_ "SystemSignalLongSymbol" SG_ 1027 VCFRONT1_autopilot2EFuseHardShor "VCFRONT1_autopilot2EFuseHardShortThreshold";
BA_ "Confidence" SG_ 1027 VCFRONT1_autopilot2EFuseOCThresh 0;
BA_ "SystemSignalLongSymbol" SG_ 1027 VCFRONT1_autopilot2EFuseOCThresh "VCFRONT1_autopilot2EFuseOCThreshold";
BA_ "Confidence" SG_ 1027 VCFRONT1_autopilot2EFuseType 0;
BA_ "Confidence" SG_ 609 VCFRONT_12VBatteryStatusIndex 1;
BA_ "Confidence" SG_ 609 VCFRONT_good12VforUpdate 0;
BA_ "Confidence" SG_ 609 VCFRONT_LVLoadRequest 0;
BA_ "Confidence" SG_ 609 VCFRONT_12VBatteryStatusCounter 0;
BA_ "Confidence" SG_ 609 VCFRONT_12VBatteryStatusChecksum 0;
BA_ "Confidence" SG_ 609 VCFRONT_batterySupportRequest 0;
BA_ "Confidence" SG_ 609 VCFRONT_batterySMState 0;
BA_ "Confidence" SG_ 609 VCFRONT_eFuseRecoveryStateDBG 0;
BA_ "Confidence" SG_ 609 VCFRONT_batteryLINScheduleDBG 0;
BA_ "GenSigSNA" SG_ 609 VCFRONT_batteryLINScheduleDBG "7";
BA_ "Confidence" SG_ 609 VCFRONT_resistanceEstimationTest 0;
BA_ "SystemSignalLongSymbol" SG_ 609 VCFRONT_resistanceEstimationTest "VCFRONT_resistanceEstimationTestCounter";
BA_ "Confidence" SG_ 609 VCFRONT_IBSCurrent 0;
BA_ "Confidence" SG_ 609 VCFRONT_IBSVoltage 0;
BA_ "GenSigSNA" SG_ 609 VCFRONT_IBSVoltage "4095";
BA_ "Confidence" SG_ 609 VCFRONT_reverseBatteryFault 0;
BA_ "Confidence" SG_ 609 VCFRONT_LVBatterySupported 0;
BA_ "Confidence" SG_ 609 VCFRONT_LVBatteryCannotSupportVe 0;
BA_ "SystemSignalLongSymbol" SG_ 609 VCFRONT_LVBatteryCannotSupportVe "VCFRONT_LVBatteryCannotSupportVehicle";
BA_ "Confidence" SG_ 609 VCFRONT_goodTemp12VforUpdate 0;
BA_ "Confidence" SG_ 609 VCFRONT_12VBatteryTargetVoltage 0;
BA_ "Confidence" SG_ 609 VCFRONT_IBSTemperature 0;
BA_ "GenSigSNA" SG_ 609 VCFRONT_IBSTemperature "2047";
BA_ "Confidence" SG_ 609 VCFRONT_currentSensorMismatchLea 0;
BA_ "SystemSignalLongSymbol" SG_ 609 VCFRONT_currentSensorMismatchLea "VCFRONT_currentSensorMismatchLeakyBktPctDBG";
BA_ "Confidence" SG_ 609 VCFRONT_LVBatteryEnergyRemaining 0;
BA_ "SystemSignalLongSymbol" SG_ 609 VCFRONT_LVBatteryEnergyRemaining "VCFRONT_LVBatteryEnergyRemainingPCT";
BA_ "Confidence" SG_ 609 VCFRONT_LVBatteryStatusForDrive 0;
BA_ "Confidence" SG_ 609 VCFRONT_LVBatteryType 0;
BA_ "Confidence" SG_ 609 VCFRONT_resistanceEstimationNeed 0;
BA_ "SystemSignalLongSymbol" SG_ 609 VCFRONT_resistanceEstimationNeed "VCFRONT_resistanceEstimationNeeded";
BA_ "Confidence" SG_ 609 VCFRONT_IBSVoltageFiltered 0;
BA_ "GenSigSNA" SG_ 609 VCFRONT_IBSVoltageFiltered "16383";
BA_ "Confidence" SG_ 609 VCFRONT_LVBMS_LVBusVoltageSource 0;
BA_ "SystemSignalLongSymbol" SG_ 609 VCFRONT_LVBMS_LVBusVoltageSource "VCFRONT_LVBMS_LVBusVoltageSourceDBG";
BA_ "Confidence" SG_ 609 VCFRONT_LVBMS_LVPackCurrentSourc 0;
BA_ "SystemSignalLongSymbol" SG_ 609 VCFRONT_LVBMS_LVPackCurrentSourc "VCFRONT_LVBMS_LVPackCurrentSourceDBG";
BA_ "Confidence" SG_ 609 VCFRONT_LVBatterySupportRqrdTrig 0;
BA_ "SystemSignalLongSymbol" SG_ 609 VCFRONT_LVBatterySupportRqrdTrig "VCFRONT_LVBatterySupportRqrdTrigger";
BA_ "Confidence" SG_ 609 VCFRONT_goodForPCSPowerCycleLeak 0;
BA_ "SystemSignalLongSymbol" SG_ 609 VCFRONT_goodForPCSPowerCycleLeak "VCFRONT_goodForPCSPowerCycleLeakyBktDBG";
BA_ "Confidence" SG_ 609 VCFRONT_LVBusControlsFutile 0;
BA_ "Confidence" SG_ 609 VCFRONT_resistanceEstimatio_0001 0;
BA_ "SystemSignalLongSymbol" SG_ 609 VCFRONT_resistanceEstimatio_0001 "VCFRONT_resistanceEstimationTestValid";
BA_ "Confidence" SG_ 609 VCFRONT_resistanceEstimatio_0002 0;
BA_ "SystemSignalLongSymbol" SG_ 609 VCFRONT_resistanceEstimatio_0002 "VCFRONT_resistanceEstimationTestsExpended";
BA_ "Confidence" SG_ 609 VCFRONT_goodLVChargeForUpdate 0;
BA_ "Confidence" SG_ 609 VCFRONT_opportunisticDCRTestNeed 0;
BA_ "SystemSignalLongSymbol" SG_ 609 VCFRONT_opportunisticDCRTestNeed "VCFRONT_opportunisticDCRTestNeeded";
BA_ "Confidence" SG_ 609 VCFRONT_voltageProfile 0;
BA_ "Confidence" SG_ 609 VCFRONT_IBSAmpHours 0;
BA_ "Confidence" SG_ 609 VCFRONT_IBSVoltageRawDBG 0;
BA_ "GenSigSNA" SG_ 609 VCFRONT_IBSVoltageRawDBG "16383";
BA_ "Confidence" SG_ 609 VCFRONT_LVBatteryLINCommsDetecte 0;
BA_ "SystemSignalLongSymbol" SG_ 609 VCFRONT_LVBatteryLINCommsDetecte "VCFRONT_LVBatteryLINCommsDetectedDBG";
BA_ "Confidence" SG_ 609 VCFRONT_voltageSensorMismatchLea 0;
BA_ "SystemSignalLongSymbol" SG_ 609 VCFRONT_voltageSensorMismatchLea "VCFRONT_voltageSensorMismatchLeakyBktPctDBG";
BA_ "Confidence" SG_ 609 VCFRONT_LVBusControlMode 0;
BA_ "Confidence" SG_ 609 VCFRONT_resistanceEstimationExte 0;
BA_ "SystemSignalLongSymbol" SG_ 609 VCFRONT_resistanceEstimationExte "VCFRONT_resistanceEstimationExtendedTestEnabled";
BA_ "Confidence" SG_ 609 VCFRONT_LVBatteryFctryLimOverrid 0;
BA_ "SystemSignalLongSymbol" SG_ 609 VCFRONT_LVBatteryFctryLimOverrid "VCFRONT_LVBatteryFctryLimOverrideOk";
BA_ "Confidence" SG_ 609 VCFRONT_LVBatterySPICommsDetecte 0;
BA_ "SystemSignalLongSymbol" SG_ 609 VCFRONT_LVBatterySPICommsDetecte "VCFRONT_LVBatterySPICommsDetectedDBG";
BA_ "Confidence" SG_ 609 VCFRONT_targetCurrent 0;
BA_ "Confidence" SG_ 609 VCFRONT_PCSMia 0;
BA_ "Confidence" SG_ 609 VCFRONT_chargeNeeded 0;
BA_ "Confidence" SG_ 609 VCFRONT_voltageControlLoopIntegr 0;
BA_ "SystemSignalLongSymbol" SG_ 609 VCFRONT_voltageControlLoopIntegr "VCFRONT_voltageControlLoopIntegrationVal";
BA_ "Confidence" SG_ 609 VCFRONT_currentControlLoopIntegr 0;
BA_ "SystemSignalLongSymbol" SG_ 609 VCFRONT_currentControlLoopIntegr "VCFRONT_currentControlLoopIntegrationVal";
VAL_ 1025 BMS_brickVoltageMultiplexer 35 "Mux35" 34 "Mux34" 33 "Mux33" 32 "Mux32" 31 "Mux31" 30 "Mux30" 29 "Mux29" 28 "Mux28" 27 "Mux27" 26 "Mux26" 25 "Mux25" 24 "Mux24" 23 "Mux23" 22 "Mux22" 21 "Mux21" 20 "Mux20" 19 "Mux19" 18 "Mux18" 17 "Mux17" 16 "Mux16" 15 "Mux15" 14 "Mux14" 13 "Mux13" 12 "Mux12" 11 "Mux11" 10 "Mux10" 9 "Mux9" 8 "Mux8" 7 "Mux7" 6 "Mux6" 5 "Mux5" 4 "Mux4" 3 "Mux3" 2 "Mux2" 1 "Mux1" 0 "Mux0" ;
VAL_ 1025 BMS_brickVoltageStatus1 3 "SENSOR_BYPASSED" 2 "SENSOR_NOMINAL" 1 "SENSOR_BAD" 0 "SENSOR_MISSING" ;
VAL_ 1025 BMS_brickVoltageStatus2 3 "SENSOR_BYPASSED" 2 "SENSOR_NOMINAL" 1 "SENSOR_BAD" 0 "SENSOR_MISSING" ;
VAL_ 1025 BMS_brickVoltageStatus3 3 "SENSOR_BYPASSED" 2 "SENSOR_NOMINAL" 1 "SENSOR_BAD" 0 "SENSOR_MISSING" ;
VAL_ 1025 BMS_brickVoltageStatus4 3 "SENSOR_BYPASSED" 2 "SENSOR_NOMINAL" 1 "SENSOR_BAD" 0 "SENSOR_MISSING" ;
VAL_ 1025 BMS_brickVoltageStatus5 3 "SENSOR_BYPASSED" 2 "SENSOR_NOMINAL" 1 "SENSOR_BAD" 0 "SENSOR_MISSING" ;
VAL_ 1025 BMS_brickVoltageStatus6 3 "SENSOR_BYPASSED" 2 "SENSOR_NOMINAL" 1 "SENSOR_BAD" 0 "SENSOR_MISSING" ;
VAL_ 1025 BMS_brickVoltageStatus7 3 "SENSOR_BYPASSED" 2 "SENSOR_NOMINAL" 1 "SENSOR_BAD" 0 "SENSOR_MISSING" ;
VAL_ 1025 BMS_brickVoltageStatus8 3 "SENSOR_BYPASSED" 2 "SENSOR_NOMINAL" 1 "SENSOR_BAD" 0 "SENSOR_MISSING" ;
VAL_ 1025 BMS_brickVoltageStatus9 3 "SENSOR_BYPASSED" 2 "SENSOR_NOMINAL" 1 "SENSOR_BAD" 0 "SENSOR_MISSING" ;
VAL_ 1025 BMS_brickVoltageStatus10 3 "SENSOR_BYPASSED" 2 "SENSOR_NOMINAL" 1 "SENSOR_BAD" 0 "SENSOR_MISSING" ;
VAL_ 1025 BMS_brickVoltageStatus11 3 "SENSOR_BYPASSED" 2 "SENSOR_NOMINAL" 1 "SENSOR_BAD" 0 "SENSOR_MISSING" ;
VAL_ 1025 BMS_brickVoltageStatus12 3 "SENSOR_BYPASSED" 2 "SENSOR_NOMINAL" 1 "SENSOR_BAD" 0 "SENSOR_MISSING" ;
VAL_ 1025 BMS_brickVoltageStatus13 3 "SENSOR_BYPASSED" 2 "SENSOR_NOMINAL" 1 "SENSOR_BAD" 0 "SENSOR_MISSING" ;
VAL_ 1025 BMS_brickVoltageStatus14 3 "SENSOR_BYPASSED" 2 "SENSOR_NOMINAL" 1 "SENSOR_BAD" 0 "SENSOR_MISSING" ;
VAL_ 1025 BMS_brickVoltageStatus15 3 "SENSOR_BYPASSED" 2 "SENSOR_NOMINAL" 1 "SENSOR_BAD" 0 "SENSOR_MISSING" ;
VAL_ 1025 BMS_brickVoltageStatus16 3 "SENSOR_BYPASSED" 2 "SENSOR_NOMINAL" 1 "SENSOR_BAD" 0 "SENSOR_MISSING" ;
VAL_ 1025 BMS_brickVoltageStatus17 3 "SENSOR_BYPASSED" 2 "SENSOR_NOMINAL" 1 "SENSOR_BAD" 0 "SENSOR_MISSING" ;
VAL_ 1025 BMS_brickVoltageStatus18 3 "SENSOR_BYPASSED" 2 "SENSOR_NOMINAL" 1 "SENSOR_BAD" 0 "SENSOR_MISSING" ;
VAL_ 1025 BMS_brickVoltageStatus19 3 "SENSOR_BYPASSED" 2 "SENSOR_NOMINAL" 1 "SENSOR_BAD" 0 "SENSOR_MISSING" ;
VAL_ 1025 BMS_brickVoltageStatus20 3 "SENSOR_BYPASSED" 2 "SENSOR_NOMINAL" 1 "SENSOR_BAD" 0 "SENSOR_MISSING" ;
VAL_ 1025 BMS_brickVoltageStatus21 3 "SENSOR_BYPASSED" 2 "SENSOR_NOMINAL" 1 "SENSOR_BAD" 0 "SENSOR_MISSING" ;
VAL_ 1025 BMS_brickVoltageStatus22 3 "SENSOR_BYPASSED" 2 "SENSOR_NOMINAL" 1 "SENSOR_BAD" 0 "SENSOR_MISSING" ;
VAL_ 1025 BMS_brickVoltageStatus23 3 "SENSOR_BYPASSED" 2 "SENSOR_NOMINAL" 1 "SENSOR_BAD" 0 "SENSOR_MISSING" ;
VAL_ 1025 BMS_brickVoltageStatus24 3 "SENSOR_BYPASSED" 2 "SENSOR_NOMINAL" 1 "SENSOR_BAD" 0 "SENSOR_MISSING" ;
VAL_ 1025 BMS_brickVoltageStatus25 3 "SENSOR_BYPASSED" 2 "SENSOR_NOMINAL" 1 "SENSOR_BAD" 0 "SENSOR_MISSING" ;
VAL_ 1025 BMS_brickVoltageStatus26 3 "SENSOR_BYPASSED" 2 "SENSOR_NOMINAL" 1 "SENSOR_BAD" 0 "SENSOR_MISSING" ;
VAL_ 1025 BMS_brickVoltageStatus27 3 "SENSOR_BYPASSED" 2 "SENSOR_NOMINAL" 1 "SENSOR_BAD" 0 "SENSOR_MISSING" ;
VAL_ 1025 BMS_brickVoltageStatus28 3 "SENSOR_BYPASSED" 2 "SENSOR_NOMINAL" 1 "SENSOR_BAD" 0 "SENSOR_MISSING" ;
VAL_ 1025 BMS_brickVoltageStatus29 3 "SENSOR_BYPASSED" 2 "SENSOR_NOMINAL" 1 "SENSOR_BAD" 0 "SENSOR_MISSING" ;
VAL_ 1025 BMS_brickVoltageStatus30 3 "SENSOR_BYPASSED" 2 "SENSOR_NOMINAL" 1 "SENSOR_BAD" 0 "SENSOR_MISSING" ;
VAL_ 1025 BMS_brickVoltageStatus31 3 "SENSOR_BYPASSED" 2 "SENSOR_NOMINAL" 1 "SENSOR_BAD" 0 "SENSOR_MISSING" ;
VAL_ 1025 BMS_brickVoltageStatus32 3 "SENSOR_BYPASSED" 2 "SENSOR_NOMINAL" 1 "SENSOR_BAD" 0 "SENSOR_MISSING" ;
VAL_ 1025 BMS_brickVoltageStatus33 3 "SENSOR_BYPASSED" 2 "SENSOR_NOMINAL" 1 "SENSOR_BAD" 0 "SENSOR_MISSING" ;
VAL_ 1025 BMS_brickVoltageStatus34 3 "SENSOR_BYPASSED" 2 "SENSOR_NOMINAL" 1 "SENSOR_BAD" 0 "SENSOR_MISSING" ;
VAL_ 1025 BMS_brickVoltageStatus35 3 "SENSOR_BYPASSED" 2 "SENSOR_NOMINAL" 1 "SENSOR_BAD" 0 "SENSOR_MISSING" ;
VAL_ 1025 BMS_brickVoltageStatus36 3 "SENSOR_BYPASSED" 2 "SENSOR_NOMINAL" 1 "SENSOR_BAD" 0 "SENSOR_MISSING" ;
VAL_ 1025 BMS_brickVoltageStatus37 3 "SENSOR_BYPASSED" 2 "SENSOR_NOMINAL" 1 "SENSOR_BAD" 0 "SENSOR_MISSING" ;
VAL_ 1025 BMS_brickVoltageStatus38 3 "SENSOR_BYPASSED" 2 "SENSOR_NOMINAL" 1 "SENSOR_BAD" 0 "SENSOR_MISSING" ;
VAL_ 1025 BMS_brickVoltageStatus39 3 "SENSOR_BYPASSED" 2 "SENSOR_NOMINAL" 1 "SENSOR_BAD" 0 "SENSOR_MISSING" ;
VAL_ 1025 BMS_brickVoltageStatus40 3 "SENSOR_BYPASSED" 2 "SENSOR_NOMINAL" 1 "SENSOR_BAD" 0 "SENSOR_MISSING" ;
VAL_ 1025 BMS_brickVoltageStatus41 3 "SENSOR_BYPASSED" 2 "SENSOR_NOMINAL" 1 "SENSOR_BAD" 0 "SENSOR_MISSING" ;
VAL_ 1025 BMS_brickVoltageStatus42 3 "SENSOR_BYPASSED" 2 "SENSOR_NOMINAL" 1 "SENSOR_BAD" 0 "SENSOR_MISSING" ;
VAL_ 1025 BMS_brickVoltageStatus43 3 "SENSOR_BYPASSED" 2 "SENSOR_NOMINAL" 1 "SENSOR_BAD" 0 "SENSOR_MISSING" ;
VAL_ 1025 BMS_brickVoltageStatus44 3 "SENSOR_BYPASSED" 2 "SENSOR_NOMINAL" 1 "SENSOR_BAD" 0 "SENSOR_MISSING" ;
VAL_ 1025 BMS_brickVoltageStatus45 3 "SENSOR_BYPASSED" 2 "SENSOR_NOMINAL" 1 "SENSOR_BAD" 0 "SENSOR_MISSING" ;
VAL_ 1025 BMS_brickVoltageStatus46 3 "SENSOR_BYPASSED" 2 "SENSOR_NOMINAL" 1 "SENSOR_BAD" 0 "SENSOR_MISSING" ;
VAL_ 1025 BMS_brickVoltageStatus47 3 "SENSOR_BYPASSED" 2 "SENSOR_NOMINAL" 1 "SENSOR_BAD" 0 "SENSOR_MISSING" ;
VAL_ 1025 BMS_brickVoltageStatus48 3 "SENSOR_BYPASSED" 2 "SENSOR_NOMINAL" 1 "SENSOR_BAD" 0 "SENSOR_MISSING" ;
VAL_ 1025 BMS_brickVoltageStatus49 3 "SENSOR_BYPASSED" 2 "SENSOR_NOMINAL" 1 "SENSOR_BAD" 0 "SENSOR_MISSING" ;
VAL_ 1025 BMS_brickVoltageStatus50 3 "SENSOR_BYPASSED" 2 "SENSOR_NOMINAL" 1 "SENSOR_BAD" 0 "SENSOR_MISSING" ;
VAL_ 1025 BMS_brickVoltageStatus51 3 "SENSOR_BYPASSED" 2 "SENSOR_NOMINAL" 1 "SENSOR_BAD" 0 "SENSOR_MISSING" ;
VAL_ 1025 BMS_brickVoltageStatus52 3 "SENSOR_BYPASSED" 2 "SENSOR_NOMINAL" 1 "SENSOR_BAD" 0 "SENSOR_MISSING" ;
VAL_ 1025 BMS_brickVoltageStatus53 3 "SENSOR_BYPASSED" 2 "SENSOR_NOMINAL" 1 "SENSOR_BAD" 0 "SENSOR_MISSING" ;
VAL_ 1025 BMS_brickVoltageStatus54 3 "SENSOR_BYPASSED" 2 "SENSOR_NOMINAL" 1 "SENSOR_BAD" 0 "SENSOR_MISSING" ;
VAL_ 1025 BMS_brickVoltageStatus55 3 "SENSOR_BYPASSED" 2 "SENSOR_NOMINAL" 1 "SENSOR_BAD" 0 "SENSOR_MISSING" ;
VAL_ 1025 BMS_brickVoltageStatus56 3 "SENSOR_BYPASSED" 2 "SENSOR_NOMINAL" 1 "SENSOR_BAD" 0 "SENSOR_MISSING" ;
VAL_ 1025 BMS_brickVoltageStatus57 3 "SENSOR_BYPASSED" 2 "SENSOR_NOMINAL" 1 "SENSOR_BAD" 0 "SENSOR_MISSING" ;
VAL_ 1025 BMS_brickVoltageStatus58 3 "SENSOR_BYPASSED" 2 "SENSOR_NOMINAL" 1 "SENSOR_BAD" 0 "SENSOR_MISSING" ;
VAL_ 1025 BMS_brickVoltageStatus59 3 "SENSOR_BYPASSED" 2 "SENSOR_NOMINAL" 1 "SENSOR_BAD" 0 "SENSOR_MISSING" ;
VAL_ 1025 BMS_brickVoltageStatus60 3 "SENSOR_BYPASSED" 2 "SENSOR_NOMINAL" 1 "SENSOR_BAD" 0 "SENSOR_MISSING" ;
VAL_ 1025 BMS_brickVoltageStatus61 3 "SENSOR_BYPASSED" 2 "SENSOR_NOMINAL" 1 "SENSOR_BAD" 0 "SENSOR_MISSING" ;
VAL_ 1025 BMS_brickVoltageStatus62 3 "SENSOR_BYPASSED" 2 "SENSOR_NOMINAL" 1 "SENSOR_BAD" 0 "SENSOR_MISSING" ;
VAL_ 1025 BMS_brickVoltageStatus63 3 "SENSOR_BYPASSED" 2 "SENSOR_NOMINAL" 1 "SENSOR_BAD" 0 "SENSOR_MISSING" ;
VAL_ 1025 BMS_brickVoltageStatus64 3 "SENSOR_BYPASSED" 2 "SENSOR_NOMINAL" 1 "SENSOR_BAD" 0 "SENSOR_MISSING" ;
VAL_ 1025 BMS_brickVoltageStatus65 3 "SENSOR_BYPASSED" 2 "SENSOR_NOMINAL" 1 "SENSOR_BAD" 0 "SENSOR_MISSING" ;
VAL_ 1025 BMS_brickVoltageStatus66 3 "SENSOR_BYPASSED" 2 "SENSOR_NOMINAL" 1 "SENSOR_BAD" 0 "SENSOR_MISSING" ;
VAL_ 1025 BMS_brickVoltageStatus67 3 "SENSOR_BYPASSED" 2 "SENSOR_NOMINAL" 1 "SENSOR_BAD" 0 "SENSOR_MISSING" ;
VAL_ 1025 BMS_brickVoltageStatus68 3 "SENSOR_BYPASSED" 2 "SENSOR_NOMINAL" 1 "SENSOR_BAD" 0 "SENSOR_MISSING" ;
VAL_ 1025 BMS_brickVoltageStatus69 3 "SENSOR_BYPASSED" 2 "SENSOR_NOMINAL" 1 "SENSOR_BAD" 0 "SENSOR_MISSING" ;
VAL_ 1025 BMS_brickVoltageStatus70 3 "SENSOR_BYPASSED" 2 "SENSOR_NOMINAL" 1 "SENSOR_BAD" 0 "SENSOR_MISSING" ;
VAL_ 1025 BMS_brickVoltageStatus71 3 "SENSOR_BYPASSED" 2 "SENSOR_NOMINAL" 1 "SENSOR_BAD" 0 "SENSOR_MISSING" ;
VAL_ 1025 BMS_brickVoltageStatus72 3 "SENSOR_BYPASSED" 2 "SENSOR_NOMINAL" 1 "SENSOR_BAD" 0 "SENSOR_MISSING" ;
VAL_ 1025 BMS_brickVoltageStatus73 3 "SENSOR_BYPASSED" 2 "SENSOR_NOMINAL" 1 "SENSOR_BAD" 0 "SENSOR_MISSING" ;
VAL_ 1025 BMS_brickVoltageStatus74 3 "SENSOR_BYPASSED" 2 "SENSOR_NOMINAL" 1 "SENSOR_BAD" 0 "SENSOR_MISSING" ;
VAL_ 1025 BMS_brickVoltageStatus75 3 "SENSOR_BYPASSED" 2 "SENSOR_NOMINAL" 1 "SENSOR_BAD" 0 "SENSOR_MISSING" ;
VAL_ 1025 BMS_brickVoltageStatus76 3 "SENSOR_BYPASSED" 2 "SENSOR_NOMINAL" 1 "SENSOR_BAD" 0 "SENSOR_MISSING" ;
VAL_ 1025 BMS_brickVoltageStatus77 3 "SENSOR_BYPASSED" 2 "SENSOR_NOMINAL" 1 "SENSOR_BAD" 0 "SENSOR_MISSING" ;
VAL_ 1025 BMS_brickVoltageStatus78 3 "SENSOR_BYPASSED" 2 "SENSOR_NOMINAL" 1 "SENSOR_BAD" 0 "SENSOR_MISSING" ;
VAL_ 1025 BMS_brickVoltageStatus79 3 "SENSOR_BYPASSED" 2 "SENSOR_NOMINAL" 1 "SENSOR_BAD" 0 "SENSOR_MISSING" ;
VAL_ 1025 BMS_brickVoltageStatus80 3 "SENSOR_BYPASSED" 2 "SENSOR_NOMINAL" 1 "SENSOR_BAD" 0 "SENSOR_MISSING" ;
VAL_ 1025 BMS_brickVoltageStatus81 3 "SENSOR_BYPASSED" 2 "SENSOR_NOMINAL" 1 "SENSOR_BAD" 0 "SENSOR_MISSING" ;
VAL_ 1025 BMS_brickVoltageStatus82 3 "SENSOR_BYPASSED" 2 "SENSOR_NOMINAL" 1 "SENSOR_BAD" 0 "SENSOR_MISSING" ;
VAL_ 1025 BMS_brickVoltageStatus83 3 "SENSOR_BYPASSED" 2 "SENSOR_NOMINAL" 1 "SENSOR_BAD" 0 "SENSOR_MISSING" ;
VAL_ 1025 BMS_brickVoltageStatus84 3 "SENSOR_BYPASSED" 2 "SENSOR_NOMINAL" 1 "SENSOR_BAD" 0 "SENSOR_MISSING" ;
VAL_ 1025 BMS_brickVoltageStatus85 3 "SENSOR_BYPASSED" 2 "SENSOR_NOMINAL" 1 "SENSOR_BAD" 0 "SENSOR_MISSING" ;
VAL_ 1025 BMS_brickVoltageStatus86 3 "SENSOR_BYPASSED" 2 "SENSOR_NOMINAL" 1 "SENSOR_BAD" 0 "SENSOR_MISSING" ;
VAL_ 1025 BMS_brickVoltageStatus87 3 "SENSOR_BYPASSED" 2 "SENSOR_NOMINAL" 1 "SENSOR_BAD" 0 "SENSOR_MISSING" ;
VAL_ 1025 BMS_brickVoltageStatus88 3 "SENSOR_BYPASSED" 2 "SENSOR_NOMINAL" 1 "SENSOR_BAD" 0 "SENSOR_MISSING" ;
VAL_ 1025 BMS_brickVoltageStatus89 3 "SENSOR_BYPASSED" 2 "SENSOR_NOMINAL" 1 "SENSOR_BAD" 0 "SENSOR_MISSING" ;
VAL_ 1025 BMS_brickVoltageStatus90 3 "SENSOR_BYPASSED" 2 "SENSOR_NOMINAL" 1 "SENSOR_BAD" 0 "SENSOR_MISSING" ;
VAL_ 1025 BMS_brickVoltageStatus91 3 "SENSOR_BYPASSED" 2 "SENSOR_NOMINAL" 1 "SENSOR_BAD" 0 "SENSOR_MISSING" ;
VAL_ 1025 BMS_brickVoltageStatus92 3 "SENSOR_BYPASSED" 2 "SENSOR_NOMINAL" 1 "SENSOR_BAD" 0 "SENSOR_MISSING" ;
VAL_ 1025 BMS_brickVoltageStatus93 3 "SENSOR_BYPASSED" 2 "SENSOR_NOMINAL" 1 "SENSOR_BAD" 0 "SENSOR_MISSING" ;
VAL_ 1025 BMS_brickVoltageStatus94 3 "SENSOR_BYPASSED" 2 "SENSOR_NOMINAL" 1 "SENSOR_BAD" 0 "SENSOR_MISSING" ;
VAL_ 1025 BMS_brickVoltageStatus95 3 "SENSOR_BYPASSED" 2 "SENSOR_NOMINAL" 1 "SENSOR_BAD" 0 "SENSOR_MISSING" ;
VAL_ 1025 BMS_brickVoltageStatus96 3 "SENSOR_BYPASSED" 2 "SENSOR_NOMINAL" 1 "SENSOR_BAD" 0 "SENSOR_MISSING" ;
VAL_ 1025 BMS_brickVoltageStatus97 3 "SENSOR_BYPASSED" 2 "SENSOR_NOMINAL" 1 "SENSOR_BAD" 0 "SENSOR_MISSING" ;
VAL_ 1025 BMS_brickVoltageStatus98 3 "SENSOR_BYPASSED" 2 "SENSOR_NOMINAL" 1 "SENSOR_BAD" 0 "SENSOR_MISSING" ;
VAL_ 1025 BMS_brickVoltageStatus99 3 "SENSOR_BYPASSED" 2 "SENSOR_NOMINAL" 1 "SENSOR_BAD" 0 "SENSOR_MISSING" ;
VAL_ 1025 BMS_brickVoltageStatus100 3 "SENSOR_BYPASSED" 2 "SENSOR_NOMINAL" 1 "SENSOR_BAD" 0 "SENSOR_MISSING" ;
VAL_ 1025 BMS_brickVoltageStatus101 3 "SENSOR_BYPASSED" 2 "SENSOR_NOMINAL" 1 "SENSOR_BAD" 0 "SENSOR_MISSING" ;
VAL_ 1025 BMS_brickVoltageStatus102 3 "SENSOR_BYPASSED" 2 "SENSOR_NOMINAL" 1 "SENSOR_BAD" 0 "SENSOR_MISSING" ;
VAL_ 1025 BMS_brickVoltageStatus103 3 "SENSOR_BYPASSED" 2 "SENSOR_NOMINAL" 1 "SENSOR_BAD" 0 "SENSOR_MISSING" ;
VAL_ 1025 BMS_brickVoltageStatus104 3 "SENSOR_BYPASSED" 2 "SENSOR_NOMINAL" 1 "SENSOR_BAD" 0 "SENSOR_MISSING" ;
VAL_ 1025 BMS_brickVoltageStatus105 3 "SENSOR_BYPASSED" 2 "SENSOR_NOMINAL" 1 "SENSOR_BAD" 0 "SENSOR_MISSING" ;
VAL_ 1025 BMS_brickVoltageStatus106 3 "SENSOR_BYPASSED" 2 "SENSOR_NOMINAL" 1 "SENSOR_BAD" 0 "SENSOR_MISSING" ;
VAL_ 1025 BMS_brickVoltageStatus107 3 "SENSOR_BYPASSED" 2 "SENSOR_NOMINAL" 1 "SENSOR_BAD" 0 "SENSOR_MISSING" ;
VAL_ 1025 BMS_brickVoltageStatus108 3 "SENSOR_BYPASSED" 2 "SENSOR_NOMINAL" 1 "SENSOR_BAD" 0 "SENSOR_MISSING" ;
VAL_ 1138 BMS_acChargePowerSample 255 "SNA" ;
VAL_ 1138 BMS_userChargeCurrentLimitMode 4 "USR_CHG_LIMIT_EVSE_RELOCATION_RECOMMENDED" 3 "USR_CHG_LIMIT_HIGH_SOC" 2 "USR_CHG_LIMIT_BATT_TEMP_LOW" 1 "USR_CHG_LIMIT_EVSE" 0 "USR_CHG_LIMIT_NONE" ;
VAL_ 1138 BMS_chargeCurrentLimitMode 20 "CHG_LIMIT_RIPPLE_HEAT_ACTIVE" 19 "CHG_LIMIT_NEAR_HWOT_LIMIT" 18 "CHG_LIMIT_LIMP_MODE" 17 "CHG_LIMIT_MISSING_CELL" 16 "CHG_LIMIT_CAC_IMBALANCE" 15 "CHG_LIMIT_PCS_IMPLICIT" 14 "CHG_LIMIT_EVSE_IMPLICIT" 13 "CHG_LIMIT_RAMP_UP_PHASE" 12 "CHG_LIMIT_HVAC_COOLING" 11 "CHG_LIMIT_HV_CHAIN" 10 "CHG_LIMIT_CONFIG" 9 "CHG_LIMIT_TETHERING" 8 "CHG_LIMIT_LEAKY_BUCKET" 7 "CHG_LIMIT_BRICK_VOLTAGE_REG" 6 "CHG_LIMIT_BRICK_TEMP_TOO_COLD" 5 "CHG_LIMIT_BRICK_TEMP_TOO_HOT" 4 "CHG_LIMIT_BRICK_TEMP_OPTIMAL_CELL_PROFILE" 3 "CHG_LIMIT_CP" 2 "CHG_LIMIT_PCS" 1 "CHG_LIMIT_EVSE" 0 "CHG_LIMIT_NONE" ;
VAL_ 1138 BMS_timeToFinishHeatForCharge 127 "SNA" 126 "CALCULATING" ;
VAL_ 1138 BMS_timeToTripPlanChargingTarget 2047 "SNA" ;
VAL_ 1071 BMS_v2xSoe 65535 "SNA" ;
VAL_ 1071 BMS_v2xFullEnergy 4095 "SNA" ;
VAL_ 1071 BMS_v2xPackPower 511 "SNA" ;
VAL_ 1071 BMS_acDischargeBlockedReason 41 "PRECHARGE_NOT_COMPLETE" 40 "EVSE_OUTPUT_CURRENT_NOT_LOW" 39 "ALL_RETRIES_EXHAUSTED" 38 "TEMP_TOO_LOW" 37 "FEATURE_DISABLED" 36 "SOE_TOO_LOW" 35 "AC_RELAYS_NOT_OPEN" 34 "PCS_NOT_DISABLED" 33 "CP_INLET_STILL_ENERGIZED" 32 "PCS_NOT_ENABLED" 31 "CP_NOT_ENABLED" 30 "CP_NOT_READY" 29 "SYSTEM_NOT_ENABLED" 28 "PCS_DISALLOWS" 27 "CP_DISALLOWS" 26 "SYSTEM_NOT_ALLOWED" 25 "SYSTEM_NOT_POSSIBLE" 24 "PCS_GRACEFUL_SHUTDOWN_REQUESTED" 23 "CP_GRACEFUL_SHUTDOWN_REQUESTED" 22 "NOT_NEEDED_OR_WANTED" 21 "EVSE_NOT_READY" 20 "EVSE_NOT_PRESENT" 19 "STATE_TIMEOUT_EXPIRED" 18 "FC_LINK_NOT_READY" 17 "FC_CONTACTORS_NOT_CLOSED" 16 "FC_CONTACTORS_NOT_OPEN" 15 "EVSE_NOT_COMPATIBLE" 14 "FC_LINK_NOT_ALLOWED_TO_ENERGIZE" 13 "ABORT_SUPERDISCHARGE_ALERT_SET" 12 "ABORT_CHARGE_ALERT_SET" 11 "PCS_ESCALATED_SHUTDOWN_REQUESTED" 10 "CP_ESCALATED_SHUTDOWN_REQUESTED" 7 "POWERSHARE_PROTECTION_TRIPPED" 6 "SYSTEM_DIRECTOR_FAULT_REQUESTED" 5 "CP_FAULT_LINE_ASSERTED" 4 "PCS_EMERGENCY_SHUTDOWN_REQUESTED" 3 "CP_EMERGENCY_SHUTDOWN_REQUESTED" 2 "PCS_MIA" 1 "CP_MIA" 0 "COND_NONE" ;
VAL_ 1071 BMS_backupTimeRemaining 255 "SNA" ;
VAL_ 669 CP_evseDeratingReason 31 "EVSE_DERATING_INVALID" 2 "EVSE_DERATING_POST_SYSTEM_FAULT" 1 "EVSE_DERATING_CABLE_TEMP_FOLDBACK" 0 "EVSE_DERATING_NONE" ;
VAL_ 541 CP_proximity 3 "CHG_PROXIMITY_LATCHED" 2 "CHG_PROXIMITY_UNLATCHED" 1 "CHG_PROXIMITY_DISCONNECTED" 0 "CHG_PROXIMITY_SNA" ;
VAL_ 541 CP_pilot 7 "CHG_PILOT_SNA" 6 "CHG_PILOT_UNUSED_6" 5 "CHG_PILOT_INVALID" 4 "CHG_PILOT_IDLE" 3 "CHG_PILOT_FAST_CHARGE" 2 "CHG_PILOT_LINE_CHARGE" 1 "CHG_PILOT_FAULTED" 0 "CHG_PILOT_NONE" ;
VAL_ 541 CP_cableType 5 "CHG_CABLE_TYPE_SNA" 4 "CHG_CABLE_TYPE_MCS" 3 "CHG_CABLE_TYPE_GB_DC" 2 "CHG_CABLE_TYPE_GB_AC" 1 "CHG_CABLE_TYPE_SAE" 0 "CHG_CABLE_TYPE_IEC" ;
VAL_ 541 CP_iecPilotState 9 "IEC_PILOT_SNA" 8 "IEC_PILOT_NUM" 7 "IEC_PILOT_F" 6 "IEC_PILOT_E" 5 "IEC_PILOT_C3" 4 "IEC_PILOT_C2" 3 "IEC_PILOT_C1" 2 "IEC_PILOT_B3" 1 "IEC_PILOT_B2" 0 "IEC_PILOT_B1" ;
VAL_ 541 CP_teslaSwcanState 8 "TESLA_SWCAN_V2L_ESTABLISHED" 7 "TESLA_SWCAN_V2L_RECEIVE" 6 "TESLA_SWCAN_OFFBOARD_UPDATE_IN_PROGRESS" 5 "TESLA_SWCAN_GO_TO_SLEEP" 4 "TESLA_SWCAN_FAULT" 3 "TESLA_SWCAN_ESTABLISHED" 2 "TESLA_SWCAN_RECEIVE" 1 "TESLA_SWCAN_ACCEPT" 0 "TESLA_SWCAN_INACTIVE" ;
VAL_ 541 CP_evseChargeType_UI 2 "AC_CHARGER_PRESENT" 1 "DC_CHARGER_PRESENT" 0 "NO_CHARGER_PRESENT" ;
VAL_ 541 CP_gbState 15 "GBDC_TESTER_PRESENT" 14 "GBDC_FAULTED" 13 "GBDC_RETRY_CHARGE" 12 "GBDC_ERROR_HANDLING" 11 "GBDC_END_OF_CHARGE" 10 "GBDC_CHARGE_DISABLING" 9 "GBDC_STOP_CHARGE_REQUESTED" 8 "GBDC_CHARGING" 7 "GBDC_READY_TO_CHARGE" 6 "GBDC_VEH_PACK_PRECHARGE" 5 "GBDC_CHARGE_PARAM_CONFIG" 4 "GBDC_RECOGNITION" 3 "GBDC_HANDSHAKING_EXT_ISO" 2 "GBDC_COMMS_RECEIVED" 1 "GBDC_WAIT_FOR_COMMS" 0 "GBDC_INACTIVE" ;
VAL_ 541 CP_gbdcStopChargeReason 8 "GBDC_PARAM_MISMATCH" 7 "GBDC_SUPERCHARGER_COMMS_TIMEOUT" 6 "GBDC_LIVE_DISCONNECT" 5 "GBDC_EVSE_CRITICAL_FAULT" 4 "GBDC_EVSE_FAULT" 3 "GBDC_COMMS_TIMEOUT" 2 "GBDC_EVSE_REQUESTED" 1 "GBDC_VEH_REQUESTED" 0 "GBDC_STOP_REASON_NONE" ;
VAL_ 541 CP_gbdcFailureReason 3 "GBDC_CRITICAL_FAILURE" 2 "GBDC_SHUTDOWN_FAILURE" 1 "GBDC_ATTEMPTS_EXPIRED" 0 "GBDC_FAILURE_NONE" ;
VAL_ 541 CP_acChargeState 6 "AC_CHARGE_FAULT" 5 "AC_CHARGE_VEH_SHUTDOWN" 4 "AC_CHARGE_ONBOARD_CHARGER_SHUTDOWN" 3 "AC_CHARGE_ENABLED" 2 "AC_CHARGE_STANDBY" 1 "AC_CHARGE_CONNECTED_CHARGE_BLOCKED" 0 "AC_CHARGE_INACTIVE" ;
VAL_ 541 CP_acChargeType 3 "AC_CHARGE_TYPE_COUNT" 2 "AC_CHARGE_CCS" 1 "AC_CHARGE_SWCAN" 0 "AC_CHARGE_LEGACY" ;
VAL_ 541 CP_teslaDcState 10 "TESLA_DC_FAULT" 9 "TESLA_DC_EMERGENCY_SHUTDOWN" 8 "TESLA_DC_VEH_SHUTDOWN" 7 "TESLA_DC_EVSE_SHUTDOWN" 6 "TESLA_DC_ENABLED" 5 "TESLA_DC_EXT_PRECHARGE_ACTIVE" 4 "TESLA_DC_EXT_TEST_ACTIVE" 3 "TESLA_DC_EXT_TESTS_ENABLED" 2 "TESLA_DC_STANDBY" 1 "TESLA_DC_CONNECTED_CHARGE_BLOCKED" 0 "TESLA_DC_INACTIVE" ;
VAL_ 1001 DAS_headlightRequest 3 "DAS_HEADLIGHT_REQUEST_INVALID" 2 "DAS_HEADLIGHT_REQUEST_TAIL_LIGHTS_ONLY" 1 "DAS_HEADLIGHT_REQUEST_ON" 0 "DAS_HEADLIGHT_REQUEST_OFF" ;
VAL_ 1001 DAS_hazardLightRequest 3 "DAS_REQUEST_HAZARDS_SNA" 2 "DAS_REQUEST_HAZARDS_ON_FAST" 1 "DAS_REQUEST_HAZARDS_ON" 0 "DAS_REQUEST_HAZARDS_OFF" ;
VAL_ 1001 DAS_wiperSpeed 15 "DAS_WIPER_SPEED_INVALID" 14 "DAS_WIPER_SPEED_14" 13 "DAS_WIPER_SPEED_13" 12 "DAS_WIPER_SPEED_12" 11 "DAS_WIPER_SPEED_11" 10 "DAS_WIPER_SPEED_10" 9 "DAS_WIPER_SPEED_9" 8 "DAS_WIPER_SPEED_8" 7 "DAS_WIPER_SPEED_7" 6 "DAS_WIPER_SPEED_6" 5 "DAS_WIPER_SPEED_5" 4 "DAS_WIPER_SPEED_4" 3 "DAS_WIPER_SPEED_3" 2 "DAS_WIPER_SPEED_2" 1 "DAS_WIPER_SPEED_1" 0 "DAS_WIPER_SPEED_OFF" ;
VAL_ 1001 DAS_turnIndicatorRequest 4 "DAS_TURN_INDICATOR_DEFER" 3 "DAS_TURN_INDICATOR_CANCEL" 2 "DAS_TURN_INDICATOR_RIGHT" 1 "DAS_TURN_INDICATOR_LEFT" 0 "DAS_TURN_INDICATOR_NONE" ;
VAL_ 1001 DAS_highLowBeamDecision 3 "DAS_HIGH_BEAM_SNA" 2 "DAS_HIGH_BEAM_ON" 1 "DAS_HIGH_BEAM_OFF" 0 "DAS_HIGH_BEAM_UNDECIDED" ;
VAL_ 1001 DAS_heaterRequest 2 "DAS_HEATER_ON" 1 "DAS_HEATER_OFF" 0 "DAS_HEATER_SNA" ;
VAL_ 1001 DAS_highLowBeamOffReason 5 "HIGH_BEAM_OFF_REASON_SNA" 4 "HIGH_BEAM_OFF_REASON_HEAD_LIGHT" 3 "HIGH_BEAM_OFF_REASON_AMBIENT_LIGHT" 2 "HIGH_BEAM_OFF_REASON_MOVING_RADAR_TARGET" 1 "HIGH_BEAM_OFF_REASON_MOVING_VISION_TARGET" 0 "HIGH_BEAM_ON" ;
VAL_ 1001 DAS_mirrorFoldRequest 3 "DAS_MIRROR_REQUEST_SNA" 2 "DAS_MIRROR_REQUEST_UNFOLD" 1 "DAS_MIRROR_REQUEST_FOLD" 0 "DAS_MIRROR_REQUEST_NONE" ;
VAL_ 1001 DAS_autoWiperState 5 "DAS_AUTO_WIPER_STATE_SNA" 4 "DAS_AUTO_WIPER_STATE_FAST_CONTINUOUS" 3 "DAS_AUTO_WIPER_STATE_SLOW_CONTINUOUS" 2 "DAS_AUTO_WIPER_STATE_FAST_INTERMITTENT" 1 "DAS_AUTO_WIPER_STATE_SLOW_INTERMITTENT" 0 "DAS_AUTO_WIPER_STATE_OFF" ;
VAL_ 1001 DAS_turnIndicatorRequestReason 24 "DAS_ACTIVE_SIMULTANEOUS_LANE_CHANGE_AVOIDANCE" 23 "DAS_ACTIVE_INFEASIBLE_KINEMATICS_LANE_CHANGE" 22 "DAS_ACTIVE_STAY_OUT_OF_RIGHTMOST_LANE_LANE_CHANGE" 21 "DAS_ACTIVE_AWAY_FROM_MERGE_LANE_CHANGE" 20 "DAS_ACTIVE_EXIT_RIGHT_LANE_LANE_CHANGE" 19 "DAS_ACTIVE_EXIT_PASSING_LANE_LANE_CHANGE" 18 "DAS_ACTIVE_INCORRECT_ROAD_SIDE_LANE_CHANGE" 17 "DAS_ACTIVE_STATIC_OBJECT_LANE_CHANGE" 15 "DAS_CANCEL_MANUAL_BLINKER" 14 "DAS_CANCEL_AUTO_PARK" 13 "DAS_ACTIVE_AUTO_PARK" 12 "DAS_CANCEL_SUMMMON" 11 "DAS_ACTIVE_SUMMMON" 10 "DAS_CANCEL_INTERSECTION" 9 "DAS_ACTIVE_INTERSECTION" 8 "DAS_ACTIVE_COMMANDED_LANE_CHANGE" 7 "DAS_CANCEL_MERGE" 6 "DAS_ACTIVE_MERGE" 5 "DAS_CANCEL_FORK" 4 "DAS_CANCEL_LANE_CHANGE" 3 "DAS_ACTIVE_FORK" 2 "DAS_ACTIVE_SPEED_LANE_CHANGE" 1 "DAS_ACTIVE_NAV_LANE_CHANGE" 0 "DAS_NONE" ;
VAL_ 1001 DAS_restrictDoorReleaseLeft 1 "RESTRICT_DOOR_RELEASE_ACTIVE" 0 "RESTRICT_DOOR_RELEASE_INACTIVE" ;
VAL_ 1001 DAS_restrictDoorReleaseRight 1 "RESTRICT_DOOR_RELEASE_ACTIVE" 0 "RESTRICT_DOOR_RELEASE_INACTIVE" ;
VAL_ 634 DIF_hvilStatus 3 "SNA" 2 "CLOSED" 1 "OPEN" 0 "DISABLED" ;
VAL_ 634 DIF_hvilSupplyState 2 "ACTIVE" 1 "INACTIVE" 0 "NOT_AVAILABLE" ;
VAL_ 634 DIF_vBatQF 1 "QUALIFIED" 0 "NOT_QUALIFIED" ;
VAL_ 634 DIF_powerStageSafeState 3 "PSTG_SAFESTATE_3PS_LOW" 2 "PSTG_SAFESTATE_3PS_HIGH" 1 "PSTG_SAFESTATE_ALL_OFF" 0 "PSTG_SAFESTATE_NONE" ;
VAL_ 634 DIF_fluxState 12 "DI_FLUXSTATE_DISABLED" 11 "DI_FLUXSTATE_MAGNET_FLUX_DETECT" 10 "DI_FLUXSTATE_STATIONARY_WASTE" 9 "DI_FLUXSTATE_FAULT" 7 "DI_FLUXSTATE_VCONTROL" 6 "DI_FLUXSTATE_ICONTROL" 5 "DI_FLUXSTATE_ENABLED" 4 "DI_FLUXSTATE_FLUX_DOWN" 3 "DI_FLUXSTATE_FLUX_UP" 2 "DI_FLUXSTATE_STANDBY" 1 "DI_FLUXSTATE_TEST" 0 "DI_FLUXSTATE_START" ;
VAL_ 634 DIF_gateDriveState 4 "PSTG_GD_STATE_NOT_CONFIGURED" 3 "PSTG_GD_STATE_CONFIGURED" 2 "PSTG_GD_STATE_CONFIGURING" 1 "PSTG_GD_STATE_SELFTEST" 0 "PSTG_GD_STATE_INIT" ;
VAL_ 634 DIF_gateDriveSupplyState 3 "PSTG_GD_SUPPLY_FALLING" 2 "PSTG_GD_SUPPLY_UP" 1 "PSTG_GD_SUPPLY_RISING" 0 "PSTG_GD_SUPPLY_DOWN" ;
VAL_ 784 HVP_infoIndex 255 "END" 31 "SUBCOMPONENT_GITHASH" 30 "PACKAGE_SN_8_14" 29 "PACKAGE_SN_1_7" 27 "PACKAGE_PN_15_20" 26 "PACKAGE_PN_8_14" 25 "PACKAGE_PN_1_7" 23 "SUBCOMPONENT2" 22 "VARIANTCRC" 20 "UDS_PROTOCOL_BOOTCRC" 19 "VERSION_DEPRECATED" 18 "BOOTLOADER_GITHASH" 17 "APP_GITHASH" 16 "SUBCOMPONENT" 15 "BOOTLOADER_CRC" 14 "BOOTLOADER_SVN" 13 "APP_CRC" 11 "PCBAID_ASSYID_USAGEID" 10 "BUILD_HWID_COMPONENTID" 9 "DEPRECATED_9" 8 "DEPRECATED_8" 7 "DEPRECATED_7" 6 "DEPRECATED_6" 5 "DEPRECATED_5" 4 "DEPRECATED_4" 3 "DEPRECATED_3" 2 "DEPRECATED_2" 1 "DEPRECATED_1" 0 "DEPRECATED_0" ;
VAL_ 784 HVP_buildType 4 "INFO_MFG_BUILD" 3 "INFO_TRACEABLE_CI_BUILD" 2 "INFO_LOCAL_BUILD" 1 "INFO_PLATFORM_BUILD" 0 "INFO_UNKNOWN_BUILD" ;
VAL_ 941 ICR_infoIndex 255 "END" 31 "SUBCOMPONENT_GITHASH" 30 "PACKAGE_SN_8_14" 29 "PACKAGE_SN_1_7" 27 "PACKAGE_PN_15_20" 26 "PACKAGE_PN_8_14" 25 "PACKAGE_PN_1_7" 23 "SUBCOMPONENT2" 22 "VARIANTCRC" 20 "UDS_PROTOCOL_BOOTCRC" 19 "VERSION_DEPRECATED" 18 "BOOTLOADER_GITHASH" 17 "APP_GITHASH" 16 "SUBCOMPONENT" 15 "BOOTLOADER_CRC" 14 "BOOTLOADER_SVN" 13 "APP_CRC" 11 "PCBAID_ASSYID_USAGEID" 10 "BUILD_HWID_COMPONENTID" 9 "DEPRECATED_9" 8 "DEPRECATED_8" 7 "DEPRECATED_7" 6 "DEPRECATED_6" 5 "DEPRECATED_5" 4 "DEPRECATED_4" 3 "DEPRECATED_3" 2 "DEPRECATED_2" 1 "DEPRECATED_1" 0 "DEPRECATED_0" ;
VAL_ 941 ICR_infoBuildType 4 "INFO_MFG_BUILD" 3 "INFO_TRACEABLE_CI_BUILD" 2 "INFO_LOCAL_BUILD" 1 "INFO_PLATFORM_BUILD" 0 "INFO_UNKNOWN_BUILD" ;
VAL_ 964 PCS_infoIndex 255 "END" 31 "SUBCOMPONENT_GITHASH" 30 "PACKAGE_SN_8_14" 29 "PACKAGE_SN_1_7" 27 "PACKAGE_PN_15_20" 26 "PACKAGE_PN_8_14" 25 "PACKAGE_PN_1_7" 23 "SUBCOMPONENT2" 22 "VARIANTCRC" 20 "UDS_PROTOCOL_BOOTCRC" 19 "VERSION_DEPRECATED" 18 "BOOTLOADER_GITHASH" 17 "APP_GITHASH" 16 "SUBCOMPONENT" 15 "BOOTLOADER_CRC" 14 "BOOTLOADER_SVN" 13 "APP_CRC" 11 "PCBAID_ASSYID_USAGEID" 10 "BUILD_HWID_COMPONENTID" 9 "DEPRECATED_9" 8 "DEPRECATED_8" 7 "DEPRECATED_7" 6 "DEPRECATED_6" 5 "DEPRECATED_5" 4 "DEPRECATED_4" 3 "DEPRECATED_3" 2 "DEPRECATED_2" 1 "DEPRECATED_1" 0 "DEPRECATED_0" ;
VAL_ 964 PCS_buildType 4 "INFO_MFG_BUILD" 3 "INFO_TRACEABLE_CI_BUILD" 2 "INFO_LOCAL_BUILD" 1 "INFO_PLATFORM_BUILD" 0 "INFO_UNKNOWN_BUILD" ;
VAL_ 816 SCCM_infoIndex 255 "END" 20 "UDS_PROTOCOL_BOOTCRC" 18 "BOOTLOADER_SVNHASH" 17 "APP_SVNHASH" 16 "SUBCOMPONENT1" 14 "BOOTLOADER_SVN" 13 "APP_CRC" 11 "PCBAID_ASSYID_USAGEID" 10 "BUILD_HWID_COMPONENTID" ;
VAL_ 816 SCCM_infoBuildType 4 "INFO_MFG_BUILD" 3 "INFO_TRACEABLE_CI_BUILD" 2 "INFO_LOCAL_BUILD" 1 "INFO_PLATFORM_BUILD" 0 "INFO_UNKNOWN_BUILD" ;
VAL_ 1657 UI_rgbEnableState 2 "AUTO" 1 "ON" 0 "OFF" ;
VAL_ 1657 UI_rgbEffectType 20 "RAMP_5000MS" 19 "RAMP_4750MS" 18 "RAMP_4500MS" 17 "RAMP_4250MS" 16 "RAMP_4000MS" 15 "RAMP_3750MS" 14 "RAMP_3500MS" 13 "RAMP_3250MS" 12 "RAMP_3000MS" 11 "RAMP_2750MS" 10 "RAMP_2500MS" 9 "RAMP_2250MS" 8 "RAMP_2000MS" 7 "RAMP_1750MS" 6 "RAMP_1500MS" 5 "RAMP_1250MS" 4 "RAMP_1000MS" 3 "RAMP_750MS" 2 "RAMP_500MS" 1 "RAMP_250MS" 0 "RAMP_INSTANT" ;
VAL_ 1657 UI_rgbBrightnessLevel 127 "SNA" ;
VAL_ 819 UI_acChargeCurrentLimit 127 "SNA" ;
VAL_ 819 UI_chargePortLatchRequest 2 "UI_LATCH_REQUEST_DISENGAGE" 1 "UI_LATCH_REQUEST_ENGAGE" 0 "UI_LATCH_REQUEST_NONE" ;
VAL_ 819 UI_cpInletHeaterRequest 2 "HEATER_MANUAL_OVERRIDE" 1 "HEATER_AUTO" 0 "HEATER_OFF" ;
VAL_ 991 UI_userActivity 1 "USER_ACTIVE" 0 "USER_IDLE" ;
VAL_ 991 UI_linkState 2 "LINK_STATE_WIFI" 1 "LINK_STATE_CELL" 0 "LINK_STATE_NONE" ;
VAL_ 991 UI_mobileAppConnected 1 "CONNECTED" 0 "NOT_CONNECTED" ;
VAL_ 991 UI_autoshiftDRState 6 "AUTOSHIFT_DR_STATE_BRAKE_GEAR_SHIFT_CONFIRMED_D" 5 "AUTOSHIFT_DR_STATE_BRAKE_GEAR_SHIFT_CONFIRMED_R" 4 "AUTOSHIFT_DR_STATE_BRAKE_STEERING_AND_BRAKE_CONFIRMED" 3 "AUTOSHIFT_DR_STATE_ONLY_STEERING_CONFIRMED" 2 "AUTOSHIFT_DR_STATE_ONLY_BRAKE_CONFIRMED" 1 "AUTOSHIFT_DR_STATE_PROMPT_SHOWING_UNCONFIRMED" 0 "AUTOSHIFT_DR_STATE_INACTIVE" ;
VAL_ 991 UI_wifiBtModuleType 4 "ELEKTRA" 3 "TCU4G" 2 "BCM4359" 1 "QCA6595" 0 "UNKNOWN" ;
VAL_ 991 UI_selfParkState 255 "SNA" 52 "SELF_PARK_USER_PAUSED" 51 "SELF_PARK_REMOTE_PRE_ABORT" 50 "SELF_PARK_RESUME" 49 "SELF_PARK_PAUSE" 48 "SELF_PARK_DV_MISMATCH" 47 "SELF_PARK_DI_PANIC" 46 "SELF_PARK_POST_ACTIVE_FAILURE" 45 "SELF_PARK_POST_ACTIVE_SUCCESS" 44 "SELF_PARK_CANCEL_AUTO_SUMMON" 43 "SELF_PARK_REMOTE_ABORT" 42 "SELF_PARK_OBSTACLE_NOT_CLEARED" 41 "SELF_PARK_OBSTACLE_CLEARED" 40 "SELF_PARK_OPEN_GATE" 39 "SELF_PARK_ACTIVE" 38 "SELF_PARK_STARTED_REVERSE" 37 "SELF_PARK_STARTED_FORWARD" 36 "SELF_PARK_NOT_STARTED_TIMEOUT" 35 "SELF_PARK_PRIMED" 34 "SELF_PARK_PREPRIMED" 33 "SELF_PARK_TURN_ON_DRIVE_RAIL" 32 "SELF_PARK_DETECT_KEY_FOB" 31 "SELF_PARK_WAKE_UP_BUSES" 30 "SELF_PARK_CONNECTING_BLUETOOTH" 29 "SELF_PARK_UNAVAILABLE_CAR_WASH_MODE" 28 "SELF_PARK_UNAVAILABLE_CAR_ALARM" 27 "SELF_PARK_UNAVAILABLE_CRASH_STATE" 26 "SELF_PARK_UNAVAILABLE_DRAG_STRIP_MODE" 25 "SELF_PARK_UNAVAILABLE_TRACK_MODE" 24 "SELF_PARK_UNAVAILABLE_SERVICE_MODE" 23 "SELF_PARK_UNAVAILABLE_DOG_MODE" 22 "SELF_PARK_UNAVAILABLE_GAME_MODE" 21 "SELF_PARK_UNAVAILABLE_BLUETOOTH_CONNECT_TIMEOUT" 20 "SELF_PARK_UNAVAILABLE_WAKEUP_TIMEOUT" 19 "SELF_PARK_UNAVAILABLE_NO_BLUETOOTH_DEVICES_PAIRED" 18 "SELF_PARK_UNAVAILABLE_BRAKE_PRESSED" 17 "SELF_PARK_UNAVAILABLE_ROAD_GRADE" 16 "SELF_PARK_UNAVAILABLE_TRAILER_MODE" 15 "SELF_PARK_UNAVAILABLE_KEY_FOB_BATTERY_LOW" 14 "SELF_PARK_UNAVAILABLE_KEY_FOB_NOT_DETECTED" 13 "SELF_PARK_UNAVAILABLE_PARK_SENSOR_ISSUE" 12 "SELF_PARK_UNAVAILABLE_AUTOSTEER_NOT_ENABLED" 11 "SELF_PARK_UNAVAILABLE_LV_BUS_SUPPORT_ISSUE" 10 "SELF_PARK_UNAVAILABLE_ON_PUBLIC_ROAD" 9 "SELF_PARK_UNAVAILABLE_PARKED_TOO_LONG" 8 "SELF_PARK_UNAVAILABLE_DOOR_OPEN" 7 "SELF_PARK_UNAVAILABLE_TRUNK_OPEN" 6 "SELF_PARK_UNAVAILABLE_FRUNK_OPEN" 5 "SELF_PARK_UNAVAILABLE_PLUGGED_IN" 4 "SELF_PARK_UNAVAILABLE_NOT_PARKED" 3 "SELF_PARK_UNAVAILABLE" 2 "SELF_PARK_IDLE" 1 "SELF_PARK_DRIVING" 0 "SELF_PARK_DISABLED" ;
VAL_ 991 UI_summonDeviceIndex 3 "UNKNOWN" 2 "DEVICE_2" 1 "DEVICE_1" 0 "DEVICE_0" ;
VAL_ 663 UI_adaptiveRideRequest 3 "ADAPTIVE_RIDE_REQUEST_ADVANCED" 2 "ADAPTIVE_RIDE_REQUEST_SPORT" 1 "ADAPTIVE_RIDE_REQUEST_AUTO" 0 "ADAPTIVE_RIDE_REQUEST_COMFORT" ;
VAL_ 663 UI_geofenceLevelingRequest 5 "GEOFENCE_LEVELING_REQUEST_SNA" 4 "GEOFENCE_LEVELING_REQUEST_VERY_HIGH_PERSIST" 3 "GEOFENCE_LEVELING_REQUEST_HIGH_PERSIST" 2 "GEOFENCE_LEVELING_REQUEST_VERY_HIGH_TEMPORARY" 1 "GEOFENCE_LEVELING_REQUEST_HIGH_TEMPORARY" 0 "GEOFENCE_LEVELING_REQUEST_NONE" ;
VAL_ 947 UI_lightSwitch 4 "LIGHT_SWITCH_SNA" 3 "LIGHT_SWITCH_OFF" 2 "LIGHT_SWITCH_PARKING" 1 "LIGHT_SWITCH_ON" 0 "LIGHT_SWITCH_AUTO" ;
VAL_ 947 UI_autopilotPowerStateRequest 2 "AUTOPILOT_SUSPEND" 1 "AUTOPILOT_SENTRY" 0 "AUTOPILOT_NOMINAL" ;
VAL_ 947 UI_frontLeftSeatFanReq 3 "FAN_REQUEST_LEVEL3" 2 "FAN_REQUEST_LEVEL2" 1 "FAN_REQUEST_LEVEL1" 0 "FAN_REQUEST_OFF" ;
VAL_ 947 UI_frontRightSeatFanReq 3 "FAN_REQUEST_LEVEL3" 2 "FAN_REQUEST_LEVEL2" 1 "FAN_REQUEST_LEVEL1" 0 "FAN_REQUEST_OFF" ;
VAL_ 947 UI_3RLeftSeatHeatReq 3 "HEATER_REQUEST_LEVEL3" 2 "HEATER_REQUEST_LEVEL2" 1 "HEATER_REQUEST_LEVEL1" 0 "HEATER_REQUEST_OFF" ;
VAL_ 947 UI_3RRightSeatHeatReq 3 "HEATER_REQUEST_LEVEL3" 2 "HEATER_REQUEST_LEVEL2" 1 "HEATER_REQUEST_LEVEL1" 0 "HEATER_REQUEST_OFF" ;
VAL_ 1090 VCBATT_pcsInterfaceMuxIndex 1 "1" 0 "0" ;
VAL_ 1090 VCBATT_pcsResistanceFiltered 65535 "SNA" ;
VAL_ 1027 VCFRONT1_eFuseDebugStatusIndex 5 "BRIDGE" 4 "BRAKE_MOTOR_ECU_2" 3 "AUTOPILOT_2" 2 "PCS" 1 "RIGHT_CONTROLLER" 0 "EPAS2" ;
VAL_ 1027 VCFRONT1_EPAS2EFuseState 7 "SELF_TEST" 6 "SELF_TEST_PREP" 5 "FAILSAFE" 4 "LOCKED" 3 "UNLOCKED" 2 "CONFIGURATION" 1 "WAKEUP" 0 "STANDBY" ;
VAL_ 1027 VCFRONT1_EPAS2EFuseManagerState 8 "LOCKOUT" 7 "IDLE" 6 "UNLOCKING" 5 "LOCKED_ON_BOOT" 4 "LOCKING" 3 "STANDBY" 2 "WAKEUP" 1 "OFF" 0 "RESETTING" ;
VAL_ 1027 VCFRONT1_EPAS2EFuseHardShortThre 15 "160_MV" 14 "139_3_MV" 13 "121_3_MV" 12 "105_6_MV" 11 "91_9_MV" 10 "80_MV" 9 "69_6_MV" 8 "60_6_MV" 7 "52_8_MV" 6 "45_9_MV" 5 "40_MV" 4 "34_8_MV" 3 "30_3_MV" 2 "26_4_MV" 1 "23_MV" 0 "20_MV" ;
VAL_ 1027 VCFRONT1_EPAS2EFuseOCThreshold 31 "89_3_MV" 30 "78_8_MV" 29 "69_5_MV" 28 "61_3_MV" 27 "54_MV" 26 "50_6_MV" 25 "47_5_MV" 24 "44_5_MV" 23 "41_7_MV" 22 "39_1_MV" 21 "36_6_MV" 20 "34_3_MV" 19 "32_2_MV" 18 "30_1_MV" 17 "28_2_MV" 16 "26_5_MV" 15 "24_8_MV" 14 "23_3_MV" 13 "21_8_MV" 12 "20_4_MV" 11 "19_1_MV" 10 "17_9_MV" 9 "16_8_MV" 8 "15_8_MV" 7 "14_8_MV" 6 "13_8_MV" 5 "13_MV" 4 "11_8_MV" 3 "10_4_MV" 2 "8_7_MV" 1 "7_2_MV" 0 "6_MV" ;
VAL_ 1027 VCFRONT1_EPAS2EFuseType 2 "VNF1248" 1 "VNF1048" 0 "UNKNOWN" ;
VAL_ 1027 VCFRONT1_rightControllerEFuseSta 7 "SELF_TEST" 6 "SELF_TEST_PREP" 5 "FAILSAFE" 4 "LOCKED" 3 "UNLOCKED" 2 "CONFIGURATION" 1 "WAKEUP" 0 "STANDBY" ;
VAL_ 1027 VCFRONT1_rightControllerEFuseMan 8 "LOCKOUT" 7 "IDLE" 6 "UNLOCKING" 5 "LOCKED_ON_BOOT" 4 "LOCKING" 3 "STANDBY" 2 "WAKEUP" 1 "OFF" 0 "RESETTING" ;
VAL_ 1027 VCFRONT1_rightControllerEFuseHar 15 "160_MV" 14 "139_3_MV" 13 "121_3_MV" 12 "105_6_MV" 11 "91_9_MV" 10 "80_MV" 9 "69_6_MV" 8 "60_6_MV" 7 "52_8_MV" 6 "45_9_MV" 5 "40_MV" 4 "34_8_MV" 3 "30_3_MV" 2 "26_4_MV" 1 "23_MV" 0 "20_MV" ;
VAL_ 1027 VCFRONT1_rightControllerEFuseOCT 31 "89_3_MV" 30 "78_8_MV" 29 "69_5_MV" 28 "61_3_MV" 27 "54_MV" 26 "50_6_MV" 25 "47_5_MV" 24 "44_5_MV" 23 "41_7_MV" 22 "39_1_MV" 21 "36_6_MV" 20 "34_3_MV" 19 "32_2_MV" 18 "30_1_MV" 17 "28_2_MV" 16 "26_5_MV" 15 "24_8_MV" 14 "23_3_MV" 13 "21_8_MV" 12 "20_4_MV" 11 "19_1_MV" 10 "17_9_MV" 9 "16_8_MV" 8 "15_8_MV" 7 "14_8_MV" 6 "13_8_MV" 5 "13_MV" 4 "11_8_MV" 3 "10_4_MV" 2 "8_7_MV" 1 "7_2_MV" 0 "6_MV" ;
VAL_ 1027 VCFRONT1_rightControllerEFuseTyp 2 "VNF1248" 1 "VNF1048" 0 "UNKNOWN" ;
VAL_ 1027 VCFRONT1_autopilot2EFuseState 7 "SELF_TEST" 6 "SELF_TEST_PREP" 5 "FAILSAFE" 4 "LOCKED" 3 "UNLOCKED" 2 "CONFIGURATION" 1 "WAKEUP" 0 "STANDBY" ;
VAL_ 1027 VCFRONT1_autopilot2EFuseManagerS 8 "LOCKOUT" 7 "IDLE" 6 "UNLOCKING" 5 "LOCKED_ON_BOOT" 4 "LOCKING" 3 "STANDBY" 2 "WAKEUP" 1 "OFF" 0 "RESETTING" ;
VAL_ 1027 VCFRONT1_autopilot2EFuseHardShor 15 "160_MV" 14 "139_3_MV" 13 "121_3_MV" 12 "105_6_MV" 11 "91_9_MV" 10 "80_MV" 9 "69_6_MV" 8 "60_6_MV" 7 "52_8_MV" 6 "45_9_MV" 5 "40_MV" 4 "34_8_MV" 3 "30_3_MV" 2 "26_4_MV" 1 "23_MV" 0 "20_MV" ;
VAL_ 1027 VCFRONT1_autopilot2EFuseOCThresh 31 "89_3_MV" 30 "78_8_MV" 29 "69_5_MV" 28 "61_3_MV" 27 "54_MV" 26 "50_6_MV" 25 "47_5_MV" 24 "44_5_MV" 23 "41_7_MV" 22 "39_1_MV" 21 "36_6_MV" 20 "34_3_MV" 19 "32_2_MV" 18 "30_1_MV" 17 "28_2_MV" 16 "26_5_MV" 15 "24_8_MV" 14 "23_3_MV" 13 "21_8_MV" 12 "20_4_MV" 11 "19_1_MV" 10 "17_9_MV" 9 "16_8_MV" 8 "15_8_MV" 7 "14_8_MV" 6 "13_8_MV" 5 "13_MV" 4 "11_8_MV" 3 "10_4_MV" 2 "8_7_MV" 1 "7_2_MV" 0 "6_MV" ;
VAL_ 1027 VCFRONT1_autopilot2EFuseType 2 "VNF1248" 1 "VNF1048" 0 "UNKNOWN" ;
VAL_ 609 VCFRONT_12VBatteryStatusIndex 5 "Mux5" 4 "Mux4" 3 "Mux3" 2 "Mux2" 1 "Mux1" 0 "Mux0" ;
VAL_ 609 VCFRONT_batterySMState 10 "BATTERY_SM_STATE_EXTERNAL_LV_BUS_CONTROL" 9 "BATTERY_SM_STATE_RECOVERY" 8 "BATTERY_SM_STATE_FAULT" 7 "BATTERY_SM_STATE_SHORTED_CELL_TEST" 6 "BATTERY_SM_STATE_DISCONNECTED_BATTERY_TEST" 5 "BATTERY_SM_STATE_OTA_STANDBY" 4 "BATTERY_SM_STATE_RESISTANCE_ESTIMATION" 3 "BATTERY_SM_STATE_STANDBY" 2 "BATTERY_SM_STATE_DISCHARGE" 1 "BATTERY_SM_STATE_CHARGE" 0 "BATTERY_SM_STATE_INIT" ;
VAL_ 609 VCFRONT_eFuseRecoveryStateDBG 4 "VC_LVBMB_EFUSE_RECOVERY_STATE_BLOCKED" 3 "VC_LVBMB_EFUSE_RECOVERY_STATE_FINISH" 2 "VC_LVBMB_EFUSE_RECOVERY_STATE_CONNECT" 1 "VC_LVBMB_EFUSE_RECOVERY_STATE_SETUP" 0 "VC_LVBMB_EFUSE_RECOVERY_STATE_INACTIVE" ;
VAL_ 609 VCFRONT_batteryLINScheduleDBG 7 "VC_LVBMS_LIN_SCHEDULE_SNA" 6 "VC_LVBMS_LIN_SCHEDULE_OTHER" 4 "VC_LVBMS_LIN_SCHEDULE_DEFAULT_2" 3 "VC_LVBMS_LIN_SCHEDULE_DEFAULT_1" 2 "VC_LVBMS_LIN_SCHEDULE_DIAGNOSTIC" 1 "VC_LVBMS_LIN_SCHEDULE_RESET" 0 "VC_LVBMS_LIN_SCHEDULE_OFF" ;
VAL_ 609 VCFRONT_IBSVoltage 4095 "SNA" ;
VAL_ 609 VCFRONT_IBSTemperature 2047 "IBS_TEMPERATURE_SNA" ;
VAL_ 609 VCFRONT_LVBatteryStatusForDrive 2 "LV_BATTERY_EXIT_DRIVE_REQUESTED" 1 "LV_BATTERY_READY_FOR_DRIVE" 0 "LV_BATTERY_NOT_READY_FOR_DRIVE" ;
VAL_ 609 VCFRONT_LVBatteryType 5 "LV_BATTERY_TYPE_TESLA_48V_LI_ION" 4 "LV_BATTERY_TYPE_TESLA_16V_LI_ION" 3 "LV_BATTERY_TYPE_CATL_LI_ION" 2 "LV_BATTERY_TYPE_CLARIOS_B24_FLOODED" 1 "LV_BATTERY_TYPE_ATLASBX_B24_FLOODED" 0 "LV_BATTERY_TYPE_UNKNOWN" ;
VAL_ 609 VCFRONT_IBSVoltageFiltered 16383 "SNA" 16382 "MAX" 16381 "MIN" ;
VAL_ 609 VCFRONT_LVBMS_LVBusVoltageSource 3 "VC_LVBMS_VOLTAGE_SOURCE_LVBMS" 2 "VC_LVBMS_VOLTAGE_SOURCE_VBAT_MONITOR" 1 "VC_LVBMS_VOLTAGE_SOURCE_IBS" 0 "VC_LVBMS_VOLTAGE_SOURCE_NONE" ;
VAL_ 609 VCFRONT_LVBMS_LVPackCurrentSourc 2 "VC_LV_PACK_CURRENT_SOURCE_LVBMS" 1 "VC_LV_PACK_CURRENT_SOURCE_IBS" 0 "VC_LV_PACK_CURRENT_SOURCE_NONE" ;
VAL_ 609 VCFRONT_LVBatterySupportRqrdTrig 14336 "LV_BATTERY_SUPPORT_REQUIRED_TRIGGER_SOC_IMBALANCE_AND_CORRECTION" 12288 "LV_BATTERY_SUPPORT_REQUIRED_TRIGGER_IMBALANCE_AND_CORRECTION" 10240 "LV_BATTERY_SUPPORT_REQUIRED_TRIGGER_SOC_AND_CORRECTION" 8192 "LV_BATTERY_SUPPORT_REQUIRED_TRIGGER_CORRECTION" 6144 "LV_BATTERY_SUPPORT_REQUIRED_TRIGGER_SOC_AND_IMBALANCE" 4096 "LV_BATTERY_SUPPORT_REQUIRED_TRIGGER_IMBALANCE" 2048 "LV_BATTERY_SUPPORT_REQUIRED_TRIGGER_SOC" 1024 "LV_BATTERY_SUPPORT_REQUIRED_TRIGGER_POST_OTA" 512 "LV_BATTERY_SUPPORT_REQUIRED_TRIGGER_EXIT_TRANSPORT_MODE" 256 "LV_BATTERY_SUPPORT_REQUIRED_TRIGGER_POWER_ON_RESET" 128 "LV_BATTERY_SUPPORT_REQUIRED_TRIGGER_PERIODIC_CHARGE" 64 "LV_BATTERY_SUPPORT_REQUIRED_TRIGGER_AH_COUNT" 32 "LV_BATTERY_SUPPORT_REQUIRED_TRIGGER_UNKNOWN_VOLTAGE" 20 "LV_BATTERY_SUPPORT_REQUIRED_TRIGGER_RAW_VC_VOLTAGES" 16 "LV_BATTERY_SUPPORT_REQUIRED_TRIGGER_VBAT_RAW_VOLTAGE" 12 "LV_BATTERY_SUPPORT_REQUIRED_TRIGGER_RAW_BATTERY_VOLTAGES" 10 "LV_BATTERY_SUPPORT_REQUIRED_TRIGGER_PACK_VOLTAGES" 8 "LV_BATTERY_SUPPORT_REQUIRED_TRIGGER_PACK_RAW_VOLTAGE" 5 "LV_BATTERY_SUPPORT_REQUIRED_TRIGGER_IBS_VOLTAGES" 4 "LV_BATTERY_SUPPORT_REQUIRED_TRIGGER_IBS_RAW_VOLTAGE" 3 "LV_BATTERY_SUPPORT_REQUIRED_TRIGGER_FILTERED_VOLTAGES" 2 "LV_BATTERY_SUPPORT_REQUIRED_TRIGGER_PACK_FILTERED_VOLTAGE" 1 "LV_BATTERY_SUPPORT_REQUIRED_TRIGGER_IBS_FILTERED_VOLTAGE" 0 "LV_BATTERY_SUPPORT_REQUIRED_TRIGGER_NONE" ;
VAL_ 609 VCFRONT_voltageProfile 3 "VOLTAGE_PROFILE_ALWAYS_CLOSED_CONTACTORS" 2 "VOLTAGE_PROFILE_REDUCED_FLOAT" 1 "VOLTAGE_PROFILE_FLOAT" 0 "VOLTAGE_PROFILE_CHARGE" ;
VAL_ 609 VCFRONT_IBSVoltageRawDBG 16383 "SNA" 16382 "MAX" 16381 "MIN" ;
VAL_ 609 VCFRONT_LVBusControlMode 15 "MODE_RESERVED" 9 "JUMP_POST" 8 "DISCONNECTED_BATTERY_TEST" 7 "LVBMB_EFUSE_RECOVERY" 6 "BATTERY_IMPEDANCE_TEST" 5 "LVBMB_EFUSE_TEST" 4 "BATTERY_CAPACITY_TEST" 3 "BRIDGE_MANAGER" 2 "BLOCK_LV_BATT_CHARGING" 1 "HW_PROT_SELF_TESTS" 0 "LV_BUS_IDLE" ;
